VERSION "HNNBNNNYNNNNNNNNNNNNNNNNNNNNNNNNNNNNNNNNNN/4/%%%/4/'%**4NNN///"

NS_ :

BS_:

BU_: Radar MPC2

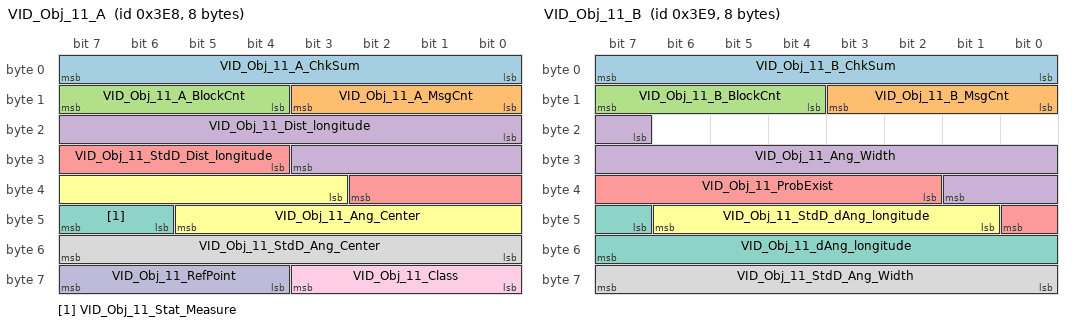
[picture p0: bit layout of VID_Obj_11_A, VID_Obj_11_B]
BO_ 1000 VID_Obj_11_A: 8 MPC2
 SG_ VID_Obj_11_A_ChkSum : 0|8@1+ (1,0) [0|255] ""  Radar
 SG_ VID_Obj_11_A_MsgCnt : 8|4@1+ (1,0) [0|15] ""  Radar
 SG_ VID_Obj_11_A_BlockCnt : 12|4@1+ (1,0) [0|15] ""  Radar
 SG_ VID_Obj_11_Dist_longitude : 16|12@1+ (0.0625,0) [0|255.875] "Unit_Meter"  Radar
 SG_ VID_Obj_11_StdD_Dist_longitude : 28|7@1+ (0.25,0) [0|31.5] "Unit_Meter"  Radar
 SG_ VID_Obj_11_Ang_Center : 35|11@1+ (0.00048828125,-0.5) [-0.5|0.4990234375] "Unit_Radia"  Radar
 SG_ VID_Obj_11_Stat_Measure : 46|2@1+ (1,0) [0|3] ""  Radar
 SG_ VID_Obj_11_StdD_Ang_Center : 48|8@1+ (0.0009765625,0) [0|0.248046875] "Unit_Radia"  Radar
 SG_ VID_Obj_11_Class : 56|4@1+ (1,0) [0|15] ""  Radar
 SG_ VID_Obj_11_RefPoint : 60|4@1+ (1,0) [0|15] ""  Radar

BO_ 1001 VID_Obj_11_B: 8 MPC2
 SG_ VID_Obj_11_B_ChkSum : 0|8@1+ (1,0) [0|255] ""  Radar
 SG_ VID_Obj_11_B_MsgCnt : 8|4@1+ (1,0) [0|15] ""  Radar
 SG_ VID_Obj_11_B_BlockCnt : 12|4@1+ (1,0) [0|15] ""  Radar
 SG_ VID_Obj_11_Ang_Width : 23|11@1+ (0.00048828125,0) [0|0.9990234375] "Unit_Radia"  Radar
 SG_ VID_Obj_11_ProbExist : 34|7@1+ (0.0078125,0.015625) [0.015625|1] ""  Radar
 SG_ VID_Obj_11_StdD_dAng_longitude : 41|6@1+ (0.01,0) [0|0.62] "Unit_RadiaPerSecon"  Radar
 SG_ VID_Obj_11_dAng_longitude : 47|9@1+ (0.005,-1.25) [-1.25|1.3] "Unit_RadiaPerSecon"  Radar
 SG_ VID_Obj_11_StdD_Ang_Width : 56|8@1+ (0.0009765625,0) [0|0.248046875] "Unit_Radia"  Radar

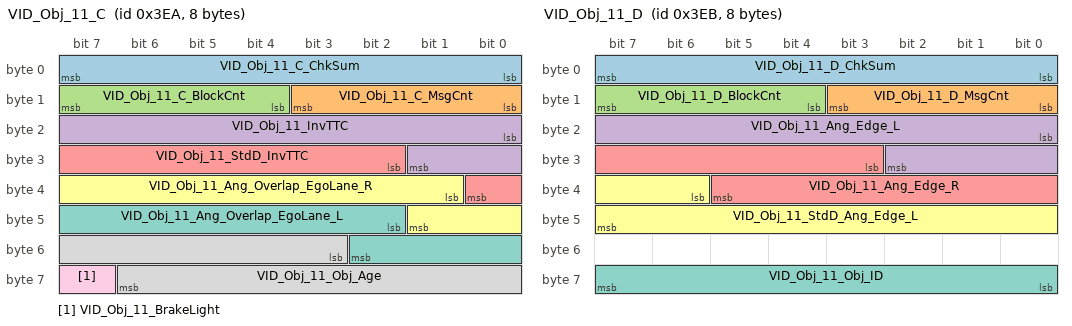
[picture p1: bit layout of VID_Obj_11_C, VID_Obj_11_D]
BO_ 1002 VID_Obj_11_C: 8 MPC2
 SG_ VID_Obj_11_C_ChkSum : 0|8@1+ (1,0) [0|255] ""  Radar
 SG_ VID_Obj_11_C_MsgCnt : 8|4@1+ (1,0) [0|15] ""  Radar
 SG_ VID_Obj_11_C_BlockCnt : 12|4@1+ (1,0) [0|15] ""  Radar
 SG_ VID_Obj_11_InvTTC : 16|10@1+ (0.015625,-8) [-8|7.96875] "Unit_Hertz"  Radar
 SG_ VID_Obj_11_StdD_InvTTC : 26|7@1+ (0.0625,0) [0|7.875] "Unit_Hertz"  Radar
 SG_ VID_Obj_11_Ang_Overlap_EgoLane_R : 33|9@1+ (0.0009765625,-0.25) [-0.25|0.248046875] "Unit_Radia"  Radar
 SG_ VID_Obj_11_Ang_Overlap_EgoLane_L : 42|9@1+ (0.0009765625,-0.25) [-0.25|0.248046875] "Unit_Radia"  Radar
 SG_ VID_Obj_11_Obj_Age : 51|12@1+ (1,0) [0|4094] ""  Radar
 SG_ VID_Obj_11_BrakeLight : 63|1@1+ (1,0) [0|1] ""  Radar

BO_ 1003 VID_Obj_11_D: 8 MPC2
 SG_ VID_Obj_11_D_ChkSum : 0|8@1+ (1,0) [0|255] ""  Radar
 SG_ VID_Obj_11_D_MsgCnt : 8|4@1+ (1,0) [0|15] ""  Radar
 SG_ VID_Obj_11_D_BlockCnt : 12|4@1+ (1,0) [0|15] ""  Radar
 SG_ VID_Obj_11_Ang_Edge_L : 16|11@1+ (0.00048828125,-0.5) [-0.5|0.49951171875] "Unit_Radia"  Radar
 SG_ VID_Obj_11_Ang_Edge_R : 27|11@1+ (0.00048828125,-0.5) [-0.5|0.49951171875] "Unit_Radia"  Radar
 SG_ VID_Obj_11_StdD_Ang_Edge_L : 38|10@1+ (0.00048828125,-0.25) [-0.25|0.24951171875] "Unit_Radia"  Radar
 SG_ VID_Obj_11_Obj_ID : 56|8@1+ (1,0) [1|254] ""  Radar

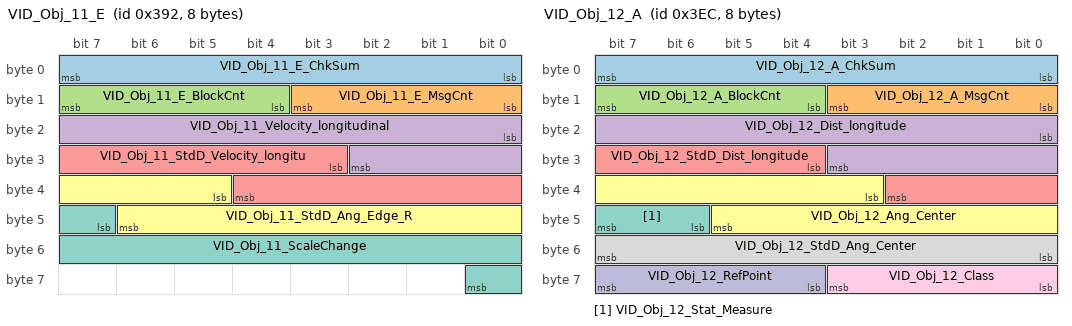
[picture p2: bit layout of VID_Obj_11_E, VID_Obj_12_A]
BO_ 914 VID_Obj_11_E: 8 MPC2
 SG_ VID_Obj_11_E_ChkSum : 0|8@1+ (1,0) [0|255] ""  Radar
 SG_ VID_Obj_11_E_MsgCnt : 8|4@1+ (1,0) [0|15] ""  Radar
 SG_ VID_Obj_11_E_BlockCnt : 12|4@1+ (1,0) [0|15] ""  Radar
 SG_ VID_Obj_11_Velocity_longitudinal : 16|11@1+ (0.01388889,-12) [-12|12.00000192] "Unit_MeterPerSecon"  Radar
 SG_ VID_Obj_11_StdD_Velocity_longitu : 27|10@1+ (0.00694444,0) [0|6.0069406] "Unit_MeterPerSecon"  Radar
 SG_ VID_Obj_11_StdD_Ang_Edge_R : 37|10@1+ (0.00048828125,-0.25) [-0.25|0.24951171875] "Unit_Radia"  Radar
 SG_ VID_Obj_11_ScaleChange : 47|10@1+ (0.001,0.5) [0.5|1.5] ""  Radar

BO_ 1004 VID_Obj_12_A: 8 MPC2
 SG_ VID_Obj_12_A_ChkSum : 0|8@1+ (1,0) [0|255] ""  Radar
 SG_ VID_Obj_12_A_MsgCnt : 8|4@1+ (1,0) [0|15] ""  Radar
 SG_ VID_Obj_12_A_BlockCnt : 12|4@1+ (1,0) [0|15] ""  Radar
 SG_ VID_Obj_12_Dist_longitude : 16|12@1+ (0.0625,0) [0|255.875] "Unit_Meter"  Radar
 SG_ VID_Obj_12_StdD_Dist_longitude : 28|7@1+ (0.25,0) [0|31.5] "Unit_Meter"  Radar
 SG_ VID_Obj_12_Ang_Center : 35|11@1+ (0.00048828125,-0.5) [-0.5|0.4990234375] "Unit_Radia"  Radar
 SG_ VID_Obj_12_Stat_Measure : 46|2@1+ (1,0) [0|3] ""  Radar
 SG_ VID_Obj_12_StdD_Ang_Center : 48|8@1+ (0.0009765625,0) [0|0.248046875] "Unit_Radia"  Radar
 SG_ VID_Obj_12_Class : 56|4@1+ (1,0) [0|15] ""  Radar
 SG_ VID_Obj_12_RefPoint : 60|4@1+ (1,0) [0|15] ""  Radar

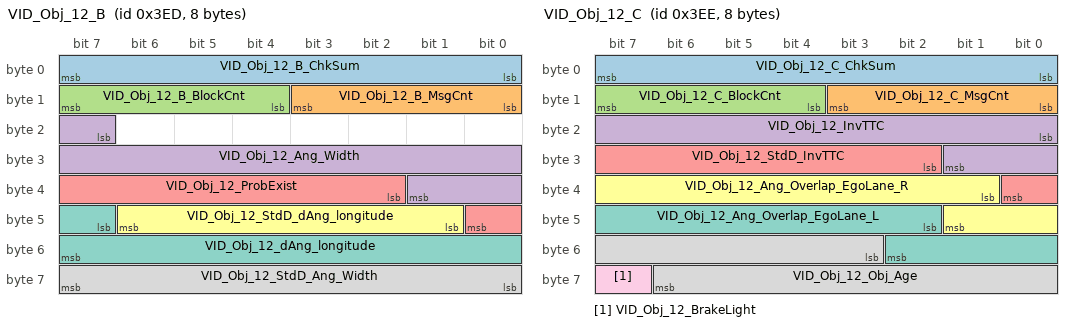
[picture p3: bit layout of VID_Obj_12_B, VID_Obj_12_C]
BO_ 1005 VID_Obj_12_B: 8 MPC2
 SG_ VID_Obj_12_B_ChkSum : 0|8@1+ (1,0) [0|255] ""  Radar
 SG_ VID_Obj_12_B_MsgCnt : 8|4@1+ (1,0) [0|15] ""  Radar
 SG_ VID_Obj_12_B_BlockCnt : 12|4@1+ (1,0) [0|15] ""  Radar
 SG_ VID_Obj_12_Ang_Width : 23|11@1+ (0.00048828125,0) [0|0.9990234375] "Unit_Radia"  Radar
 SG_ VID_Obj_12_ProbExist : 34|7@1+ (0.0078125,0.015625) [0.015625|1] ""  Radar
 SG_ VID_Obj_12_StdD_dAng_longitude : 41|6@1+ (0.01,0) [0|0.62] "Unit_RadiaPerSecon"  Radar
 SG_ VID_Obj_12_dAng_longitude : 47|9@1+ (0.005,-1.25) [-1.25|1.3] "Unit_RadiaPerSecon"  Radar
 SG_ VID_Obj_12_StdD_Ang_Width : 56|8@1+ (0.0009765625,0) [0|0.248046875] "Unit_Radia"  Radar

BO_ 1006 VID_Obj_12_C: 8 MPC2
 SG_ VID_Obj_12_C_ChkSum : 0|8@1+ (1,0) [0|255] ""  Radar
 SG_ VID_Obj_12_C_MsgCnt : 8|4@1+ (1,0) [0|15] ""  Radar
 SG_ VID_Obj_12_C_BlockCnt : 12|4@1+ (1,0) [0|15] ""  Radar
 SG_ VID_Obj_12_InvTTC : 16|10@1+ (0.015625,-8) [-8|7.96875] "Unit_Hertz"  Radar
 SG_ VID_Obj_12_StdD_InvTTC : 26|7@1+ (0.0625,0) [0|7.875] "Unit_Hertz"  Radar
 SG_ VID_Obj_12_Ang_Overlap_EgoLane_R : 33|9@1+ (0.0009765625,-0.25) [-0.25|0.248046875] "Unit_Radia"  Radar
 SG_ VID_Obj_12_Ang_Overlap_EgoLane_L : 42|9@1+ (0.0009765625,-0.25) [-0.25|0.248046875] "Unit_Radia"  Radar
 SG_ VID_Obj_12_Obj_Age : 51|12@1+ (1,0) [0|4094] ""  Radar
 SG_ VID_Obj_12_BrakeLight : 63|1@1+ (1,0) [0|1] ""  Radar

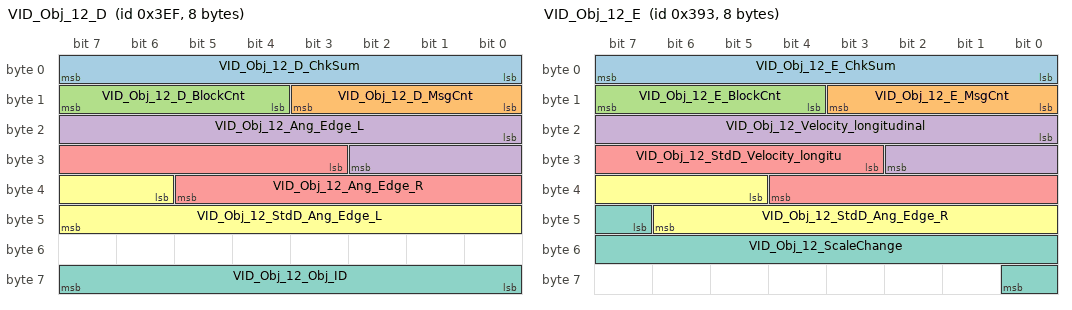
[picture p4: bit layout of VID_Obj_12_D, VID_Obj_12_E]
BO_ 1007 VID_Obj_12_D: 8 MPC2
 SG_ VID_Obj_12_D_ChkSum : 0|8@1+ (1,0) [0|255] ""  Radar
 SG_ VID_Obj_12_D_MsgCnt : 8|4@1+ (1,0) [0|15] ""  Radar
 SG_ VID_Obj_12_D_BlockCnt : 12|4@1+ (1,0) [0|15] ""  Radar
 SG_ VID_Obj_12_Ang_Edge_L : 16|11@1+ (0.00048828125,-0.5) [-0.5|0.49951171875] "Unit_Radia"  Radar
 SG_ VID_Obj_12_Ang_Edge_R : 27|11@1+ (0.00048828125,-0.5) [-0.5|0.49951171875] "Unit_Radia"  Radar
 SG_ VID_Obj_12_StdD_Ang_Edge_L : 38|10@1+ (0.00048828125,-0.25) [-0.25|0.24951171875] "Unit_Radia"  Radar
 SG_ VID_Obj_12_Obj_ID : 56|8@1+ (1,0) [1|254] ""  Radar

BO_ 915 VID_Obj_12_E: 8 MPC2
 SG_ VID_Obj_12_E_ChkSum : 0|8@1+ (1,0) [0|255] ""  Radar
 SG_ VID_Obj_12_E_MsgCnt : 8|4@1+ (1,0) [0|15] ""  Radar
 SG_ VID_Obj_12_E_BlockCnt : 12|4@1+ (1,0) [0|15] ""  Radar
 SG_ VID_Obj_12_Velocity_longitudinal : 16|11@1+ (0.01388889,-12) [-12|12.00000192] "Unit_MeterPerSecon"  Radar
 SG_ VID_Obj_12_StdD_Velocity_longitu : 27|10@1+ (0.00694444,0) [0|6.0069406] "Unit_MeterPerSecon"  Radar
 SG_ VID_Obj_12_StdD_Ang_Edge_R : 37|10@1+ (0.00048828125,-0.25) [-0.25|0.24951171875] "Unit_Radia"  Radar
 SG_ VID_Obj_12_ScaleChange : 47|10@1+ (0.001,0.5) [0.5|1.5] ""  Radar

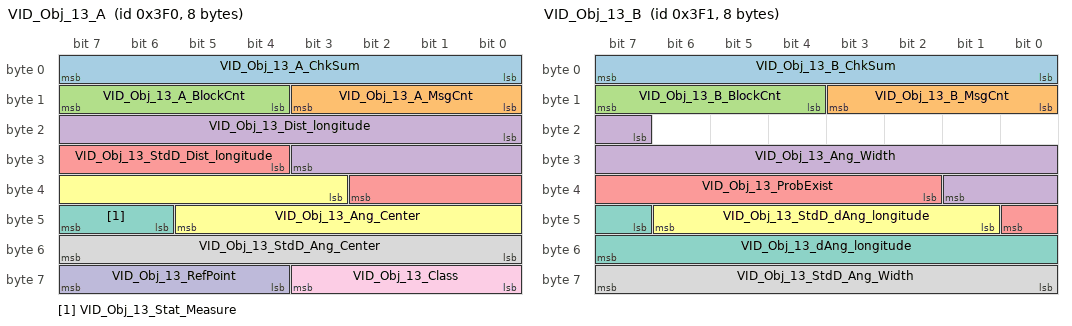
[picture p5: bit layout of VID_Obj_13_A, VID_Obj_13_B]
BO_ 1008 VID_Obj_13_A: 8 MPC2
 SG_ VID_Obj_13_A_ChkSum : 0|8@1+ (1,0) [0|255] ""  Radar
 SG_ VID_Obj_13_A_MsgCnt : 8|4@1+ (1,0) [0|15] ""  Radar
 SG_ VID_Obj_13_A_BlockCnt : 12|4@1+ (1,0) [0|15] ""  Radar
 SG_ VID_Obj_13_Dist_longitude : 16|12@1+ (0.0625,0) [0|255.875] "Unit_Meter"  Radar
 SG_ VID_Obj_13_StdD_Dist_longitude : 28|7@1+ (0.25,0) [0|31.5] "Unit_Meter"  Radar
 SG_ VID_Obj_13_Ang_Center : 35|11@1+ (0.00048828125,-0.5) [-0.5|0.4990234375] "Unit_Radia"  Radar
 SG_ VID_Obj_13_Stat_Measure : 46|2@1+ (1,0) [0|3] ""  Radar
 SG_ VID_Obj_13_StdD_Ang_Center : 48|8@1+ (0.0009765625,0) [0|0.248046875] "Unit_Radia"  Radar
 SG_ VID_Obj_13_Class : 56|4@1+ (1,0) [0|15] ""  Radar
 SG_ VID_Obj_13_RefPoint : 60|4@1+ (1,0) [0|15] ""  Radar

BO_ 1009 VID_Obj_13_B: 8 MPC2
 SG_ VID_Obj_13_B_ChkSum : 0|8@1+ (1,0) [0|255] ""  Radar
 SG_ VID_Obj_13_B_MsgCnt : 8|4@1+ (1,0) [0|15] ""  Radar
 SG_ VID_Obj_13_B_BlockCnt : 12|4@1+ (1,0) [0|15] ""  Radar
 SG_ VID_Obj_13_Ang_Width : 23|11@1+ (0.00048828125,0) [0|0.9990234375] "Unit_Radia"  Radar
 SG_ VID_Obj_13_ProbExist : 34|7@1+ (0.0078125,0.015625) [0.015625|1] ""  Radar
 SG_ VID_Obj_13_StdD_dAng_longitude : 41|6@1+ (0.01,0) [0|0.62] "Unit_RadiaPerSecon"  Radar
 SG_ VID_Obj_13_dAng_longitude : 47|9@1+ (0.005,-1.25) [-1.25|1.3] "Unit_RadiaPerSecon"  Radar
 SG_ VID_Obj_13_StdD_Ang_Width : 56|8@1+ (0.0009765625,0) [0|0.248046875] "Unit_Radia"  Radar

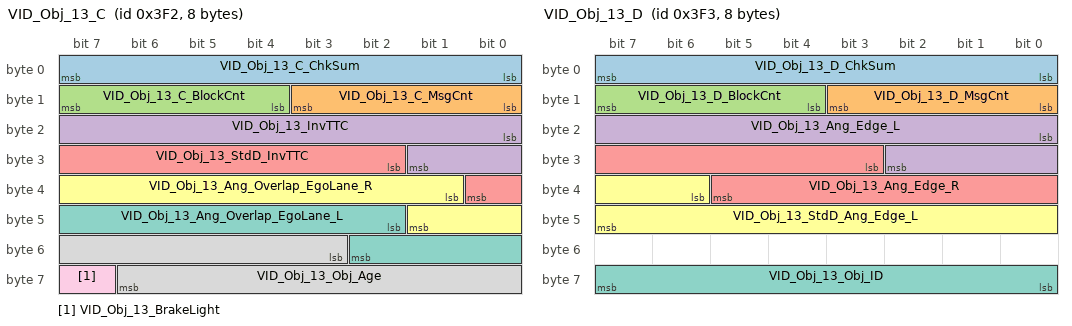
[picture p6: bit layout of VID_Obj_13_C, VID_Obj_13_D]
BO_ 1010 VID_Obj_13_C: 8 MPC2
 SG_ VID_Obj_13_C_ChkSum : 0|8@1+ (1,0) [0|255] ""  Radar
 SG_ VID_Obj_13_C_MsgCnt : 8|4@1+ (1,0) [0|15] ""  Radar
 SG_ VID_Obj_13_C_BlockCnt : 12|4@1+ (1,0) [0|15] ""  Radar
 SG_ VID_Obj_13_InvTTC : 16|10@1+ (0.015625,-8) [-8|7.96875] "Unit_Hertz"  Radar
 SG_ VID_Obj_13_StdD_InvTTC : 26|7@1+ (0.0625,0) [0|7.875] "Unit_Hertz"  Radar
 SG_ VID_Obj_13_Ang_Overlap_EgoLane_R : 33|9@1+ (0.0009765625,-0.25) [-0.25|0.248046875] "Unit_Radia"  Radar
 SG_ VID_Obj_13_Ang_Overlap_EgoLane_L : 42|9@1+ (0.0009765625,-0.25) [-0.25|0.248046875] "Unit_Radia"  Radar
 SG_ VID_Obj_13_Obj_Age : 51|12@1+ (1,0) [0|4094] ""  Radar
 SG_ VID_Obj_13_BrakeLight : 63|1@1+ (1,0) [0|1] ""  Radar

BO_ 1011 VID_Obj_13_D: 8 MPC2
 SG_ VID_Obj_13_D_ChkSum : 0|8@1+ (1,0) [0|255] ""  Radar
 SG_ VID_Obj_13_D_MsgCnt : 8|4@1+ (1,0) [0|15] ""  Radar
 SG_ VID_Obj_13_D_BlockCnt : 12|4@1+ (1,0) [0|15] ""  Radar
 SG_ VID_Obj_13_Ang_Edge_L : 16|11@1+ (0.00048828125,-0.5) [-0.5|0.49951171875] "Unit_Radia"  Radar
 SG_ VID_Obj_13_Ang_Edge_R : 27|11@1+ (0.00048828125,-0.5) [-0.5|0.49951171875] "Unit_Radia"  Radar
 SG_ VID_Obj_13_StdD_Ang_Edge_L : 38|10@1+ (0.00048828125,-0.25) [-0.25|0.24951171875] "Unit_Radia"  Radar
 SG_ VID_Obj_13_Obj_ID : 56|8@1+ (1,0) [1|254] ""  Radar

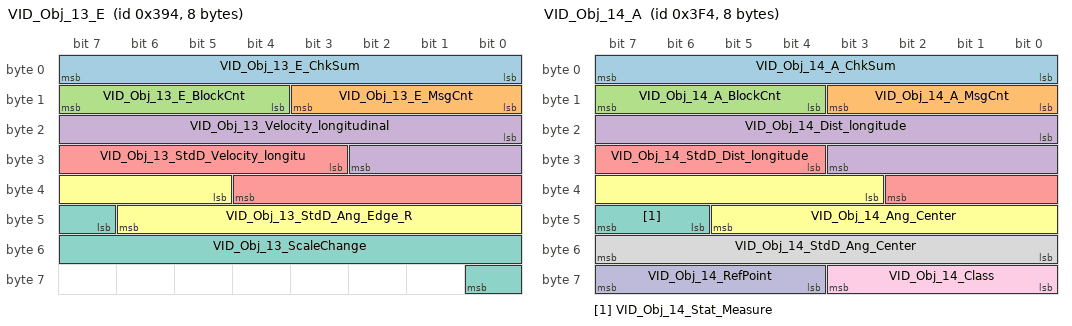
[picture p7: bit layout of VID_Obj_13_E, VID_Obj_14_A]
BO_ 916 VID_Obj_13_E: 8 MPC2
 SG_ VID_Obj_13_E_ChkSum : 0|8@1+ (1,0) [0|255] ""  Radar
 SG_ VID_Obj_13_E_MsgCnt : 8|4@1+ (1,0) [0|15] ""  Radar
 SG_ VID_Obj_13_E_BlockCnt : 12|4@1+ (1,0) [0|15] ""  Radar
 SG_ VID_Obj_13_Velocity_longitudinal : 16|11@1+ (0.01388889,-12) [-12|12.00000192] "Unit_MeterPerSecon"  Radar
 SG_ VID_Obj_13_StdD_Velocity_longitu : 27|10@1+ (0.00694444,0) [0|6.0069406] "Unit_MeterPerSecon"  Radar
 SG_ VID_Obj_13_StdD_Ang_Edge_R : 37|10@1+ (0.00048828125,-0.25) [-0.25|0.24951171875] "Unit_Radia"  Radar
 SG_ VID_Obj_13_ScaleChange : 47|10@1+ (0.001,0.5) [0.5|1.5] ""  Radar

BO_ 1012 VID_Obj_14_A: 8 MPC2
 SG_ VID_Obj_14_A_ChkSum : 0|8@1+ (1,0) [0|255] ""  Radar
 SG_ VID_Obj_14_A_MsgCnt : 8|4@1+ (1,0) [0|15] ""  Radar
 SG_ VID_Obj_14_A_BlockCnt : 12|4@1+ (1,0) [0|15] ""  Radar
 SG_ VID_Obj_14_Dist_longitude : 16|12@1+ (0.0625,0) [0|255.875] "Unit_Meter"  Radar
 SG_ VID_Obj_14_StdD_Dist_longitude : 28|7@1+ (0.25,0) [0|31.5] "Unit_Meter"  Radar
 SG_ VID_Obj_14_Ang_Center : 35|11@1+ (0.00048828125,-0.5) [-0.5|0.4990234375] "Unit_Radia"  Radar
 SG_ VID_Obj_14_Stat_Measure : 46|2@1+ (1,0) [0|3] ""  Radar
 SG_ VID_Obj_14_StdD_Ang_Center : 48|8@1+ (0.0009765625,0) [0|0.248046875] "Unit_Radia"  Radar
 SG_ VID_Obj_14_Class : 56|4@1+ (1,0) [0|15] ""  Radar
 SG_ VID_Obj_14_RefPoint : 60|4@1+ (1,0) [0|15] ""  Radar

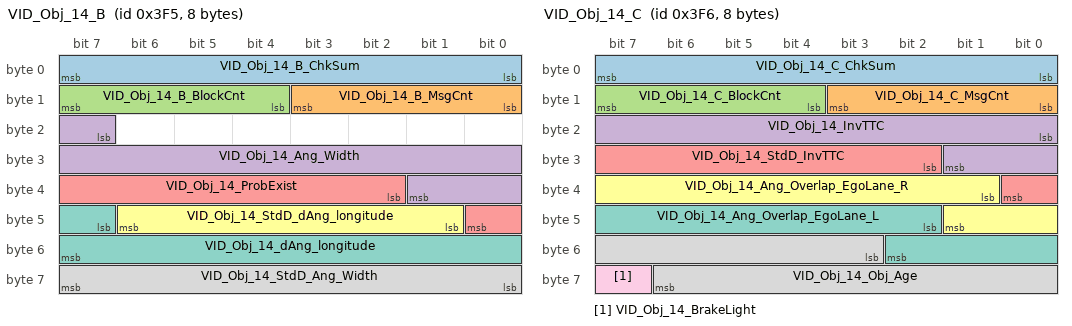
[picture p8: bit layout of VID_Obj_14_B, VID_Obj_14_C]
BO_ 1013 VID_Obj_14_B: 8 MPC2
 SG_ VID_Obj_14_B_ChkSum : 0|8@1+ (1,0) [0|255] ""  Radar
 SG_ VID_Obj_14_B_MsgCnt : 8|4@1+ (1,0) [0|15] ""  Radar
 SG_ VID_Obj_14_B_BlockCnt : 12|4@1+ (1,0) [0|15] ""  Radar
 SG_ VID_Obj_14_Ang_Width : 23|11@1+ (0.00048828125,0) [0|0.9990234375] "Unit_Radia"  Radar
 SG_ VID_Obj_14_ProbExist : 34|7@1+ (0.0078125,0.015625) [0.015625|1] ""  Radar
 SG_ VID_Obj_14_StdD_dAng_longitude : 41|6@1+ (0.01,0) [0|0.62] "Unit_RadiaPerSecon"  Radar
 SG_ VID_Obj_14_dAng_longitude : 47|9@1+ (0.005,-1.25) [-1.25|1.3] "Unit_RadiaPerSecon"  Radar
 SG_ VID_Obj_14_StdD_Ang_Width : 56|8@1+ (0.0009765625,0) [0|0.248046875] "Unit_Radia"  Radar

BO_ 1014 VID_Obj_14_C: 8 MPC2
 SG_ VID_Obj_14_C_ChkSum : 0|8@1+ (1,0) [0|255] ""  Radar
 SG_ VID_Obj_14_C_MsgCnt : 8|4@1+ (1,0) [0|15] ""  Radar
 SG_ VID_Obj_14_C_BlockCnt : 12|4@1+ (1,0) [0|15] ""  Radar
 SG_ VID_Obj_14_InvTTC : 16|10@1+ (0.015625,-8) [-8|7.96875] "Unit_Hertz"  Radar
 SG_ VID_Obj_14_StdD_InvTTC : 26|7@1+ (0.0625,0) [0|7.875] "Unit_Hertz"  Radar
 SG_ VID_Obj_14_Ang_Overlap_EgoLane_R : 33|9@1+ (0.0009765625,-0.25) [-0.25|0.248046875] "Unit_Radia"  Radar
 SG_ VID_Obj_14_Ang_Overlap_EgoLane_L : 42|9@1+ (0.0009765625,-0.25) [-0.25|0.248046875] "Unit_Radia"  Radar
 SG_ VID_Obj_14_Obj_Age : 51|12@1+ (1,0) [0|4094] ""  Radar
 SG_ VID_Obj_14_BrakeLight : 63|1@1+ (1,0) [0|1] ""  Radar

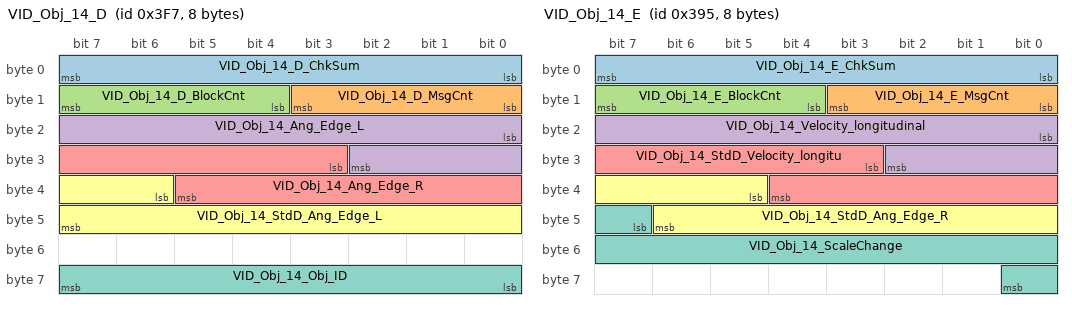
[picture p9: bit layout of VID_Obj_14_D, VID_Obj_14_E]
BO_ 1015 VID_Obj_14_D: 8 MPC2
 SG_ VID_Obj_14_D_ChkSum : 0|8@1+ (1,0) [0|255] ""  Radar
 SG_ VID_Obj_14_D_MsgCnt : 8|4@1+ (1,0) [0|15] ""  Radar
 SG_ VID_Obj_14_D_BlockCnt : 12|4@1+ (1,0) [0|15] ""  Radar
 SG_ VID_Obj_14_Ang_Edge_L : 16|11@1+ (0.00048828125,-0.5) [-0.5|0.49951171875] "Unit_Radia"  Radar
 SG_ VID_Obj_14_Ang_Edge_R : 27|11@1+ (0.00048828125,-0.5) [-0.5|0.49951171875] "Unit_Radia"  Radar
 SG_ VID_Obj_14_StdD_Ang_Edge_L : 38|10@1+ (0.00048828125,-0.25) [-0.25|0.24951171875] "Unit_Radia"  Radar
 SG_ VID_Obj_14_Obj_ID : 56|8@1+ (1,0) [1|254] ""  Radar

BO_ 917 VID_Obj_14_E: 8 MPC2
 SG_ VID_Obj_14_E_ChkSum : 0|8@1+ (1,0) [0|255] ""  Radar
 SG_ VID_Obj_14_E_MsgCnt : 8|4@1+ (1,0) [0|15] ""  Radar
 SG_ VID_Obj_14_E_BlockCnt : 12|4@1+ (1,0) [0|15] ""  Radar
 SG_ VID_Obj_14_Velocity_longitudinal : 16|11@1+ (0.01388889,-12) [-12|12.00000192] "Unit_MeterPerSecon"  Radar
 SG_ VID_Obj_14_StdD_Velocity_longitu : 27|10@1+ (0.00694444,0) [0|6.0069406] "Unit_MeterPerSecon"  Radar
 SG_ VID_Obj_14_StdD_Ang_Edge_R : 37|10@1+ (0.00048828125,-0.25) [-0.25|0.24951171875] "Unit_Radia"  Radar
 SG_ VID_Obj_14_ScaleChange : 47|10@1+ (0.001,0.5) [0.5|1.5] ""  Radar

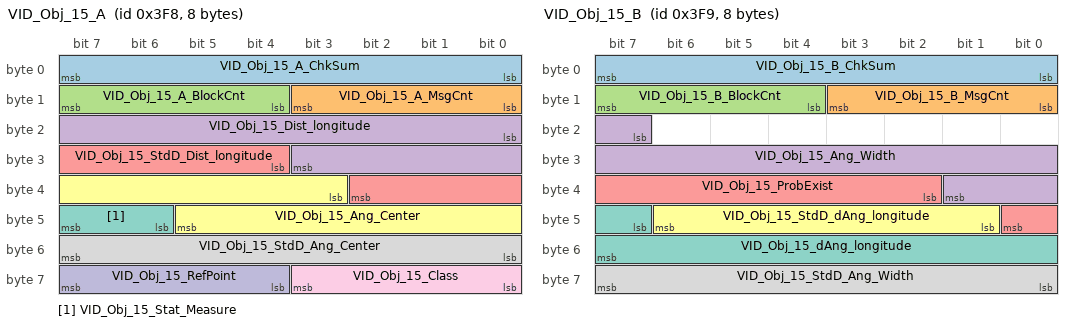
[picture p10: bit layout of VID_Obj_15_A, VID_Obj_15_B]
BO_ 1016 VID_Obj_15_A: 8 MPC2
 SG_ VID_Obj_15_A_ChkSum : 0|8@1+ (1,0) [0|255] ""  Radar
 SG_ VID_Obj_15_A_MsgCnt : 8|4@1+ (1,0) [0|15] ""  Radar
 SG_ VID_Obj_15_A_BlockCnt : 12|4@1+ (1,0) [0|15] ""  Radar
 SG_ VID_Obj_15_Dist_longitude : 16|12@1+ (0.0625,0) [0|255.875] "Unit_Meter"  Radar
 SG_ VID_Obj_15_StdD_Dist_longitude : 28|7@1+ (0.25,0) [0|31.5] "Unit_Meter"  Radar
 SG_ VID_Obj_15_Ang_Center : 35|11@1+ (0.00048828125,-0.5) [-0.5|0.4990234375] "Unit_Radia"  Radar
 SG_ VID_Obj_15_Stat_Measure : 46|2@1+ (1,0) [0|3] ""  Radar
 SG_ VID_Obj_15_StdD_Ang_Center : 48|8@1+ (0.0009765625,0) [0|0.248046875] "Unit_Radia"  Radar
 SG_ VID_Obj_15_Class : 56|4@1+ (1,0) [0|15] ""  Radar
 SG_ VID_Obj_15_RefPoint : 60|4@1+ (1,0) [0|15] ""  Radar

BO_ 1017 VID_Obj_15_B: 8 MPC2
 SG_ VID_Obj_15_B_ChkSum : 0|8@1+ (1,0) [0|255] ""  Radar
 SG_ VID_Obj_15_B_MsgCnt : 8|4@1+ (1,0) [0|15] ""  Radar
 SG_ VID_Obj_15_B_BlockCnt : 12|4@1+ (1,0) [0|15] ""  Radar
 SG_ VID_Obj_15_Ang_Width : 23|11@1+ (0.00048828125,0) [0|0.9990234375] "Unit_Radia"  Radar
 SG_ VID_Obj_15_ProbExist : 34|7@1+ (0.0078125,0.015625) [0.015625|1] ""  Radar
 SG_ VID_Obj_15_StdD_dAng_longitude : 41|6@1+ (0.01,0) [0|0.62] "Unit_RadiaPerSecon"  Radar
 SG_ VID_Obj_15_dAng_longitude : 47|9@1+ (0.005,-1.25) [-1.25|1.3] "Unit_RadiaPerSecon"  Radar
 SG_ VID_Obj_15_StdD_Ang_Width : 56|8@1+ (0.0009765625,0) [0|0.248046875] "Unit_Radia"  Radar

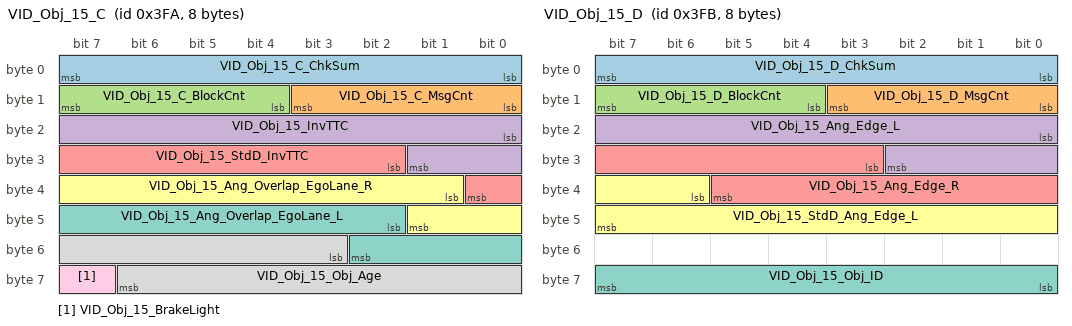
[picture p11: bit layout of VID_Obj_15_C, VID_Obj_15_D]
BO_ 1018 VID_Obj_15_C: 8 MPC2
 SG_ VID_Obj_15_C_ChkSum : 0|8@1+ (1,0) [0|255] ""  Radar
 SG_ VID_Obj_15_C_MsgCnt : 8|4@1+ (1,0) [0|15] ""  Radar
 SG_ VID_Obj_15_C_BlockCnt : 12|4@1+ (1,0) [0|15] ""  Radar
 SG_ VID_Obj_15_InvTTC : 16|10@1+ (0.015625,-8) [-8|7.96875] "Unit_Hertz"  Radar
 SG_ VID_Obj_15_StdD_InvTTC : 26|7@1+ (0.0625,0) [0|7.875] "Unit_Hertz"  Radar
 SG_ VID_Obj_15_Ang_Overlap_EgoLane_R : 33|9@1+ (0.0009765625,-0.25) [-0.25|0.248046875] "Unit_Radia"  Radar
 SG_ VID_Obj_15_Ang_Overlap_EgoLane_L : 42|9@1+ (0.0009765625,-0.25) [-0.25|0.248046875] "Unit_Radia"  Radar
 SG_ VID_Obj_15_Obj_Age : 51|12@1+ (1,0) [0|4094] ""  Radar
 SG_ VID_Obj_15_BrakeLight : 63|1@1+ (1,0) [0|1] ""  Radar

BO_ 1019 VID_Obj_15_D: 8 MPC2
 SG_ VID_Obj_15_D_ChkSum : 0|8@1+ (1,0) [0|255] ""  Radar
 SG_ VID_Obj_15_D_MsgCnt : 8|4@1+ (1,0) [0|15] ""  Radar
 SG_ VID_Obj_15_D_BlockCnt : 12|4@1+ (1,0) [0|15] ""  Radar
 SG_ VID_Obj_15_Ang_Edge_L : 16|11@1+ (0.00048828125,-0.5) [-0.5|0.49951171875] "Unit_Radia"  Radar
 SG_ VID_Obj_15_Ang_Edge_R : 27|11@1+ (0.00048828125,-0.5) [-0.5|0.49951171875] "Unit_Radia"  Radar
 SG_ VID_Obj_15_StdD_Ang_Edge_L : 38|10@1+ (0.00048828125,-0.25) [-0.25|0.24951171875] "Unit_Radia"  Radar
 SG_ VID_Obj_15_Obj_ID : 56|8@1+ (1,0) [1|254] ""  Radar

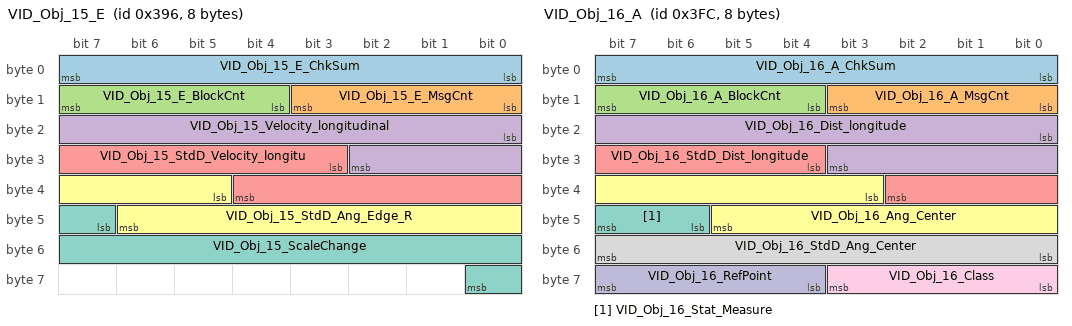
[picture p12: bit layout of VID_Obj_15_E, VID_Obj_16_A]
BO_ 918 VID_Obj_15_E: 8 MPC2
 SG_ VID_Obj_15_E_ChkSum : 0|8@1+ (1,0) [0|255] ""  Radar
 SG_ VID_Obj_15_E_MsgCnt : 8|4@1+ (1,0) [0|15] ""  Radar
 SG_ VID_Obj_15_E_BlockCnt : 12|4@1+ (1,0) [0|15] ""  Radar
 SG_ VID_Obj_15_Velocity_longitudinal : 16|11@1+ (0.01388889,-12) [-12|12.00000192] "Unit_MeterPerSecon"  Radar
 SG_ VID_Obj_15_StdD_Velocity_longitu : 27|10@1+ (0.00694444,0) [0|6.0069406] "Unit_MeterPerSecon"  Radar
 SG_ VID_Obj_15_StdD_Ang_Edge_R : 37|10@1+ (0.00048828125,-0.25) [-0.25|0.24951171875] "Unit_Radia"  Radar
 SG_ VID_Obj_15_ScaleChange : 47|10@1+ (0.001,0.5) [0.5|1.5] ""  Radar

BO_ 1020 VID_Obj_16_A: 8 MPC2
 SG_ VID_Obj_16_A_ChkSum : 0|8@1+ (1,0) [0|255] ""  Radar
 SG_ VID_Obj_16_A_MsgCnt : 8|4@1+ (1,0) [0|15] ""  Radar
 SG_ VID_Obj_16_A_BlockCnt : 12|4@1+ (1,0) [0|15] ""  Radar
 SG_ VID_Obj_16_Dist_longitude : 16|12@1+ (0.0625,0) [0|255.875] "Unit_Meter"  Radar
 SG_ VID_Obj_16_StdD_Dist_longitude : 28|7@1+ (0.25,0) [0|31.5] "Unit_Meter"  Radar
 SG_ VID_Obj_16_Ang_Center : 35|11@1+ (0.00048828125,-0.5) [-0.5|0.4990234375] "Unit_Radia"  Radar
 SG_ VID_Obj_16_Stat_Measure : 46|2@1+ (1,0) [0|3] ""  Radar
 SG_ VID_Obj_16_StdD_Ang_Center : 48|8@1+ (0.0009765625,0) [0|0.248046875] "Unit_Radia"  Radar
 SG_ VID_Obj_16_Class : 56|4@1+ (1,0) [0|15] ""  Radar
 SG_ VID_Obj_16_RefPoint : 60|4@1+ (1,0) [0|15] ""  Radar

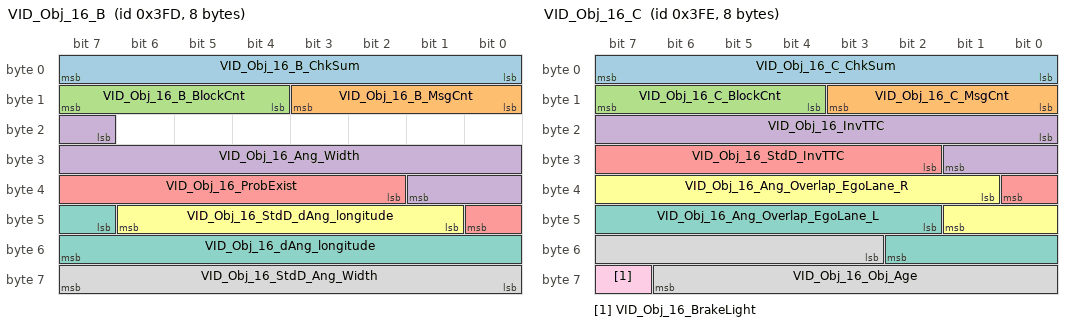
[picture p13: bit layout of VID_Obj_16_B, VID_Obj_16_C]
BO_ 1021 VID_Obj_16_B: 8 MPC2
 SG_ VID_Obj_16_B_ChkSum : 0|8@1+ (1,0) [0|255] ""  Radar
 SG_ VID_Obj_16_B_MsgCnt : 8|4@1+ (1,0) [0|15] ""  Radar
 SG_ VID_Obj_16_B_BlockCnt : 12|4@1+ (1,0) [0|15] ""  Radar
 SG_ VID_Obj_16_Ang_Width : 23|11@1+ (0.00048828125,0) [0|0.9990234375] "Unit_Radia"  Radar
 SG_ VID_Obj_16_ProbExist : 34|7@1+ (0.0078125,0.015625) [0.015625|1] ""  Radar
 SG_ VID_Obj_16_StdD_dAng_longitude : 41|6@1+ (0.01,0) [0|0.62] "Unit_RadiaPerSecon"  Radar
 SG_ VID_Obj_16_dAng_longitude : 47|9@1+ (0.005,-1.25) [-1.25|1.3] "Unit_RadiaPerSecon"  Radar
 SG_ VID_Obj_16_StdD_Ang_Width : 56|8@1+ (0.0009765625,0) [0|0.248046875] "Unit_Radia"  Radar

BO_ 1022 VID_Obj_16_C: 8 MPC2
 SG_ VID_Obj_16_C_ChkSum : 0|8@1+ (1,0) [0|255] ""  Radar
 SG_ VID_Obj_16_C_MsgCnt : 8|4@1+ (1,0) [0|15] ""  Radar
 SG_ VID_Obj_16_C_BlockCnt : 12|4@1+ (1,0) [0|15] ""  Radar
 SG_ VID_Obj_16_InvTTC : 16|10@1+ (0.015625,-8) [-8|7.96875] "Unit_Hertz"  Radar
 SG_ VID_Obj_16_StdD_InvTTC : 26|7@1+ (0.0625,0) [0|7.875] "Unit_Hertz"  Radar
 SG_ VID_Obj_16_Ang_Overlap_EgoLane_R : 33|9@1+ (0.0009765625,-0.25) [-0.25|0.248046875] "Unit_Radia"  Radar
 SG_ VID_Obj_16_Ang_Overlap_EgoLane_L : 42|9@1+ (0.0009765625,-0.25) [-0.25|0.248046875] "Unit_Radia"  Radar
 SG_ VID_Obj_16_Obj_Age : 51|12@1+ (1,0) [0|4094] ""  Radar
 SG_ VID_Obj_16_BrakeLight : 63|1@1+ (1,0) [0|1] ""  Radar

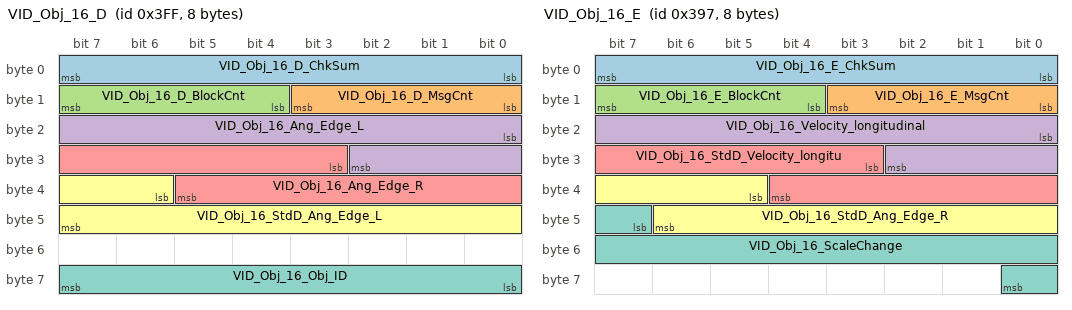
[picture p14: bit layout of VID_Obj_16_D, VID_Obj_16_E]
BO_ 1023 VID_Obj_16_D: 8 MPC2
 SG_ VID_Obj_16_D_ChkSum : 0|8@1+ (1,0) [0|255] ""  Radar
 SG_ VID_Obj_16_D_MsgCnt : 8|4@1+ (1,0) [0|15] ""  Radar
 SG_ VID_Obj_16_D_BlockCnt : 12|4@1+ (1,0) [0|15] ""  Radar
 SG_ VID_Obj_16_Ang_Edge_L : 16|11@1+ (0.00048828125,-0.5) [-0.5|0.49951171875] "Unit_Radia"  Radar
 SG_ VID_Obj_16_Ang_Edge_R : 27|11@1+ (0.00048828125,-0.5) [-0.5|0.49951171875] "Unit_Radia"  Radar
 SG_ VID_Obj_16_StdD_Ang_Edge_L : 38|10@1+ (0.00048828125,-0.25) [-0.25|0.24951171875] "Unit_Radia"  Radar
 SG_ VID_Obj_16_Obj_ID : 56|8@1+ (1,0) [1|254] ""  Radar

BO_ 919 VID_Obj_16_E: 8 MPC2
 SG_ VID_Obj_16_E_ChkSum : 0|8@1+ (1,0) [0|255] ""  Radar
 SG_ VID_Obj_16_E_MsgCnt : 8|4@1+ (1,0) [0|15] ""  Radar
 SG_ VID_Obj_16_E_BlockCnt : 12|4@1+ (1,0) [0|15] ""  Radar
 SG_ VID_Obj_16_Velocity_longitudinal : 16|11@1+ (0.01388889,-12) [-12|12.00000192] "Unit_MeterPerSecon"  Radar
 SG_ VID_Obj_16_StdD_Velocity_longitu : 27|10@1+ (0.00694444,0) [0|6.0069406] "Unit_MeterPerSecon"  Radar
 SG_ VID_Obj_16_StdD_Ang_Edge_R : 37|10@1+ (0.00048828125,-0.25) [-0.25|0.24951171875] "Unit_Radia"  Radar
 SG_ VID_Obj_16_ScaleChange : 47|10@1+ (0.001,0.5) [0.5|1.5] ""  Radar

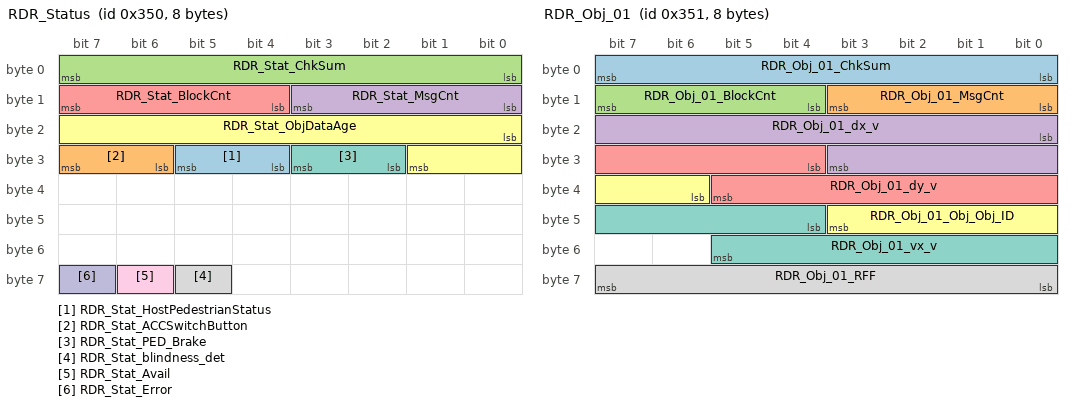
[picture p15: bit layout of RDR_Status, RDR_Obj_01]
BO_ 848 RDR_Status: 8 Radar
 SG_ RDR_Stat_HostPedestrianStatus : 28|2@1+ (1,0) [0|3] "" Vector__XXX
 SG_ RDR_Stat_ACCSwitchButton : 30|2@1+ (1,0) [0|3] "" Vector__XXX
 SG_ RDR_Stat_ChkSum : 0|8@1+ (1,0) [0|255] ""  MPC2
 SG_ RDR_Stat_MsgCnt : 8|4@1+ (1,0) [0|15] ""  MPC2
 SG_ RDR_Stat_BlockCnt : 12|4@1+ (1,0) [0|15] ""  MPC2
 SG_ RDR_Stat_ObjDataAge : 16|10@1+ (0.0009765625,0) [0|0.998046875] "Unit_Secon"  MPC2
 SG_ RDR_Stat_PED_Brake : 26|2@1+ (1,0) [0|3] ""  MPC2
 SG_ RDR_Stat_blindness_det : 61|1@1+ (1,0) [0|1] ""  MPC2
 SG_ RDR_Stat_Avail : 62|1@1+ (1,0) [0|1] ""  MPC2
 SG_ RDR_Stat_Error : 63|1@1+ (1,0) [0|1] ""  MPC2

BO_ 849 RDR_Obj_01: 8 Radar
 SG_ RDR_Obj_01_ChkSum : 0|8@1+ (1,0) [0|255] ""  MPC2
 SG_ RDR_Obj_01_MsgCnt : 8|4@1+ (1,0) [0|15] ""  MPC2
 SG_ RDR_Obj_01_BlockCnt : 12|4@1+ (1,0) [0|15] ""  MPC2
 SG_ RDR_Obj_01_dx_v : 16|12@1+ (0.0625,0) [0|255.9375] "Unit_Meter"  MPC2
 SG_ RDR_Obj_01_dy_v : 28|10@1+ (0.0625,-32) [-32|31.9375] "Unit_Meter"  MPC2
 SG_ RDR_Obj_01_Obj_Obj_ID : 38|6@1+ (1,0) [0|63] ""  MPC2
 SG_ RDR_Obj_01_vx_v : 44|10@1+ (0.25,-128) [-128|127.75] "Unit_MeterPerSecon"  MPC2
 SG_ RDR_Obj_01_RFF : 56|8@1+ (1,0) [0|255] ""  MPC2

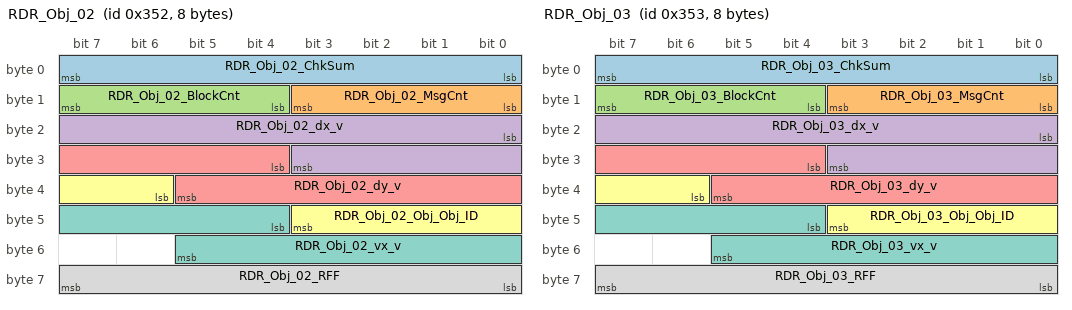
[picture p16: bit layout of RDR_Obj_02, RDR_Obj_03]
BO_ 850 RDR_Obj_02: 8 Radar
 SG_ RDR_Obj_02_ChkSum : 0|8@1+ (1,0) [0|255] ""  MPC2
 SG_ RDR_Obj_02_MsgCnt : 8|4@1+ (1,0) [0|15] ""  MPC2
 SG_ RDR_Obj_02_BlockCnt : 12|4@1+ (1,0) [0|15] ""  MPC2
 SG_ RDR_Obj_02_dx_v : 16|12@1+ (0.0625,0) [0|255.9375] "Unit_Meter"  MPC2
 SG_ RDR_Obj_02_dy_v : 28|10@1+ (0.0625,-32) [-32|31.9375] "Unit_Meter"  MPC2
 SG_ RDR_Obj_02_Obj_Obj_ID : 38|6@1+ (1,0) [0|63] ""  MPC2
 SG_ RDR_Obj_02_vx_v : 44|10@1+ (0.25,-128) [-128|127.75] "Unit_MeterPerSecon"  MPC2
 SG_ RDR_Obj_02_RFF : 56|8@1+ (1,0) [0|255] ""  MPC2

BO_ 851 RDR_Obj_03: 8 Radar
 SG_ RDR_Obj_03_ChkSum : 0|8@1+ (1,0) [0|255] ""  MPC2
 SG_ RDR_Obj_03_MsgCnt : 8|4@1+ (1,0) [0|15] ""  MPC2
 SG_ RDR_Obj_03_BlockCnt : 12|4@1+ (1,0) [0|15] ""  MPC2
 SG_ RDR_Obj_03_dx_v : 16|12@1+ (0.0625,0) [0|255.9375] "Unit_Meter"  MPC2
 SG_ RDR_Obj_03_dy_v : 28|10@1+ (0.0625,-32) [-32|31.9375] "Unit_Meter"  MPC2
 SG_ RDR_Obj_03_Obj_Obj_ID : 38|6@1+ (1,0) [0|63] ""  MPC2
 SG_ RDR_Obj_03_vx_v : 44|10@1+ (0.25,-128) [-128|127.75] "Unit_MeterPerSecon"  MPC2
 SG_ RDR_Obj_03_RFF : 56|8@1+ (1,0) [0|255] ""  MPC2

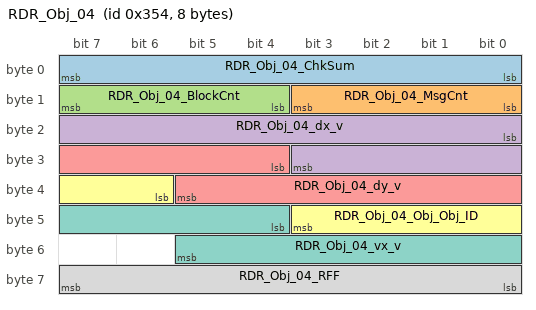
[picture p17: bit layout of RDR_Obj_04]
BO_ 852 RDR_Obj_04: 8 Radar
 SG_ RDR_Obj_04_ChkSum : 0|8@1+ (1,0) [0|255] ""  MPC2
 SG_ RDR_Obj_04_MsgCnt : 8|4@1+ (1,0) [0|15] ""  MPC2
 SG_ RDR_Obj_04_BlockCnt : 12|4@1+ (1,0) [0|15] ""  MPC2
 SG_ RDR_Obj_04_dx_v : 16|12@1+ (0.0625,0) [0|255.9375] "Unit_Meter"  MPC2
 SG_ RDR_Obj_04_dy_v : 28|10@1+ (0.0625,-32) [-32|31.9375] "Unit_Meter"  MPC2
 SG_ RDR_Obj_04_Obj_Obj_ID : 38|6@1+ (1,0) [0|63] ""  MPC2
 SG_ RDR_Obj_04_vx_v : 44|10@1+ (0.25,-128) [-128|127.75] "Unit_MeterPerSecon"  MPC2
 SG_ RDR_Obj_04_RFF : 56|8@1+ (1,0) [0|255] ""  MPC2

CM_ SG_ 1000 VID_Obj_11_A_ChkSum "CRC8 Checksum";
CM_ SG_ 1000 VID_Obj_11_A_MsgCnt "Message counter (rolling counter)";
CM_ SG_ 1000 VID_Obj_11_A_BlockCnt "Control signal to synchronize segmented blocks of object data";
CM_ SG_ 1000 VID_Obj_11_Dist_longitude "Longitudinal distance relative to vehicle coordinate system";
CM_ SG_ 1000 VID_Obj_11_StdD_Dist_longitude "Standard deviation for VID_Obj_11_Dist_longitude";
CM_ SG_ 1000 VID_Obj_11_Ang_Center "Center of the recorded side of the 3D-object box (positive angle left of x-axis).
(Mono-Video: Rear view for vehicles). In combination with Obj_Angle_low the center
base point of the objectis described.
Coordinate system: transformed";
CM_ SG_ 1000 VID_Obj_11_Stat_Measure "Object measured tracked

0 Object not measured but predicted based on 3D-model
1 Object was measured in current sample cycle
2 Object not measured but re-matched based on feature tracking";
CM_ SG_ 1000 VID_Obj_11_StdD_Ang_Center "Standard deviation for VID_Obj_11_Ang_Center";
CM_ SG_ 1000 VID_Obj_11_Class "Object class";
CM_ SG_ 1000 VID_Obj_11_RefPoint "Index of the reference point for the 3D-object box
Info: The wording front/rear right/left relates to the indicated object orientation.
If this data is not available then a orienntation can be chosen.";
CM_ SG_ 1001 VID_Obj_11_B_ChkSum "CRC8 Checksum";
CM_ SG_ 1001 VID_Obj_11_B_MsgCnt "Message counter (rolling counter)";
CM_ SG_ 1001 VID_Obj_11_B_BlockCnt "Control signal to synchronize segmented blocks of object data";
CM_ SG_ 1001 VID_Obj_11_Ang_Width "Width of the recorded side of the 3D-object box (positive angle left of x-axis)
Monovideo: Rear view for vehicles
Coordinate system: Transformed coordinate system with camera being origin
! Ego-movement has to be compensated !";
CM_ SG_ 1001 VID_Obj_11_ProbExist "Probability for the existence of an object for the given time and position (in 3sigma-area)";
CM_ SG_ 1001 VID_Obj_11_StdD_dAng_longitude "Standard deviation for VID_Obj_11_dAng_longitude";
CM_ SG_ 1001 VID_Obj_11_dAng_longitude "Lateral velocity of the object (related to the reference point), calculated as change of angle in the frame";
CM_ SG_ 1001 VID_Obj_11_StdD_Ang_Width "Standard deviation for VID_Obj_11_Ang_Width";
CM_ SG_ 1002 VID_Obj_11_C_ChkSum "CRC8 Checksum";
CM_ SG_ 1002 VID_Obj_11_C_MsgCnt "Message counter (rolling counter)";
CM_ SG_ 1002 VID_Obj_11_C_BlockCnt "Control signal to synchronize segmented blocks of object data";
CM_ SG_ 1002 VID_Obj_11_InvTTC "Inverted value of the time-to-collision with the vertical plane of the camera ";
CM_ SG_ 1002 VID_Obj_11_StdD_InvTTC "Standard deviation for VID_Obj_11_InvTTC";
CM_ SG_ 1002 VID_Obj_11_Ang_Overlap_EgoLane_R "Object Line Assignment (angle based indicator for the overlap of a an object with the ego lane from the right corner)";
CM_ SG_ 1002 VID_Obj_11_Ang_Overlap_EgoLane_L "Object Line Assignment (angle based indicator for the overlap of a an object with the ego lane from the left corner)";
CM_ SG_ 1002 VID_Obj_11_Obj_Age "Cycle counter for the existence of the object (object sampled)";
CM_ SG_ 1002 VID_Obj_11_BrakeLight "Brake light recognized on the object";
CM_ SG_ 1003 VID_Obj_11_D_ChkSum "CRC8 Checksum";
CM_ SG_ 1003 VID_Obj_11_D_MsgCnt "Message counter (rolling counter)";
CM_ SG_ 1003 VID_Obj_11_D_BlockCnt "Control signal to synchronize segmented blocks of object data";
CM_ SG_ 1003 VID_Obj_11_Ang_Edge_L "Angle of the left edge of the object
Conversion factor 2^-11";
CM_ SG_ 1003 VID_Obj_11_Ang_Edge_R "Angle of the right edge of the object
Conversion factor 2^-11";
CM_ SG_ 1003 VID_Obj_11_StdD_Ang_Edge_L "Standard deviation for the Angle of the left edge of the object";
CM_ SG_ 1003 VID_Obj_11_Obj_ID "ID of the object";
CM_ SG_ 914 VID_Obj_11_E_ChkSum "CRC8 Checksum";
CM_ SG_ 914 VID_Obj_11_E_MsgCnt "Message counter (rolling counter)";
CM_ SG_ 914 VID_Obj_11_E_BlockCnt "Control signal to synchronize segmented blocks of object data";
CM_ SG_ 914 VID_Obj_11_Velocity_longitudinal "Longitudinal velocity of the detected object (Vehicle coordinate system)";
CM_ SG_ 914 VID_Obj_11_StdD_Velocity_longitu "Standard deviation of the Longitudinal velocity of the detected object (Vehicle coordinate system)";
CM_ SG_ 914 VID_Obj_11_StdD_Ang_Edge_R "Standard deviation for the Angle of the right edge of the object";
CM_ SG_ 914 VID_Obj_11_ScaleChange "In order to fuse a video object with a radar object at higher distance (>60m), a higher resolution for the  relative velocity is needed in that range. This signal indicates the required change of the scale.";
CM_ SG_ 1004 VID_Obj_12_A_ChkSum "CRC8 Checksum";
CM_ SG_ 1004 VID_Obj_12_A_MsgCnt "Message counter (rolling counter)";
CM_ SG_ 1004 VID_Obj_12_A_BlockCnt "Control signal to synchronize segmented blocks of object data";
CM_ SG_ 1004 VID_Obj_12_Dist_longitude "Longitudinal distance relative to vehicle coordinate system";
CM_ SG_ 1004 VID_Obj_12_StdD_Dist_longitude "Standard deviation for VID_Obj_12_Dist_longitude";
CM_ SG_ 1004 VID_Obj_12_Ang_Center "Center of the recorded side of the 3D-object box (positive angle left of x-axis).
(Mono-Video: Rear view for vehicles). In combination with Obj_Angle_low the center
base point of the objectis described.
Coordinate system: transformed";
CM_ SG_ 1004 VID_Obj_12_Stat_Measure "Object measured tracked

0 Object not measured but predicted based on 3D-model
1 Object was measured in current sample cycle
2 Object not measured but re-matched based on feature tracking";
CM_ SG_ 1004 VID_Obj_12_StdD_Ang_Center "Standard deviation for VID_Obj_12_Ang_Center";
CM_ SG_ 1004 VID_Obj_12_Class "Object class";
CM_ SG_ 1004 VID_Obj_12_RefPoint "Index of the reference point for the 3D-object box
Info: The wording front/rear right/left relates to the indicated object orientation.
If this data is not available then a orienntation can be chosen.";
CM_ SG_ 1005 VID_Obj_12_B_ChkSum "CRC8 Checksum";
CM_ SG_ 1005 VID_Obj_12_B_MsgCnt "Message counter (rolling counter)";
CM_ SG_ 1005 VID_Obj_12_B_BlockCnt "Control signal to synchronize segmented blocks of object data";
CM_ SG_ 1005 VID_Obj_12_Ang_Width "Width of the recorded side of the 3D-object box (positive angle left of x-axis)
Monovideo: Rear view for vehicles
Coordinate system: Transformed coordinate system with camera being origin
! Ego-movement has to be compensated !";
CM_ SG_ 1005 VID_Obj_12_ProbExist "Probability for the existence of an object for the given time and position (in 3sigma-area)";
CM_ SG_ 1005 VID_Obj_12_StdD_dAng_longitude "Standard deviation for VID_Obj_12_dAng_longitude";
CM_ SG_ 1005 VID_Obj_12_dAng_longitude "Lateral velocity of the object (related to the reference point), calculated as change of angle in the frame";
CM_ SG_ 1005 VID_Obj_12_StdD_Ang_Width "Standard deviation for VID_Obj_12_Ang_Width";
CM_ SG_ 1006 VID_Obj_12_C_ChkSum "CRC8 Checksum";
CM_ SG_ 1006 VID_Obj_12_C_MsgCnt "Message counter (rolling counter)";
CM_ SG_ 1006 VID_Obj_12_C_BlockCnt "Control signal to synchronize segmented blocks of object data";
CM_ SG_ 1006 VID_Obj_12_InvTTC "Inverted value of the time-to-collision with the vertical plane of the camera ";
CM_ SG_ 1006 VID_Obj_12_StdD_InvTTC "Standard deviation for VID_Obj_12_InvTTC";
CM_ SG_ 1006 VID_Obj_12_Ang_Overlap_EgoLane_R "Object Line Assignment (angle based indicator for the overlap of a an object with the ego lane from the right corner)";
CM_ SG_ 1006 VID_Obj_12_Ang_Overlap_EgoLane_L "Object Line Assignment (angle based indicator for the overlap of a an object with the ego lane from the left corner)";
CM_ SG_ 1006 VID_Obj_12_Obj_Age "Cycle counter for the existence of the object (object sampled)";
CM_ SG_ 1006 VID_Obj_12_BrakeLight "Brake light recognized on the object";
CM_ SG_ 1007 VID_Obj_12_D_ChkSum "CRC8 Checksum";
CM_ SG_ 1007 VID_Obj_12_D_MsgCnt "Message counter (rolling counter)";
CM_ SG_ 1007 VID_Obj_12_D_BlockCnt "Control signal to synchronize segmented blocks of object data";
CM_ SG_ 1007 VID_Obj_12_Ang_Edge_L "Angle of the left edge of the object
Conversion factor 2^-11";
CM_ SG_ 1007 VID_Obj_12_Ang_Edge_R "Angle of the right edge of the object
Conversion factor 2^-11";
CM_ SG_ 1007 VID_Obj_12_StdD_Ang_Edge_L "Standard deviation for the Angle of the left edge of the object";
CM_ SG_ 1007 VID_Obj_12_Obj_ID "ID of the object";
CM_ SG_ 915 VID_Obj_12_E_ChkSum "CRC8 Checksum";
CM_ SG_ 915 VID_Obj_12_E_MsgCnt "Message counter (rolling counter)";
CM_ SG_ 915 VID_Obj_12_E_BlockCnt "Control signal to synchronize segmented blocks of object data";
CM_ SG_ 915 VID_Obj_12_Velocity_longitudinal "Longitudinal velocity of the detected object (Vehicle coordinate system)";
CM_ SG_ 915 VID_Obj_12_StdD_Velocity_longitu "Standard deviation of the Longitudinal velocity of the detected object (Vehicle coordinate system)";
CM_ SG_ 915 VID_Obj_12_StdD_Ang_Edge_R "Standard deviation for the Angle of the right edge of the object";
CM_ SG_ 915 VID_Obj_12_ScaleChange "In order to fuse a video object with a radar object at higher distance (>60m), a higher resolution for the  relative velocity is needed in that range. This signal indicates the required change of the scale.";
CM_ SG_ 1008 VID_Obj_13_A_ChkSum "CRC8 Checksum";
CM_ SG_ 1008 VID_Obj_13_A_MsgCnt "Message counter (rolling counter)";
CM_ SG_ 1008 VID_Obj_13_A_BlockCnt "Control signal to synchronize segmented blocks of object data";
CM_ SG_ 1008 VID_Obj_13_Dist_longitude "Longitudinal distance relative to vehicle coordinate system";
CM_ SG_ 1008 VID_Obj_13_StdD_Dist_longitude "Standard deviation for VID_Obj_13_Dist_longitude";
CM_ SG_ 1008 VID_Obj_13_Ang_Center "Center of the recorded side of the 3D-object box (positive angle left of x-axis).
(Mono-Video: Rear view for vehicles). In combination with Obj_Angle_low the center
base point of the objectis described.
Coordinate system: transformed";
CM_ SG_ 1008 VID_Obj_13_Stat_Measure "Object measured tracked

0 Object not measured but predicted based on 3D-model
1 Object was measured in current sample cycle
2 Object not measured but re-matched based on feature tracking";
CM_ SG_ 1008 VID_Obj_13_StdD_Ang_Center "Standard deviation for VID_Obj_13_Ang_Center";
CM_ SG_ 1008 VID_Obj_13_Class "Object class";
CM_ SG_ 1008 VID_Obj_13_RefPoint "Index of the reference point for the 3D-object box
Info: The wording front/rear right/left relates to the indicated object orientation.
If this data is not available then a orienntation can be chosen.";
CM_ SG_ 1009 VID_Obj_13_B_ChkSum "CRC8 Checksum";
CM_ SG_ 1009 VID_Obj_13_B_MsgCnt "Message counter (rolling counter)";
CM_ SG_ 1009 VID_Obj_13_B_BlockCnt "Control signal to synchronize segmented blocks of object data";
CM_ SG_ 1009 VID_Obj_13_Ang_Width "Width of the recorded side of the 3D-object box (positive angle left of x-axis)
Monovideo: Rear view for vehicles
Coordinate system: Transformed coordinate system with camera being origin
! Ego-movement has to be compensated !";
CM_ SG_ 1009 VID_Obj_13_ProbExist "Probability for the existence of an object for the given time and position (in 3sigma-area)";
CM_ SG_ 1009 VID_Obj_13_StdD_dAng_longitude "Standard deviation for VID_Obj_13_dAng_longitude";
CM_ SG_ 1009 VID_Obj_13_dAng_longitude "Lateral velocity of the object (related to the reference point), calculated as change of angle in the frame";
CM_ SG_ 1009 VID_Obj_13_StdD_Ang_Width "Standard deviation for VID_Obj_13_Ang_Width";
CM_ SG_ 1010 VID_Obj_13_C_ChkSum "CRC8 Checksum";
CM_ SG_ 1010 VID_Obj_13_C_MsgCnt "Message counter (rolling counter)";
CM_ SG_ 1010 VID_Obj_13_C_BlockCnt "Control signal to synchronize segmented blocks of object data";
CM_ SG_ 1010 VID_Obj_13_InvTTC "Inverted value of the time-to-collision with the vertical plane of the camera ";
CM_ SG_ 1010 VID_Obj_13_StdD_InvTTC "Standard deviation for VID_Obj_13_InvTTC";
CM_ SG_ 1010 VID_Obj_13_Ang_Overlap_EgoLane_R "Object Line Assignment (angle based indicator for the overlap of a an object with the ego lane from the right corner)";
CM_ SG_ 1010 VID_Obj_13_Ang_Overlap_EgoLane_L "Object Line Assignment (angle based indicator for the overlap of a an object with the ego lane from the left corner)";
CM_ SG_ 1010 VID_Obj_13_Obj_Age "Cycle counter for the existence of the object (object sampled)";
CM_ SG_ 1010 VID_Obj_13_BrakeLight "Brake light recognized on the object";
CM_ SG_ 1011 VID_Obj_13_D_ChkSum "CRC8 Checksum";
CM_ SG_ 1011 VID_Obj_13_D_MsgCnt "Message counter (rolling counter)";
CM_ SG_ 1011 VID_Obj_13_D_BlockCnt "Control signal to synchronize segmented blocks of object data";
CM_ SG_ 1011 VID_Obj_13_Ang_Edge_L "Angle of the left edge of the object
Conversion factor 2^-11";
CM_ SG_ 1011 VID_Obj_13_Ang_Edge_R "Angle of the right edge of the object
Conversion factor 2^-11";
CM_ SG_ 1011 VID_Obj_13_StdD_Ang_Edge_L "Standard deviation for the Angle of the left edge of the object";
CM_ SG_ 1011 VID_Obj_13_Obj_ID "ID of the object";
CM_ SG_ 916 VID_Obj_13_E_ChkSum "CRC8 Checksum";
CM_ SG_ 916 VID_Obj_13_E_MsgCnt "Message counter (rolling counter)";
CM_ SG_ 916 VID_Obj_13_E_BlockCnt "Control signal to synchronize segmented blocks of object data";
CM_ SG_ 916 VID_Obj_13_Velocity_longitudinal "Longitudinal velocity of the detected object (Vehicle coordinate system)";
CM_ SG_ 916 VID_Obj_13_StdD_Velocity_longitu "Standard deviation of the Longitudinal velocity of the detected object (Vehicle coordinate system)";
CM_ SG_ 916 VID_Obj_13_StdD_Ang_Edge_R "Standard deviation for the Angle of the right edge of the object";
CM_ SG_ 916 VID_Obj_13_ScaleChange "In order to fuse a video object with a radar object at higher distance (>60m), a higher resolution for the  relative velocity is needed in that range. This signal indicates the required change of the scale.";
CM_ SG_ 1012 VID_Obj_14_A_ChkSum "CRC8 Checksum";
CM_ SG_ 1012 VID_Obj_14_A_MsgCnt "Message counter (rolling counter)";
CM_ SG_ 1012 VID_Obj_14_A_BlockCnt "Control signal to synchronize segmented blocks of object data";
CM_ SG_ 1012 VID_Obj_14_Dist_longitude "Longitudinal distance relative to vehicle coordinate system";
CM_ SG_ 1012 VID_Obj_14_StdD_Dist_longitude "Standard deviation for VID_Obj_14_Dist_longitude";
CM_ SG_ 1012 VID_Obj_14_Ang_Center "Center of the recorded side of the 3D-object box (positive angle left of x-axis).
(Mono-Video: Rear view for vehicles). In combination with Obj_Angle_low the center
base point of the objectis described.
Coordinate system: transformed";
CM_ SG_ 1012 VID_Obj_14_Stat_Measure "Object measured tracked

0 Object not measured but predicted based on 3D-model
1 Object was measured in current sample cycle
2 Object not measured but re-matched based on feature tracking";
CM_ SG_ 1012 VID_Obj_14_StdD_Ang_Center "Standard deviation for VID_Obj_14_Ang_Center";
CM_ SG_ 1012 VID_Obj_14_Class "Object class";
CM_ SG_ 1012 VID_Obj_14_RefPoint "Index of the reference point for the 3D-object box
Info: The wording front/rear right/left relates to the indicated object orientation.
If this data is not available then a orienntation can be chosen.";
CM_ SG_ 1013 VID_Obj_14_B_ChkSum "CRC8 Checksum";
CM_ SG_ 1013 VID_Obj_14_B_MsgCnt "Message counter (rolling counter)";
CM_ SG_ 1013 VID_Obj_14_B_BlockCnt "Control signal to synchronize segmented blocks of object data";
CM_ SG_ 1013 VID_Obj_14_Ang_Width "Width of the recorded side of the 3D-object box (positive angle left of x-axis)
Monovideo: Rear view for vehicles
Coordinate system: Transformed coordinate system with camera being origin
! Ego-movement has to be compensated !";
CM_ SG_ 1013 VID_Obj_14_ProbExist "Probability for the existence of an object for the given time and position (in 3sigma-area)";
CM_ SG_ 1013 VID_Obj_14_StdD_dAng_longitude "Standard deviation for VID_Obj_14_dAng_longitude";
CM_ SG_ 1013 VID_Obj_14_dAng_longitude "Lateral velocity of the object (related to the reference point), calculated as change of angle in the frame";
CM_ SG_ 1013 VID_Obj_14_StdD_Ang_Width "Standard deviation for VID_Obj_14_Ang_Width";
CM_ SG_ 1014 VID_Obj_14_C_ChkSum "CRC8 Checksum";
CM_ SG_ 1014 VID_Obj_14_C_MsgCnt "Message counter (rolling counter)";
CM_ SG_ 1014 VID_Obj_14_C_BlockCnt "Control signal to synchronize segmented blocks of object data";
CM_ SG_ 1014 VID_Obj_14_InvTTC "Inverted value of the time-to-collision with the vertical plane of the camera ";
CM_ SG_ 1014 VID_Obj_14_StdD_InvTTC "Standard deviation for VID_Obj_14_InvTTC";
CM_ SG_ 1014 VID_Obj_14_Ang_Overlap_EgoLane_R "Object Line Assignment (angle based indicator for the overlap of a an object with the ego lane from the right corner)";
CM_ SG_ 1014 VID_Obj_14_Ang_Overlap_EgoLane_L "Object Line Assignment (angle based indicator for the overlap of a an object with the ego lane from the left corner)";
CM_ SG_ 1014 VID_Obj_14_Obj_Age "Cycle counter for the existence of the object (object sampled)";
CM_ SG_ 1014 VID_Obj_14_BrakeLight "Brake light recognized on the object";
CM_ SG_ 1015 VID_Obj_14_D_ChkSum "CRC8 Checksum";
CM_ SG_ 1015 VID_Obj_14_D_MsgCnt "Message counter (rolling counter)";
CM_ SG_ 1015 VID_Obj_14_D_BlockCnt "Control signal to synchronize segmented blocks of object data";
CM_ SG_ 1015 VID_Obj_14_Ang_Edge_L "Angle of the left edge of the object
Conversion factor 2^-11";
CM_ SG_ 1015 VID_Obj_14_Ang_Edge_R "Angle of the right edge of the object
Conversion factor 2^-11";
CM_ SG_ 1015 VID_Obj_14_StdD_Ang_Edge_L "Standard deviation for the Angle of the left edge of the object";
CM_ SG_ 1015 VID_Obj_14_Obj_ID "ID of the object";
CM_ SG_ 917 VID_Obj_14_E_ChkSum "CRC8 Checksum";
CM_ SG_ 917 VID_Obj_14_E_MsgCnt "Message counter (rolling counter)";
CM_ SG_ 917 VID_Obj_14_E_BlockCnt "Control signal to synchronize segmented blocks of object data";
CM_ SG_ 917 VID_Obj_14_Velocity_longitudinal "Longitudinal velocity of the detected object (Vehicle coordinate system)";
CM_ SG_ 917 VID_Obj_14_StdD_Velocity_longitu "Standard deviation of the Longitudinal velocity of the detected object (Vehicle coordinate system)";
CM_ SG_ 917 VID_Obj_14_StdD_Ang_Edge_R "Standard deviation for the Angle of the right edge of the object";
CM_ SG_ 917 VID_Obj_14_ScaleChange "In order to fuse a video object with a radar object at higher distance (>60m), a higher resolution for the  relative velocity is needed in that range. This signal indicates the required change of the scale.";
CM_ SG_ 1016 VID_Obj_15_A_ChkSum "CRC8 Checksum";
CM_ SG_ 1016 VID_Obj_15_A_MsgCnt "Message counter (rolling counter)";
CM_ SG_ 1016 VID_Obj_15_A_BlockCnt "Control signal to synchronize segmented blocks of object data";
CM_ SG_ 1016 VID_Obj_15_Dist_longitude "Longitudinal distance relative to vehicle coordinate system";
CM_ SG_ 1016 VID_Obj_15_StdD_Dist_longitude "Standard deviation for VID_Obj_15_Dist_longitude";
CM_ SG_ 1016 VID_Obj_15_Ang_Center "Center of the recorded side of the 3D-object box (positive angle left of x-axis).
(Mono-Video: Rear view for vehicles). In combination with Obj_Angle_low the center
base point of the objectis described.
Coordinate system: transformed";
CM_ SG_ 1016 VID_Obj_15_Stat_Measure "Object measured tracked

0 Object not measured but predicted based on 3D-model
1 Object was measured in current sample cycle
2 Object not measured but re-matched based on feature tracking";
CM_ SG_ 1016 VID_Obj_15_StdD_Ang_Center "Standard deviation for VID_Obj_15_Ang_Center";
CM_ SG_ 1016 VID_Obj_15_Class "Object class";
CM_ SG_ 1016 VID_Obj_15_RefPoint "Index of the reference point for the 3D-object box
Info: The wording front/rear right/left relates to the indicated object orientation.
If this data is not available then a orienntation can be chosen.";
CM_ SG_ 1017 VID_Obj_15_B_ChkSum "CRC8 Checksum";
CM_ SG_ 1017 VID_Obj_15_B_MsgCnt "Message counter (rolling counter)";
CM_ SG_ 1017 VID_Obj_15_B_BlockCnt "Control signal to synchronize segmented blocks of object data";
CM_ SG_ 1017 VID_Obj_15_Ang_Width "Width of the recorded side of the 3D-object box (positive angle left of x-axis)
Monovideo: Rear view for vehicles
Coordinate system: Transformed coordinate system with camera being origin
! Ego-movement has to be compensated !";
CM_ SG_ 1017 VID_Obj_15_ProbExist "Probability for the existence of an object for the given time and position (in 3sigma-area)";
CM_ SG_ 1017 VID_Obj_15_StdD_dAng_longitude "Standard deviation for VID_Obj_15_dAng_longitude";
CM_ SG_ 1017 VID_Obj_15_dAng_longitude "Lateral velocity of the object (related to the reference point), calculated as change of angle in the frame";
CM_ SG_ 1017 VID_Obj_15_StdD_Ang_Width "Standard deviation for VID_Obj_15_Ang_Width";
CM_ SG_ 1018 VID_Obj_15_C_ChkSum "CRC8 Checksum";
CM_ SG_ 1018 VID_Obj_15_C_MsgCnt "Message counter (rolling counter)";
CM_ SG_ 1018 VID_Obj_15_C_BlockCnt "Control signal to synchronize segmented blocks of object data";
CM_ SG_ 1018 VID_Obj_15_InvTTC "Inverted value of the time-to-collision with the vertical plane of the camera ";
CM_ SG_ 1018 VID_Obj_15_StdD_InvTTC "Standard deviation for VID_Obj_15_InvTTC";
CM_ SG_ 1018 VID_Obj_15_Ang_Overlap_EgoLane_R "Object Line Assignment (angle based indicator for the overlap of a an object with the ego lane from the right corner)";
CM_ SG_ 1018 VID_Obj_15_Ang_Overlap_EgoLane_L "Object Line Assignment (angle based indicator for the overlap of a an object with the ego lane from the left corner)";
CM_ SG_ 1018 VID_Obj_15_Obj_Age "Cycle counter for the existence of the object (object sampled)";
CM_ SG_ 1018 VID_Obj_15_BrakeLight "Brake light recognized on the object";
CM_ SG_ 1019 VID_Obj_15_D_ChkSum "CRC8 Checksum";
CM_ SG_ 1019 VID_Obj_15_D_MsgCnt "Message counter (rolling counter)";
CM_ SG_ 1019 VID_Obj_15_D_BlockCnt "Control signal to synchronize segmented blocks of object data";
CM_ SG_ 1019 VID_Obj_15_Ang_Edge_L "Angle of the left edge of the object
Conversion factor 2^-11";
CM_ SG_ 1019 VID_Obj_15_Ang_Edge_R "Angle of the right edge of the object
Conversion factor 2^-11";
CM_ SG_ 1019 VID_Obj_15_StdD_Ang_Edge_L "Standard deviation for the Angle of the left edge of the object";
CM_ SG_ 1019 VID_Obj_15_Obj_ID "ID of the object";
CM_ SG_ 918 VID_Obj_15_E_ChkSum "CRC8 Checksum";
CM_ SG_ 918 VID_Obj_15_E_MsgCnt "Message counter (rolling counter)";
CM_ SG_ 918 VID_Obj_15_E_BlockCnt "Control signal to synchronize segmented blocks of object data";
CM_ SG_ 918 VID_Obj_15_Velocity_longitudinal "Longitudinal velocity of the detected object (Vehicle coordinate system)";
CM_ SG_ 918 VID_Obj_15_StdD_Velocity_longitu "Standard deviation of the Longitudinal velocity of the detected object (Vehicle coordinate system)";
CM_ SG_ 918 VID_Obj_15_StdD_Ang_Edge_R "Standard deviation for the Angle of the right edge of the object";
CM_ SG_ 918 VID_Obj_15_ScaleChange "In order to fuse a video object with a radar object at higher distance (>60m), a higher resolution for the  relative velocity is needed in that range. This signal indicates the required change of the scale.";
CM_ SG_ 1020 VID_Obj_16_A_ChkSum "CRC8 Checksum";
CM_ SG_ 1020 VID_Obj_16_A_MsgCnt "Message counter (rolling counter)";
CM_ SG_ 1020 VID_Obj_16_A_BlockCnt "Control signal to synchronize segmented blocks of object data";
CM_ SG_ 1020 VID_Obj_16_Dist_longitude "Longitudinal distance relative to vehicle coordinate system";
CM_ SG_ 1020 VID_Obj_16_StdD_Dist_longitude "Standard deviation for VID_Obj_16_Dist_longitude";
CM_ SG_ 1020 VID_Obj_16_Ang_Center "Center of the recorded side of the 3D-object box (positive angle left of x-axis).
(Mono-Video: Rear view for vehicles). In combination with Obj_Angle_low the center
base point of the objectis described.
Coordinate system: transformed";
CM_ SG_ 1020 VID_Obj_16_Stat_Measure "Object measured tracked

0 Object not measured but predicted based on 3D-model
1 Object was measured in current sample cycle
2 Object not measured but re-matched based on feature tracking";
CM_ SG_ 1020 VID_Obj_16_StdD_Ang_Center "Standard deviation for VID_Obj_16_Ang_Center";
CM_ SG_ 1020 VID_Obj_16_Class "Object class";
CM_ SG_ 1020 VID_Obj_16_RefPoint "Index of the reference point for the 3D-object box
Info: The wording front/rear right/left relates to the indicated object orientation.
If this data is not available then a orienntation can be chosen.";
CM_ SG_ 1021 VID_Obj_16_B_ChkSum "CRC8 Checksum";
CM_ SG_ 1021 VID_Obj_16_B_MsgCnt "Message counter (rolling counter)";
CM_ SG_ 1021 VID_Obj_16_B_BlockCnt "Control signal to synchronize segmented blocks of object data";
CM_ SG_ 1021 VID_Obj_16_Ang_Width "Width of the recorded side of the 3D-object box (positive angle left of x-axis)
Monovideo: Rear view for vehicles
Coordinate system: Transformed coordinate system with camera being origin
! Ego-movement has to be compensated !";
CM_ SG_ 1021 VID_Obj_16_ProbExist "Probability for the existence of an object for the given time and position (in 3sigma-area)";
CM_ SG_ 1021 VID_Obj_16_StdD_dAng_longitude "Standard deviation for VID_Obj_16_dAng_longitude";
CM_ SG_ 1021 VID_Obj_16_dAng_longitude "Lateral velocity of the object (related to the reference point), calculated as change of angle in the frame";
CM_ SG_ 1021 VID_Obj_16_StdD_Ang_Width "Standard deviation for VID_Obj_16_Ang_Width";
CM_ SG_ 1022 VID_Obj_16_C_ChkSum "CRC8 Checksum";
CM_ SG_ 1022 VID_Obj_16_C_MsgCnt "Message counter (rolling counter)";
CM_ SG_ 1022 VID_Obj_16_C_BlockCnt "Control signal to synchronize segmented blocks of object data";
CM_ SG_ 1022 VID_Obj_16_InvTTC "Inverted value of the time-to-collision with the vertical plane of the camera ";
CM_ SG_ 1022 VID_Obj_16_StdD_InvTTC "Standard deviation for VID_Obj_16_InvTTC";
CM_ SG_ 1022 VID_Obj_16_Ang_Overlap_EgoLane_R "Object Line Assignment (angle based indicator for the overlap of a an object with the ego lane from the right corner)";
CM_ SG_ 1022 VID_Obj_16_Ang_Overlap_EgoLane_L "Object Line Assignment (angle based indicator for the overlap of a an object with the ego lane from the left corner)";
CM_ SG_ 1022 VID_Obj_16_Obj_Age "Cycle counter for the existence of the object (object sampled)";
CM_ SG_ 1022 VID_Obj_16_BrakeLight "Brake light recognized on the object";
CM_ SG_ 1023 VID_Obj_16_D_ChkSum "CRC8 Checksum";
CM_ SG_ 1023 VID_Obj_16_D_MsgCnt "Message counter (rolling counter)";
CM_ SG_ 1023 VID_Obj_16_D_BlockCnt "Control signal to synchronize segmented blocks of object data";
CM_ SG_ 1023 VID_Obj_16_Ang_Edge_L "Angle of the left edge of the object
Conversion factor 2^-11";
CM_ SG_ 1023 VID_Obj_16_Ang_Edge_R "Angle of the right edge of the object
Conversion factor 2^-11";
CM_ SG_ 1023 VID_Obj_16_StdD_Ang_Edge_L "Standard deviation for the Angle of the left edge of the object";
CM_ SG_ 1023 VID_Obj_16_Obj_ID "ID of the object";
CM_ SG_ 919 VID_Obj_16_E_ChkSum "CRC8 Checksum";
CM_ SG_ 919 VID_Obj_16_E_MsgCnt "Message counter (rolling counter)";
CM_ SG_ 919 VID_Obj_16_E_BlockCnt "Control signal to synchronize segmented blocks of object data";
CM_ SG_ 919 VID_Obj_16_Velocity_longitudinal "Longitudinal velocity of the detected object (Vehicle coordinate system)";
CM_ SG_ 919 VID_Obj_16_StdD_Velocity_longitu "Standard deviation of the Longitudinal velocity of the detected object (Vehicle coordinate system)";
CM_ SG_ 919 VID_Obj_16_StdD_Ang_Edge_R "Standard deviation for the Angle of the right edge of the object";
CM_ SG_ 919 VID_Obj_16_ScaleChange "In order to fuse a video object with a radar object at higher distance (>60m), a higher resolution for the  relative velocity is needed in that range. This signal indicates the required change of the scale.";
CM_ SG_ 848 RDR_Stat_ChkSum "CRC8 Checksum";
CM_ SG_ 848 RDR_Stat_MsgCnt "Message counter (rolling counter)";
CM_ SG_ 848 RDR_Stat_BlockCnt "Control signal to synchronize segmented blocks of object data";
CM_ SG_ 848 RDR_Stat_ObjDataAge "Time differece between middle of measurement and broadcast on the vehicle bus";
CM_ SG_ 848 RDR_Stat_PED_Brake "System status for the PED emergency braking function";
CM_ SG_ 848 RDR_Stat_blindness_det "Blindness detection: Blindness was detected after freesight has been detected earlier";
CM_ SG_ 848 RDR_Stat_Avail "Radar unit has detected a temporary non-availability without a DTC entry";
CM_ SG_ 848 RDR_Stat_Error "Radar unit has detected an error with DTC-entry";
CM_ SG_ 849 RDR_Obj_01_ChkSum "CRC8 Checksum";
CM_ SG_ 849 RDR_Obj_01_MsgCnt "Message counter (rolling counter)";
CM_ SG_ 849 RDR_Obj_01_BlockCnt "Control signal to synchronize segmented blocks of object data";
CM_ SG_ 849 RDR_Obj_01_dx_v "Longitudinal distance (dx) relative to the ego vehicle trajectory and the detected 3D-object block";
CM_ SG_ 849 RDR_Obj_01_dy_v "Lateral distance (dy) relative to the ego vehicle trajectory and the detected 3D-object block";
CM_ SG_ 849 RDR_Obj_01_Obj_Obj_ID "Object/Track ID (internal)";
CM_ SG_ 849 RDR_Obj_01_vx_v "Relative velocity in longitudinal direction (dx) relative to the ego vehicle trajectory and the detected 3D-object block ";
CM_ SG_ 849 RDR_Obj_01_RFF "ID of the video object that has been fused with the current object";
CM_ SG_ 850 RDR_Obj_02_ChkSum "CRC8 Checksum";
CM_ SG_ 850 RDR_Obj_02_MsgCnt "Message counter (rolling counter)";
CM_ SG_ 850 RDR_Obj_02_BlockCnt "Control signal to synchronize segmented blocks of object data";
CM_ SG_ 850 RDR_Obj_02_dx_v "Longitudinal distance (dx) relative to the ego vehicle trajectory and the detected 3D-object block";
CM_ SG_ 850 RDR_Obj_02_dy_v "Lateral distance (dy) relative to the ego vehicle trajectory and the detected 3D-object block";
CM_ SG_ 850 RDR_Obj_02_Obj_Obj_ID "Object/Track ID (internal)";
CM_ SG_ 850 RDR_Obj_02_vx_v "Relative velocity in longitudinal direction (dx) relative to the ego vehicle trajectory and the detected 3D-object block ";
CM_ SG_ 850 RDR_Obj_02_RFF "ID of the video object that has been fused with the current object";
CM_ SG_ 851 RDR_Obj_03_ChkSum "CRC8 Checksum";
CM_ SG_ 851 RDR_Obj_03_MsgCnt "Message counter (rolling counter)";
CM_ SG_ 851 RDR_Obj_03_BlockCnt "Control signal to synchronize segmented blocks of object data";
CM_ SG_ 851 RDR_Obj_03_dx_v "Longitudinal distance (dx) relative to the ego vehicle trajectory and the detected 3D-object block";
CM_ SG_ 851 RDR_Obj_03_dy_v "Lateral distance (dy) relative to the ego vehicle trajectory and the detected 3D-object block";
CM_ SG_ 851 RDR_Obj_03_Obj_Obj_ID "Object/Track ID (internal)";
CM_ SG_ 851 RDR_Obj_03_vx_v "Relative velocity in longitudinal direction (dx) relative to the ego vehicle trajectory and the detected 3D-object block ";
CM_ SG_ 851 RDR_Obj_03_RFF "Information, ob das Radarobjekt in der SDF durch die Kamera bestätigt wurde";
CM_ SG_ 852 RDR_Obj_04_ChkSum "CRC8 Checksum";
CM_ SG_ 852 RDR_Obj_04_MsgCnt "Message counter (rolling counter)";
CM_ SG_ 852 RDR_Obj_04_BlockCnt "Control signal to synchronize segmented blocks of object data";
CM_ SG_ 852 RDR_Obj_04_dx_v "Longitudinal distance (dx) relative to the ego vehicle trajectory and the detected 3D-object block";
CM_ SG_ 852 RDR_Obj_04_dy_v "Lateral distance (dy) relative to the ego vehicle trajectory and the detected 3D-object block";
CM_ SG_ 852 RDR_Obj_04_Obj_Obj_ID "Object/Track ID (internal)";
CM_ SG_ 852 RDR_Obj_04_vx_v "Relative velocity in longitudinal direction (dx) relative to the ego vehicle trajectory and the detected 3D-object block ";
CM_ SG_ 852 RDR_Obj_04_RFF "ID of the video object that has been fused with the current object";
BA_DEF_ BO_  "PF_Msg_ID" HEX 0 4095;
BA_DEF_ BO_  "PF_Msg_Name" STRING ;
BA_DEF_ SG_  "PF_Sig_Name" STRING ;
BA_DEF_ BO_  "DiagRequest" ENUM  "No","Yes";
BA_DEF_ BO_  "DiagResponse" ENUM  "No","Yes";
BA_DEF_ BO_  "DiagState" ENUM  "No","Yes";
BA_DEF_ BO_  "GenMsgCycleTime" INT 0 65535;
BA_DEF_ BO_  "GenMsgDelayTime" INT 0 100000;
BA_DEF_ BO_  "GenMsgILSupport" ENUM  "No","Yes";
BA_DEF_ BO_  "GenMsgPDUConstants" STRING ;
BA_DEF_ BO_  "GenMsgSendType" ENUM  "Cyclic","not_used","not_used","not_used","not_used","not_used","not_used","IfActive","NoMsgSendType";
BA_DEF_ BO_  "GenMsgStartDelayTime" INT 0 100000;
BA_DEF_ BO_  "NmMessage" ENUM  "No","Yes";
BA_DEF_ BO_  "NmhMessage" ENUM  "No","Yes";
BA_DEF_ BO_  "MsgType" ENUM  "Application","NM ","NMH","TP2.0","ISO-TP ","BAP","EID";
BA_DEF_ SG_  "GenSigActiveRepetitions" INT -2147483648 2147483647;
BA_DEF_ SG_  "GenSigSendType" ENUM  "Cyclic","OnWrite","OnWriteWithRepetition","OnChange","OnChangeWithRepetition","IfActive","IfActiveWithRepetition","NoSigSendType","OnChangeAndIfActive","OnChangeAndIfActiveWithRepetition";
BA_DEF_ SG_  "GenSigStartValue" INT -2147483648 2147483647;
BA_DEF_ SG_  "NWMWakeupAllowed" ENUM  "No","Yes";
BA_DEF_ SG_  "GenSigFuncType" ENUM  "NoFunction","MsgCounter","CRC-8","XOR","XOR-2","DatedBit","SW-Kl15","CHK","Constant","Protocol","CRC-8-SAE_J1850";
BA_DEF_ SG_  "GenSigSwitchedByIgnition" ENUM  "No","Yes";
BA_DEF_ SG_  "Fehlerwert" HEX 0 2147483647;
BA_DEF_ SG_  "GenSigMissingSourceValue" HEX 0 2147483647;
BA_DEF_ SG_  "SystemSignalLongSymbol" STRING ;
BA_DEF_REL_ BU_SG_REL_  "GenSigTimeoutTime" INT 0 65535;
BA_DEF_DEF_  "PF_Msg_ID" 0;
BA_DEF_DEF_  "PF_Msg_Name" "";
BA_DEF_DEF_  "PF_Sig_Name" ".";
BA_DEF_DEF_  "DiagRequest" "No";
BA_DEF_DEF_  "DiagResponse" "No";
BA_DEF_DEF_  "DiagState" "No";
BA_DEF_DEF_  "GenMsgCycleTime" 0;
BA_DEF_DEF_  "GenMsgDelayTime" 0;
BA_DEF_DEF_  "GenMsgILSupport" "No";
BA_DEF_DEF_  "GenMsgPDUConstants" "";
BA_DEF_DEF_  "GenMsgSendType" "NoMsgSendType";
BA_DEF_DEF_  "GenMsgStartDelayTime" 0;
BA_DEF_DEF_  "NmMessage" "No";
BA_DEF_DEF_  "NmhMessage" "No";
BA_DEF_DEF_  "MsgType" "Application";
BA_DEF_DEF_  "GenSigActiveRepetitions" 0;
BA_DEF_DEF_  "GenSigSendType" "NoSigSendType";
BA_DEF_DEF_  "GenSigStartValue" 0;
BA_DEF_DEF_  "NWMWakeupAllowed" "No";
BA_DEF_DEF_  "GenSigFuncType" "NoFunction";
BA_DEF_DEF_  "GenSigSwitchedByIgnition" "Yes";
BA_DEF_DEF_  "Fehlerwert" 0;
BA_DEF_DEF_  "GenSigMissingSourceValue" 0;
BA_DEF_DEF_REL_ "GenSigTimeoutTime" 0;
BA_DEF_DEF_  "SystemSignalLongSymbol" "";
BA_ "GenMsgSendType" BO_ 1000 0;
BA_ "GenMsgPDUConstants" BO_ 1000 "0x62,0xa0,0x0a,0x7c,0x55,0x1f,0x49,0xf6,0x15,0x43,0x33,0x2e,0x78,0xc0,0x53,0x74";
BA_ "GenMsgILSupport" BO_ 1000 1;
BA_ "GenMsgDelayTime" BO_ 1000 30;
BA_ "GenMsgCycleTime" BO_ 1000 100;
BA_ "PF_Msg_Name" BO_ 1000 "BV_Obj_11_A";
BA_ "PF_Msg_ID" BO_ 1000 744;
BA_ "GenMsgSendType" BO_ 1001 0;
BA_ "GenMsgPDUConstants" BO_ 1001 "0x62,0xa0,0x0a,0x7c,0x55,0x1f,0x49,0xf6,0x15,0x43,0x33,0x2e,0x78,0xc0,0x53,0x74";
BA_ "GenMsgILSupport" BO_ 1001 1;
BA_ "GenMsgDelayTime" BO_ 1001 30;
BA_ "GenMsgCycleTime" BO_ 1001 100;
BA_ "PF_Msg_Name" BO_ 1001 "BV_Obj_11_B";
BA_ "PF_Msg_ID" BO_ 1001 745;
BA_ "GenMsgSendType" BO_ 1002 0;
BA_ "GenMsgPDUConstants" BO_ 1002 "0x62,0xa0,0x0a,0x7c,0x55,0x1f,0x49,0xf6,0x15,0x43,0x33,0x2e,0x78,0xc0,0x53,0x74";
BA_ "GenMsgILSupport" BO_ 1002 1;
BA_ "GenMsgDelayTime" BO_ 1002 30;
BA_ "GenMsgCycleTime" BO_ 1002 100;
BA_ "PF_Msg_Name" BO_ 1002 "BV_Obj_11_C";
BA_ "PF_Msg_ID" BO_ 1002 746;
BA_ "GenMsgSendType" BO_ 1003 0;
BA_ "GenMsgPDUConstants" BO_ 1003 "0x62,0xa0,0x0a,0x7c,0x55,0x1f,0x49,0xf6,0x15,0x43,0x33,0x2e,0x78,0xc0,0x53,0x74";
BA_ "GenMsgILSupport" BO_ 1003 1;
BA_ "GenMsgDelayTime" BO_ 1003 30;
BA_ "GenMsgCycleTime" BO_ 1003 100;
BA_ "PF_Msg_Name" BO_ 1003 "BV_Obj_11_D";
BA_ "PF_Msg_ID" BO_ 1003 747;
BA_ "GenMsgSendType" BO_ 914 0;
BA_ "GenMsgPDUConstants" BO_ 914 "0x62,0xa0,0x0a,0x7c,0x55,0x1f,0x49,0xf6,0x15,0x43,0x33,0x2e,0x78,0xc0,0x53,0x74";
BA_ "GenMsgILSupport" BO_ 914 1;
BA_ "GenMsgDelayTime" BO_ 914 30;
BA_ "GenMsgCycleTime" BO_ 914 100;
BA_ "PF_Msg_Name" BO_ 914 "BV_Obj_11_E";
BA_ "PF_Msg_ID" BO_ 914 658;
BA_ "GenMsgSendType" BO_ 1004 0;
BA_ "GenMsgPDUConstants" BO_ 1004 "0x62,0xa0,0x0a,0x7c,0x55,0x1f,0x49,0xf6,0x15,0x43,0x33,0x2e,0x78,0xc0,0x53,0x74";
BA_ "GenMsgILSupport" BO_ 1004 1;
BA_ "GenMsgDelayTime" BO_ 1004 30;
BA_ "GenMsgCycleTime" BO_ 1004 100;
BA_ "PF_Msg_Name" BO_ 1004 "BV_Obj_12_A";
BA_ "PF_Msg_ID" BO_ 1004 748;
BA_ "GenMsgSendType" BO_ 1005 0;
BA_ "GenMsgPDUConstants" BO_ 1005 "0x62,0xa0,0x0a,0x7c,0x55,0x1f,0x49,0xf6,0x15,0x43,0x33,0x2e,0x78,0xc0,0x53,0x74";
BA_ "GenMsgILSupport" BO_ 1005 1;
BA_ "GenMsgDelayTime" BO_ 1005 30;
BA_ "GenMsgCycleTime" BO_ 1005 100;
BA_ "PF_Msg_Name" BO_ 1005 "BV_Obj_12_B";
BA_ "PF_Msg_ID" BO_ 1005 749;
BA_ "GenMsgSendType" BO_ 1006 0;
BA_ "GenMsgPDUConstants" BO_ 1006 "0x62,0xa0,0x0a,0x7c,0x55,0x1f,0x49,0xf6,0x15,0x43,0x33,0x2e,0x78,0xc0,0x53,0x74";
BA_ "GenMsgILSupport" BO_ 1006 1;
BA_ "GenMsgDelayTime" BO_ 1006 30;
BA_ "GenMsgCycleTime" BO_ 1006 100;
BA_ "PF_Msg_Name" BO_ 1006 "BV_Obj_12_C";
BA_ "PF_Msg_ID" BO_ 1006 750;
BA_ "GenMsgSendType" BO_ 1007 0;
BA_ "GenMsgPDUConstants" BO_ 1007 "0x62,0xa0,0x0a,0x7c,0x55,0x1f,0x49,0xf6,0x15,0x43,0x33,0x2e,0x78,0xc0,0x53,0x74";
BA_ "GenMsgILSupport" BO_ 1007 1;
BA_ "GenMsgDelayTime" BO_ 1007 30;
BA_ "GenMsgCycleTime" BO_ 1007 100;
BA_ "PF_Msg_Name" BO_ 1007 "BV_Obj_12_D";
BA_ "PF_Msg_ID" BO_ 1007 751;
BA_ "GenMsgSendType" BO_ 915 0;
BA_ "GenMsgPDUConstants" BO_ 915 "0x62,0xa0,0x0a,0x7c,0x55,0x1f,0x49,0xf6,0x15,0x43,0x33,0x2e,0x78,0xc0,0x53,0x74";
BA_ "GenMsgILSupport" BO_ 915 1;
BA_ "GenMsgDelayTime" BO_ 915 30;
BA_ "GenMsgCycleTime" BO_ 915 100;
BA_ "PF_Msg_Name" BO_ 915 "BV_Obj_12_E";
BA_ "PF_Msg_ID" BO_ 915 659;
BA_ "GenMsgSendType" BO_ 1008 0;
BA_ "GenMsgPDUConstants" BO_ 1008 "0x62,0xa0,0x0a,0x7c,0x55,0x1f,0x49,0xf6,0x15,0x43,0x33,0x2e,0x78,0xc0,0x53,0x74";
BA_ "GenMsgILSupport" BO_ 1008 1;
BA_ "GenMsgDelayTime" BO_ 1008 30;
BA_ "GenMsgCycleTime" BO_ 1008 100;
BA_ "PF_Msg_Name" BO_ 1008 "BV_Obj_13_A";
BA_ "PF_Msg_ID" BO_ 1008 752;
BA_ "GenMsgSendType" BO_ 1009 0;
BA_ "GenMsgPDUConstants" BO_ 1009 "0x62,0xa0,0x0a,0x7c,0x55,0x1f,0x49,0xf6,0x15,0x43,0x33,0x2e,0x78,0xc0,0x53,0x74";
BA_ "GenMsgILSupport" BO_ 1009 1;
BA_ "GenMsgDelayTime" BO_ 1009 30;
BA_ "GenMsgCycleTime" BO_ 1009 100;
BA_ "PF_Msg_Name" BO_ 1009 "BV_Obj_13_B";
BA_ "PF_Msg_ID" BO_ 1009 753;
BA_ "GenMsgSendType" BO_ 1010 0;
BA_ "GenMsgPDUConstants" BO_ 1010 "0x62,0xa0,0x0a,0x7c,0x55,0x1f,0x49,0xf6,0x15,0x43,0x33,0x2e,0x78,0xc0,0x53,0x74";
BA_ "GenMsgILSupport" BO_ 1010 1;
BA_ "GenMsgDelayTime" BO_ 1010 30;
BA_ "GenMsgCycleTime" BO_ 1010 100;
BA_ "PF_Msg_Name" BO_ 1010 "BV_Obj_13_C";
BA_ "PF_Msg_ID" BO_ 1010 754;
BA_ "GenMsgSendType" BO_ 1011 0;
BA_ "GenMsgPDUConstants" BO_ 1011 "0x62,0xa0,0x0a,0x7c,0x55,0x1f,0x49,0xf6,0x15,0x43,0x33,0x2e,0x78,0xc0,0x53,0x74";
BA_ "GenMsgILSupport" BO_ 1011 1;
BA_ "GenMsgDelayTime" BO_ 1011 30;
BA_ "GenMsgCycleTime" BO_ 1011 100;
BA_ "PF_Msg_Name" BO_ 1011 "BV_Obj_13_D";
BA_ "PF_Msg_ID" BO_ 1011 755;
BA_ "GenMsgSendType" BO_ 916 0;
BA_ "GenMsgPDUConstants" BO_ 916 "0x62,0xa0,0x0a,0x7c,0x55,0x1f,0x49,0xf6,0x15,0x43,0x33,0x2e,0x78,0xc0,0x53,0x74";
BA_ "GenMsgILSupport" BO_ 916 1;
BA_ "GenMsgDelayTime" BO_ 916 30;
BA_ "GenMsgCycleTime" BO_ 916 100;
BA_ "PF_Msg_Name" BO_ 916 "BV_Obj_13_E";
BA_ "PF_Msg_ID" BO_ 916 660;
BA_ "GenMsgSendType" BO_ 1012 0;
BA_ "GenMsgPDUConstants" BO_ 1012 "0x62,0xa0,0x0a,0x7c,0x55,0x1f,0x49,0xf6,0x15,0x43,0x33,0x2e,0x78,0xc0,0x53,0x74";
BA_ "GenMsgILSupport" BO_ 1012 1;
BA_ "GenMsgDelayTime" BO_ 1012 30;
BA_ "GenMsgCycleTime" BO_ 1012 100;
BA_ "PF_Msg_Name" BO_ 1012 "BV_Obj_14_A";
BA_ "PF_Msg_ID" BO_ 1012 756;
BA_ "GenMsgSendType" BO_ 1013 0;
BA_ "GenMsgPDUConstants" BO_ 1013 "0x62,0xa0,0x0a,0x7c,0x55,0x1f,0x49,0xf6,0x15,0x43,0x33,0x2e,0x78,0xc0,0x53,0x74";
BA_ "GenMsgILSupport" BO_ 1013 1;
BA_ "GenMsgDelayTime" BO_ 1013 30;
BA_ "GenMsgCycleTime" BO_ 1013 100;
BA_ "PF_Msg_Name" BO_ 1013 "BV_Obj_14_B";
BA_ "PF_Msg_ID" BO_ 1013 757;
BA_ "GenMsgSendType" BO_ 1014 0;
BA_ "GenMsgPDUConstants" BO_ 1014 "0x62,0xa0,0x0a,0x7c,0x55,0x1f,0x49,0xf6,0x15,0x43,0x33,0x2e,0x78,0xc0,0x53,0x74";
BA_ "GenMsgILSupport" BO_ 1014 1;
BA_ "GenMsgDelayTime" BO_ 1014 30;
BA_ "GenMsgCycleTime" BO_ 1014 100;
BA_ "PF_Msg_Name" BO_ 1014 "BV_Obj_14_C";
BA_ "PF_Msg_ID" BO_ 1014 758;
BA_ "GenMsgSendType" BO_ 1015 0;
BA_ "GenMsgPDUConstants" BO_ 1015 "0x62,0xa0,0x0a,0x7c,0x55,0x1f,0x49,0xf6,0x15,0x43,0x33,0x2e,0x78,0xc0,0x53,0x74";
BA_ "GenMsgILSupport" BO_ 1015 1;
BA_ "GenMsgDelayTime" BO_ 1015 30;
BA_ "GenMsgCycleTime" BO_ 1015 100;
BA_ "PF_Msg_Name" BO_ 1015 "BV_Obj_14_D";
BA_ "PF_Msg_ID" BO_ 1015 759;
BA_ "GenMsgSendType" BO_ 917 0;
BA_ "GenMsgPDUConstants" BO_ 917 "0x62,0xa0,0x0a,0x7c,0x55,0x1f,0x49,0xf6,0x15,0x43,0x33,0x2e,0x78,0xc0,0x53,0x74";
BA_ "GenMsgILSupport" BO_ 917 1;
BA_ "GenMsgDelayTime" BO_ 917 30;
BA_ "GenMsgCycleTime" BO_ 917 100;
BA_ "PF_Msg_Name" BO_ 917 "BV_Obj_14_E";
BA_ "PF_Msg_ID" BO_ 917 661;
BA_ "GenMsgSendType" BO_ 1016 0;
BA_ "GenMsgPDUConstants" BO_ 1016 "0x62,0xa0,0x0a,0x7c,0x55,0x1f,0x49,0xf6,0x15,0x43,0x33,0x2e,0x78,0xc0,0x53,0x74";
BA_ "GenMsgILSupport" BO_ 1016 1;
BA_ "GenMsgDelayTime" BO_ 1016 30;
BA_ "GenMsgCycleTime" BO_ 1016 100;
BA_ "PF_Msg_Name" BO_ 1016 "BV_Obj_15_A";
BA_ "PF_Msg_ID" BO_ 1016 760;
BA_ "GenMsgSendType" BO_ 1017 0;
BA_ "GenMsgPDUConstants" BO_ 1017 "0x62,0xa0,0x0a,0x7c,0x55,0x1f,0x49,0xf6,0x15,0x43,0x33,0x2e,0x78,0xc0,0x53,0x74";
BA_ "GenMsgILSupport" BO_ 1017 1;
BA_ "GenMsgDelayTime" BO_ 1017 30;
BA_ "GenMsgCycleTime" BO_ 1017 100;
BA_ "PF_Msg_Name" BO_ 1017 "BV_Obj_15_B";
BA_ "PF_Msg_ID" BO_ 1017 761;
BA_ "GenMsgSendType" BO_ 1018 0;
BA_ "GenMsgPDUConstants" BO_ 1018 "0x62,0xa0,0x0a,0x7c,0x55,0x1f,0x49,0xf6,0x15,0x43,0x33,0x2e,0x78,0xc0,0x53,0x74";
BA_ "GenMsgILSupport" BO_ 1018 1;
BA_ "GenMsgDelayTime" BO_ 1018 30;
BA_ "GenMsgCycleTime" BO_ 1018 100;
BA_ "PF_Msg_Name" BO_ 1018 "BV_Obj_15_C";
BA_ "PF_Msg_ID" BO_ 1018 762;
BA_ "GenMsgSendType" BO_ 1019 0;
BA_ "GenMsgPDUConstants" BO_ 1019 "0x62,0xa0,0x0a,0x7c,0x55,0x1f,0x49,0xf6,0x15,0x43,0x33,0x2e,0x78,0xc0,0x53,0x74";
BA_ "GenMsgILSupport" BO_ 1019 1;
BA_ "GenMsgDelayTime" BO_ 1019 30;
BA_ "GenMsgCycleTime" BO_ 1019 100;
BA_ "PF_Msg_Name" BO_ 1019 "BV_Obj_15_D";
BA_ "PF_Msg_ID" BO_ 1019 763;
BA_ "GenMsgSendType" BO_ 918 0;
BA_ "GenMsgPDUConstants" BO_ 918 "0x62,0xa0,0x0a,0x7c,0x55,0x1f,0x49,0xf6,0x15,0x43,0x33,0x2e,0x78,0xc0,0x53,0x74";
BA_ "GenMsgILSupport" BO_ 918 1;
BA_ "GenMsgDelayTime" BO_ 918 30;
BA_ "GenMsgCycleTime" BO_ 918 100;
BA_ "PF_Msg_Name" BO_ 918 "BV_Obj_15_E";
BA_ "PF_Msg_ID" BO_ 918 662;
BA_ "GenMsgSendType" BO_ 1020 0;
BA_ "GenMsgPDUConstants" BO_ 1020 "0x62,0xa0,0x0a,0x7c,0x55,0x1f,0x49,0xf6,0x15,0x43,0x33,0x2e,0x78,0xc0,0x53,0x74";
BA_ "GenMsgILSupport" BO_ 1020 1;
BA_ "GenMsgDelayTime" BO_ 1020 30;
BA_ "GenMsgCycleTime" BO_ 1020 100;
BA_ "PF_Msg_Name" BO_ 1020 "BV_Obj_16_A";
BA_ "PF_Msg_ID" BO_ 1020 764;
BA_ "GenMsgSendType" BO_ 1021 0;
BA_ "GenMsgPDUConstants" BO_ 1021 "0x62,0xa0,0x0a,0x7c,0x55,0x1f,0x49,0xf6,0x15,0x43,0x33,0x2e,0x78,0xc0,0x53,0x74";
BA_ "GenMsgILSupport" BO_ 1021 1;
BA_ "GenMsgDelayTime" BO_ 1021 30;
BA_ "GenMsgCycleTime" BO_ 1021 100;
BA_ "PF_Msg_Name" BO_ 1021 "BV_Obj_16_B";
BA_ "PF_Msg_ID" BO_ 1021 765;
BA_ "GenMsgSendType" BO_ 1022 0;
BA_ "GenMsgPDUConstants" BO_ 1022 "0x62,0xa0,0x0a,0x7c,0x55,0x1f,0x49,0xf6,0x15,0x43,0x33,0x2e,0x78,0xc0,0x53,0x74";
BA_ "GenMsgILSupport" BO_ 1022 1;
BA_ "GenMsgDelayTime" BO_ 1022 30;
BA_ "GenMsgCycleTime" BO_ 1022 100;
BA_ "PF_Msg_Name" BO_ 1022 "BV_Obj_16_C";
BA_ "PF_Msg_ID" BO_ 1022 766;
BA_ "GenMsgSendType" BO_ 1023 0;
BA_ "GenMsgPDUConstants" BO_ 1023 "0x62,0xa0,0x0a,0x7c,0x55,0x1f,0x49,0xf6,0x15,0x43,0x33,0x2e,0x78,0xc0,0x53,0x74";
BA_ "GenMsgILSupport" BO_ 1023 1;
BA_ "GenMsgDelayTime" BO_ 1023 30;
BA_ "GenMsgCycleTime" BO_ 1023 100;
BA_ "PF_Msg_Name" BO_ 1023 "BV_Obj_16_D";
BA_ "PF_Msg_ID" BO_ 1023 767;
BA_ "GenMsgSendType" BO_ 919 0;
BA_ "GenMsgPDUConstants" BO_ 919 "0x62,0xa0,0x0a,0x7c,0x55,0x1f,0x49,0xf6,0x15,0x43,0x33,0x2e,0x78,0xc0,0x53,0x74";
BA_ "GenMsgILSupport" BO_ 919 1;
BA_ "GenMsgDelayTime" BO_ 919 30;
BA_ "GenMsgCycleTime" BO_ 919 100;
BA_ "PF_Msg_Name" BO_ 919 "BV_Obj_16_E";
BA_ "PF_Msg_ID" BO_ 919 663;
BA_ "GenMsgSendType" BO_ 848 0;
BA_ "GenMsgPDUConstants" BO_ 848 "0x1c,0x97,0xf6,0x6f,0x6b,0x92,0xe2,0x70,0x4b,0x5f,0x1e,0x62,0x6e,0x84,0xa2,0x9d";
BA_ "GenMsgILSupport" BO_ 848 1;
BA_ "GenMsgCycleTime" BO_ 848 40;
BA_ "PF_Msg_Name" BO_ 848 "RDR1_Header";
BA_ "PF_Msg_ID" BO_ 848 592;
BA_ "GenMsgSendType" BO_ 849 7;
BA_ "GenMsgPDUConstants" BO_ 849 "0x53,0x8c,0x87,0x9c,0x09,0xb7,0x38,0x80,0xe5,0xd8,0xbd,0x98,0x3b,0x32,0x54,0x5c";
BA_ "GenMsgILSupport" BO_ 849 1;
BA_ "PF_Msg_Name" BO_ 849 "RDR1_Obj_01";
BA_ "PF_Msg_ID" BO_ 849 593;
BA_ "GenMsgSendType" BO_ 850 7;
BA_ "GenMsgPDUConstants" BO_ 850 "0x56,0x6d,0xaa,0x1c,0xe9,0x8e,0xa0,0x97,0x50,0x65,0xd8,0xf6,0x3d,0x36,0xae,0x6f";
BA_ "GenMsgILSupport" BO_ 850 1;
BA_ "PF_Msg_Name" BO_ 850 "RDR1_Obj_02";
BA_ "PF_Msg_ID" BO_ 850 594;
BA_ "GenMsgSendType" BO_ 851 7;
BA_ "GenMsgPDUConstants" BO_ 851 "0x87,0xb7,0xe5,0x98,0x54,0xdd,0x24,0xb9,0x9b,0xd9,0x90,0x33,0xe1,0x3a,0x1a,0xdf";
BA_ "GenMsgILSupport" BO_ 851 1;
BA_ "PF_Msg_Name" BO_ 851 "RDR1_Obj_03";
BA_ "PF_Msg_ID" BO_ 851 595;
BA_ "GenMsgSendType" BO_ 852 7;
BA_ "GenMsgPDUConstants" BO_ 852 "0x2e,0x88,0x10,0xe3,0x0f,0xde,0x9f,0xe8,0xdc,0xcc,0x8b,0xc4,0x70,0x09,0xb1,0x7f";
BA_ "GenMsgILSupport" BO_ 852 1;
BA_ "PF_Msg_Name" BO_ 852 "RDR1_Obj_04";
BA_ "PF_Msg_ID" BO_ 852 596;
BA_ "GenSigFuncType" SG_ 1000 VID_Obj_11_A_ChkSum 2;
BA_ "GenSigSendType" SG_ 1000 VID_Obj_11_A_ChkSum 0;
BA_ "PF_Sig_Name" SG_ 1000 VID_Obj_11_A_ChkSum "BV_Obj_11_A_CRC";
BA_ "GenSigFuncType" SG_ 1000 VID_Obj_11_A_MsgCnt 1;
BA_ "GenSigSendType" SG_ 1000 VID_Obj_11_A_MsgCnt 0;
BA_ "PF_Sig_Name" SG_ 1000 VID_Obj_11_A_MsgCnt "BV_Obj_11_A_BZ";
BA_ "GenSigSendType" SG_ 1000 VID_Obj_11_A_BlockCnt 3;
BA_ "PF_Sig_Name" SG_ 1000 VID_Obj_11_A_BlockCnt "BV1_Obj_11_A_BlockZaehler";
BA_ "GenSigStartValue" SG_ 1000 VID_Obj_11_Dist_longitude 4095;
BA_ "GenSigSendType" SG_ 1000 VID_Obj_11_Dist_longitude 0;
BA_ "PF_Sig_Name" SG_ 1000 VID_Obj_11_Dist_longitude "BV1_Obj_11_Dist_longitude";
BA_ "GenSigStartValue" SG_ 1000 VID_Obj_11_StdD_Dist_longitude 127;
BA_ "GenSigSendType" SG_ 1000 VID_Obj_11_StdD_Dist_longitude 0;
BA_ "PF_Sig_Name" SG_ 1000 VID_Obj_11_StdD_Dist_longitude "BV1_Obj_11_Dist_longitudeStdA";
BA_ "GenSigStartValue" SG_ 1000 VID_Obj_11_Ang_Center 2047;
BA_ "GenSigSendType" SG_ 1000 VID_Obj_11_Ang_Center 0;
BA_ "PF_Sig_Name" SG_ 1000 VID_Obj_11_Ang_Center "BV1_Obj_11_WnklMitte";
BA_ "GenSigSendType" SG_ 1000 VID_Obj_11_Stat_Measure 0;
BA_ "PF_Sig_Name" SG_ 1000 VID_Obj_11_Stat_Measure "BV1_Obj_11_Gemessen";
BA_ "GenSigStartValue" SG_ 1000 VID_Obj_11_StdD_Ang_Center 255;
BA_ "GenSigSendType" SG_ 1000 VID_Obj_11_StdD_Ang_Center 0;
BA_ "PF_Sig_Name" SG_ 1000 VID_Obj_11_StdD_Ang_Center "BV1_Obj_11_WnklMitteStdA";
BA_ "GenSigStartValue" SG_ 1000 VID_Obj_11_Class 15;
BA_ "GenSigSendType" SG_ 1000 VID_Obj_11_Class 0;
BA_ "PF_Sig_Name" SG_ 1000 VID_Obj_11_Class "BV1_Obj_11_Klasse";
BA_ "GenSigStartValue" SG_ 1000 VID_Obj_11_RefPoint 15;
BA_ "GenSigSendType" SG_ 1000 VID_Obj_11_RefPoint 0;
BA_ "PF_Sig_Name" SG_ 1000 VID_Obj_11_RefPoint "BV1_Obj_11_Bezugspunkt";
BA_ "GenSigFuncType" SG_ 1001 VID_Obj_11_B_ChkSum 2;
BA_ "GenSigSendType" SG_ 1001 VID_Obj_11_B_ChkSum 0;
BA_ "PF_Sig_Name" SG_ 1001 VID_Obj_11_B_ChkSum "BV_Obj_11_B_CRC";
BA_ "GenSigFuncType" SG_ 1001 VID_Obj_11_B_MsgCnt 1;
BA_ "GenSigSendType" SG_ 1001 VID_Obj_11_B_MsgCnt 0;
BA_ "PF_Sig_Name" SG_ 1001 VID_Obj_11_B_MsgCnt "BV_Obj_11_B_BZ";
BA_ "GenSigSendType" SG_ 1001 VID_Obj_11_B_BlockCnt 3;
BA_ "PF_Sig_Name" SG_ 1001 VID_Obj_11_B_BlockCnt "BV1_Obj_11_B_BlockZaehler";
BA_ "GenSigStartValue" SG_ 1001 VID_Obj_11_Ang_Width 2047;
BA_ "GenSigSendType" SG_ 1001 VID_Obj_11_Ang_Width 0;
BA_ "PF_Sig_Name" SG_ 1001 VID_Obj_11_Ang_Width "BV1_Obj_11_WnklBreite";
BA_ "GenSigStartValue" SG_ 1001 VID_Obj_11_ProbExist 127;
BA_ "GenSigSendType" SG_ 1001 VID_Obj_11_ProbExist 0;
BA_ "PF_Sig_Name" SG_ 1001 VID_Obj_11_ProbExist "BV1_Obj_11_ExistenzMass";
BA_ "GenSigStartValue" SG_ 1001 VID_Obj_11_StdD_dAng_longitude 63;
BA_ "GenSigSendType" SG_ 1001 VID_Obj_11_StdD_dAng_longitude 0;
BA_ "PF_Sig_Name" SG_ 1001 VID_Obj_11_StdD_dAng_longitude "BV1_Obj_11_WnklGeschwStdA";
BA_ "GenSigStartValue" SG_ 1001 VID_Obj_11_dAng_longitude 511;
BA_ "GenSigSendType" SG_ 1001 VID_Obj_11_dAng_longitude 0;
BA_ "PF_Sig_Name" SG_ 1001 VID_Obj_11_dAng_longitude "BV1_Obj_11_WnklGeschw";
BA_ "GenSigStartValue" SG_ 1001 VID_Obj_11_StdD_Ang_Width 255;
BA_ "GenSigSendType" SG_ 1001 VID_Obj_11_StdD_Ang_Width 0;
BA_ "PF_Sig_Name" SG_ 1001 VID_Obj_11_StdD_Ang_Width "BV1_Obj_11_WnklBreiteStdA";
BA_ "GenSigFuncType" SG_ 1002 VID_Obj_11_C_ChkSum 2;
BA_ "GenSigSendType" SG_ 1002 VID_Obj_11_C_ChkSum 0;
BA_ "PF_Sig_Name" SG_ 1002 VID_Obj_11_C_ChkSum "BV_Obj_11_C_CRC";
BA_ "GenSigFuncType" SG_ 1002 VID_Obj_11_C_MsgCnt 1;
BA_ "GenSigSendType" SG_ 1002 VID_Obj_11_C_MsgCnt 0;
BA_ "PF_Sig_Name" SG_ 1002 VID_Obj_11_C_MsgCnt "BV_Obj_11_C_BZ";
BA_ "GenSigSendType" SG_ 1002 VID_Obj_11_C_BlockCnt 3;
BA_ "PF_Sig_Name" SG_ 1002 VID_Obj_11_C_BlockCnt "BV1_Obj_11_C_BlockZaehler";
BA_ "GenSigStartValue" SG_ 1002 VID_Obj_11_InvTTC 1023;
BA_ "GenSigSendType" SG_ 1002 VID_Obj_11_InvTTC 0;
BA_ "PF_Sig_Name" SG_ 1002 VID_Obj_11_InvTTC "BV1_Obj_11_InvTTCBildeb";
BA_ "GenSigStartValue" SG_ 1002 VID_Obj_11_StdD_InvTTC 127;
BA_ "GenSigSendType" SG_ 1002 VID_Obj_11_StdD_InvTTC 0;
BA_ "PF_Sig_Name" SG_ 1002 VID_Obj_11_StdD_InvTTC "BV1_Obj_11_InvTTCBildebStdA";
BA_ "GenSigStartValue" SG_ 1002 VID_Obj_11_Ang_Overlap_EgoLane_R 511;
BA_ "GenSigSendType" SG_ 1002 VID_Obj_11_Ang_Overlap_EgoLane_R 0;
BA_ "PF_Sig_Name" SG_ 1002 VID_Obj_11_Ang_Overlap_EgoLane_R "BV1_Obj_11_UeberdWnklEgoSpurR";
BA_ "GenSigStartValue" SG_ 1002 VID_Obj_11_Ang_Overlap_EgoLane_L 511;
BA_ "GenSigSendType" SG_ 1002 VID_Obj_11_Ang_Overlap_EgoLane_L 0;
BA_ "PF_Sig_Name" SG_ 1002 VID_Obj_11_Ang_Overlap_EgoLane_L "BV1_Obj_11_UeberdWnklEgoSpurL";
BA_ "GenSigStartValue" SG_ 1002 VID_Obj_11_Obj_Age 4095;
BA_ "GenSigSendType" SG_ 1002 VID_Obj_11_Obj_Age 0;
BA_ "PF_Sig_Name" SG_ 1002 VID_Obj_11_Obj_Age "BV1_Obj_11_Alter";
BA_ "GenSigSendType" SG_ 1002 VID_Obj_11_BrakeLight 0;
BA_ "PF_Sig_Name" SG_ 1002 VID_Obj_11_BrakeLight "BV1_Obj_11_BremsLicht";
BA_ "GenSigFuncType" SG_ 1003 VID_Obj_11_D_ChkSum 2;
BA_ "GenSigSendType" SG_ 1003 VID_Obj_11_D_ChkSum 0;
BA_ "PF_Sig_Name" SG_ 1003 VID_Obj_11_D_ChkSum "BV_Obj_11_D_CRC";
BA_ "GenSigFuncType" SG_ 1003 VID_Obj_11_D_MsgCnt 1;
BA_ "GenSigSendType" SG_ 1003 VID_Obj_11_D_MsgCnt 0;
BA_ "PF_Sig_Name" SG_ 1003 VID_Obj_11_D_MsgCnt "BV_Obj_11_D_BZ";
BA_ "GenSigSendType" SG_ 1003 VID_Obj_11_D_BlockCnt 3;
BA_ "PF_Sig_Name" SG_ 1003 VID_Obj_11_D_BlockCnt "BV1_Obj_11_D_BlockZaehler";
BA_ "GenSigStartValue" SG_ 1003 VID_Obj_11_Ang_Edge_L 1024;
BA_ "GenSigSendType" SG_ 1003 VID_Obj_11_Ang_Edge_L 0;
BA_ "PF_Sig_Name" SG_ 1003 VID_Obj_11_Ang_Edge_L "BV_Objekt_11_phi_left";
BA_ "GenSigStartValue" SG_ 1003 VID_Obj_11_Ang_Edge_R 1024;
BA_ "GenSigSendType" SG_ 1003 VID_Obj_11_Ang_Edge_R 0;
BA_ "PF_Sig_Name" SG_ 1003 VID_Obj_11_Ang_Edge_R "BV_Objekt_11_phi_right";
BA_ "GenSigStartValue" SG_ 1003 VID_Obj_11_StdD_Ang_Edge_L 512;
BA_ "GenSigSendType" SG_ 1003 VID_Obj_11_StdD_Ang_Edge_L 0;
BA_ "PF_Sig_Name" SG_ 1003 VID_Obj_11_StdD_Ang_Edge_L "BV_Objekt_11_sdv_phi_left";
BA_ "GenSigStartValue" SG_ 1003 VID_Obj_11_Obj_ID 255;
BA_ "GenSigSendType" SG_ 1003 VID_Obj_11_Obj_ID 0;
BA_ "PF_Sig_Name" SG_ 1003 VID_Obj_11_Obj_ID "BV1_Obj_11_ID";
BA_ "GenSigFuncType" SG_ 914 VID_Obj_11_E_ChkSum 2;
BA_ "GenSigSendType" SG_ 914 VID_Obj_11_E_ChkSum 0;
BA_ "PF_Sig_Name" SG_ 914 VID_Obj_11_E_ChkSum "BV_Obj_11_E_CRC";
BA_ "GenSigFuncType" SG_ 914 VID_Obj_11_E_MsgCnt 1;
BA_ "GenSigSendType" SG_ 914 VID_Obj_11_E_MsgCnt 0;
BA_ "PF_Sig_Name" SG_ 914 VID_Obj_11_E_MsgCnt "BV_Obj_11_E_BZ";
BA_ "GenSigSendType" SG_ 914 VID_Obj_11_E_BlockCnt 3;
BA_ "PF_Sig_Name" SG_ 914 VID_Obj_11_E_BlockCnt "BV1_Obj_11_E_BlockZaehler";
BA_ "GenSigStartValue" SG_ 914 VID_Obj_11_Velocity_longitudinal 2046;
BA_ "GenSigSendType" SG_ 914 VID_Obj_11_Velocity_longitudinal 0;
BA_ "PF_Sig_Name" SG_ 914 VID_Obj_11_Velocity_longitudinal "BV1_Obj_11_RadialGeschw";
BA_ "GenSigStartValue" SG_ 914 VID_Obj_11_StdD_Velocity_longitu 1022;
BA_ "GenSigSendType" SG_ 914 VID_Obj_11_StdD_Velocity_longitu 0;
BA_ "PF_Sig_Name" SG_ 914 VID_Obj_11_StdD_Velocity_longitu "BV1_Obj_11_RadialGeschw_StdA";
BA_ "SystemSignalLongSymbol" SG_ 914 VID_Obj_11_StdD_Velocity_longitu "VID_Obj_11_StdD_Velocity_longitudinal";
BA_ "GenSigStartValue" SG_ 914 VID_Obj_11_StdD_Ang_Edge_R 512;
BA_ "GenSigSendType" SG_ 914 VID_Obj_11_StdD_Ang_Edge_R 0;
BA_ "PF_Sig_Name" SG_ 914 VID_Obj_11_StdD_Ang_Edge_R "BV_Objekt_11_sdv_phi_right";
BA_ "GenSigSendType" SG_ 914 VID_Obj_11_ScaleChange 0;
BA_ "PF_Sig_Name" SG_ 914 VID_Obj_11_ScaleChange "BV_Obj_11_ScaleChange";
BA_ "GenSigFuncType" SG_ 1004 VID_Obj_12_A_ChkSum 2;
BA_ "GenSigSendType" SG_ 1004 VID_Obj_12_A_ChkSum 0;
BA_ "PF_Sig_Name" SG_ 1004 VID_Obj_12_A_ChkSum "BV_Obj_12_A_CRC";
BA_ "GenSigFuncType" SG_ 1004 VID_Obj_12_A_MsgCnt 1;
BA_ "GenSigSendType" SG_ 1004 VID_Obj_12_A_MsgCnt 0;
BA_ "PF_Sig_Name" SG_ 1004 VID_Obj_12_A_MsgCnt "BV_Obj_12_A_BZ";
BA_ "GenSigSendType" SG_ 1004 VID_Obj_12_A_BlockCnt 3;
BA_ "PF_Sig_Name" SG_ 1004 VID_Obj_12_A_BlockCnt "BV1_Obj_12_A_BlockZaehler";
BA_ "GenSigStartValue" SG_ 1004 VID_Obj_12_Dist_longitude 4095;
BA_ "GenSigSendType" SG_ 1004 VID_Obj_12_Dist_longitude 0;
BA_ "PF_Sig_Name" SG_ 1004 VID_Obj_12_Dist_longitude "BV1_Obj_12_Dist_longitude";
BA_ "GenSigStartValue" SG_ 1004 VID_Obj_12_StdD_Dist_longitude 127;
BA_ "GenSigSendType" SG_ 1004 VID_Obj_12_StdD_Dist_longitude 0;
BA_ "PF_Sig_Name" SG_ 1004 VID_Obj_12_StdD_Dist_longitude "BV1_Obj_12_Dist_longitudeStdA";
BA_ "GenSigStartValue" SG_ 1004 VID_Obj_12_Ang_Center 2047;
BA_ "GenSigSendType" SG_ 1004 VID_Obj_12_Ang_Center 0;
BA_ "PF_Sig_Name" SG_ 1004 VID_Obj_12_Ang_Center "BV1_Obj_12_WnklMitte";
BA_ "GenSigSendType" SG_ 1004 VID_Obj_12_Stat_Measure 0;
BA_ "PF_Sig_Name" SG_ 1004 VID_Obj_12_Stat_Measure "BV1_Obj_12_Gemessen";
BA_ "GenSigStartValue" SG_ 1004 VID_Obj_12_StdD_Ang_Center 255;
BA_ "GenSigSendType" SG_ 1004 VID_Obj_12_StdD_Ang_Center 0;
BA_ "PF_Sig_Name" SG_ 1004 VID_Obj_12_StdD_Ang_Center "BV1_Obj_12_WnklMitteStdA";
BA_ "GenSigStartValue" SG_ 1004 VID_Obj_12_Class 15;
BA_ "GenSigSendType" SG_ 1004 VID_Obj_12_Class 0;
BA_ "PF_Sig_Name" SG_ 1004 VID_Obj_12_Class "BV1_Obj_12_Klasse";
BA_ "GenSigStartValue" SG_ 1004 VID_Obj_12_RefPoint 15;
BA_ "GenSigSendType" SG_ 1004 VID_Obj_12_RefPoint 0;
BA_ "PF_Sig_Name" SG_ 1004 VID_Obj_12_RefPoint "BV1_Obj_12_Bezugspunkt";
BA_ "GenSigFuncType" SG_ 1005 VID_Obj_12_B_ChkSum 2;
BA_ "GenSigSendType" SG_ 1005 VID_Obj_12_B_ChkSum 0;
BA_ "PF_Sig_Name" SG_ 1005 VID_Obj_12_B_ChkSum "BV_Obj_12_B_CRC";
BA_ "GenSigFuncType" SG_ 1005 VID_Obj_12_B_MsgCnt 1;
BA_ "GenSigSendType" SG_ 1005 VID_Obj_12_B_MsgCnt 0;
BA_ "PF_Sig_Name" SG_ 1005 VID_Obj_12_B_MsgCnt "BV_Obj_12_B_BZ";
BA_ "GenSigSendType" SG_ 1005 VID_Obj_12_B_BlockCnt 3;
BA_ "PF_Sig_Name" SG_ 1005 VID_Obj_12_B_BlockCnt "BV1_Obj_12_B_BlockZaehler";
BA_ "GenSigStartValue" SG_ 1005 VID_Obj_12_Ang_Width 2047;
BA_ "GenSigSendType" SG_ 1005 VID_Obj_12_Ang_Width 0;
BA_ "PF_Sig_Name" SG_ 1005 VID_Obj_12_Ang_Width "BV1_Obj_12_WnklBreite";
BA_ "GenSigStartValue" SG_ 1005 VID_Obj_12_ProbExist 127;
BA_ "GenSigSendType" SG_ 1005 VID_Obj_12_ProbExist 0;
BA_ "PF_Sig_Name" SG_ 1005 VID_Obj_12_ProbExist "BV1_Obj_12_ExistenzMass";
BA_ "GenSigStartValue" SG_ 1005 VID_Obj_12_StdD_dAng_longitude 63;
BA_ "GenSigSendType" SG_ 1005 VID_Obj_12_StdD_dAng_longitude 0;
BA_ "PF_Sig_Name" SG_ 1005 VID_Obj_12_StdD_dAng_longitude "BV1_Obj_12_WnklGeschwStdA";
BA_ "GenSigStartValue" SG_ 1005 VID_Obj_12_dAng_longitude 511;
BA_ "GenSigSendType" SG_ 1005 VID_Obj_12_dAng_longitude 0;
BA_ "PF_Sig_Name" SG_ 1005 VID_Obj_12_dAng_longitude "BV1_Obj_12_WnklGeschw";
BA_ "GenSigStartValue" SG_ 1005 VID_Obj_12_StdD_Ang_Width 255;
BA_ "GenSigSendType" SG_ 1005 VID_Obj_12_StdD_Ang_Width 0;
BA_ "PF_Sig_Name" SG_ 1005 VID_Obj_12_StdD_Ang_Width "BV1_Obj_12_WnklBreiteStdA";
BA_ "GenSigFuncType" SG_ 1006 VID_Obj_12_C_ChkSum 2;
BA_ "GenSigSendType" SG_ 1006 VID_Obj_12_C_ChkSum 0;
BA_ "PF_Sig_Name" SG_ 1006 VID_Obj_12_C_ChkSum "BV_Obj_12_C_CRC";
BA_ "GenSigFuncType" SG_ 1006 VID_Obj_12_C_MsgCnt 1;
BA_ "GenSigSendType" SG_ 1006 VID_Obj_12_C_MsgCnt 0;
BA_ "PF_Sig_Name" SG_ 1006 VID_Obj_12_C_MsgCnt "BV_Obj_12_C_BZ";
BA_ "GenSigSendType" SG_ 1006 VID_Obj_12_C_BlockCnt 3;
BA_ "PF_Sig_Name" SG_ 1006 VID_Obj_12_C_BlockCnt "BV1_Obj_12_C_BlockZaehler";
BA_ "GenSigStartValue" SG_ 1006 VID_Obj_12_InvTTC 1023;
BA_ "GenSigSendType" SG_ 1006 VID_Obj_12_InvTTC 0;
BA_ "PF_Sig_Name" SG_ 1006 VID_Obj_12_InvTTC "BV1_Obj_12_InvTTCBildeb";
BA_ "GenSigStartValue" SG_ 1006 VID_Obj_12_StdD_InvTTC 127;
BA_ "GenSigSendType" SG_ 1006 VID_Obj_12_StdD_InvTTC 0;
BA_ "PF_Sig_Name" SG_ 1006 VID_Obj_12_StdD_InvTTC "BV1_Obj_12_InvTTCBildebStdA";
BA_ "GenSigStartValue" SG_ 1006 VID_Obj_12_Ang_Overlap_EgoLane_R 511;
BA_ "GenSigSendType" SG_ 1006 VID_Obj_12_Ang_Overlap_EgoLane_R 0;
BA_ "PF_Sig_Name" SG_ 1006 VID_Obj_12_Ang_Overlap_EgoLane_R "BV1_Obj_12_UeberdWnklEgoSpurR";
BA_ "GenSigStartValue" SG_ 1006 VID_Obj_12_Ang_Overlap_EgoLane_L 511;
BA_ "GenSigSendType" SG_ 1006 VID_Obj_12_Ang_Overlap_EgoLane_L 0;
BA_ "PF_Sig_Name" SG_ 1006 VID_Obj_12_Ang_Overlap_EgoLane_L "BV1_Obj_12_UeberdWnklEgoSpurL";
BA_ "GenSigStartValue" SG_ 1006 VID_Obj_12_Obj_Age 4095;
BA_ "GenSigSendType" SG_ 1006 VID_Obj_12_Obj_Age 0;
BA_ "PF_Sig_Name" SG_ 1006 VID_Obj_12_Obj_Age "BV1_Obj_12_Alter";
BA_ "GenSigSendType" SG_ 1006 VID_Obj_12_BrakeLight 0;
BA_ "PF_Sig_Name" SG_ 1006 VID_Obj_12_BrakeLight "BV1_Obj_12_BremsLicht";
BA_ "GenSigFuncType" SG_ 1007 VID_Obj_12_D_ChkSum 2;
BA_ "GenSigSendType" SG_ 1007 VID_Obj_12_D_ChkSum 0;
BA_ "PF_Sig_Name" SG_ 1007 VID_Obj_12_D_ChkSum "BV_Obj_12_D_CRC";
BA_ "GenSigFuncType" SG_ 1007 VID_Obj_12_D_MsgCnt 1;
BA_ "GenSigSendType" SG_ 1007 VID_Obj_12_D_MsgCnt 0;
BA_ "PF_Sig_Name" SG_ 1007 VID_Obj_12_D_MsgCnt "BV_Obj_12_D_BZ";
BA_ "GenSigSendType" SG_ 1007 VID_Obj_12_D_BlockCnt 3;
BA_ "PF_Sig_Name" SG_ 1007 VID_Obj_12_D_BlockCnt "BV1_Obj_12_D_BlockZaehler";
BA_ "GenSigStartValue" SG_ 1007 VID_Obj_12_Ang_Edge_L 1024;
BA_ "GenSigSendType" SG_ 1007 VID_Obj_12_Ang_Edge_L 0;
BA_ "PF_Sig_Name" SG_ 1007 VID_Obj_12_Ang_Edge_L "BV_Objekt_12_phi_left";
BA_ "GenSigStartValue" SG_ 1007 VID_Obj_12_Ang_Edge_R 1024;
BA_ "GenSigSendType" SG_ 1007 VID_Obj_12_Ang_Edge_R 0;
BA_ "PF_Sig_Name" SG_ 1007 VID_Obj_12_Ang_Edge_R "BV_Objekt_12_phi_right";
BA_ "GenSigStartValue" SG_ 1007 VID_Obj_12_StdD_Ang_Edge_L 512;
BA_ "GenSigSendType" SG_ 1007 VID_Obj_12_StdD_Ang_Edge_L 0;
BA_ "PF_Sig_Name" SG_ 1007 VID_Obj_12_StdD_Ang_Edge_L "BV_Objekt_12_sdv_phi_left";
BA_ "GenSigStartValue" SG_ 1007 VID_Obj_12_Obj_ID 255;
BA_ "GenSigSendType" SG_ 1007 VID_Obj_12_Obj_ID 0;
BA_ "PF_Sig_Name" SG_ 1007 VID_Obj_12_Obj_ID "BV1_Obj_12_ID";
BA_ "GenSigFuncType" SG_ 915 VID_Obj_12_E_ChkSum 2;
BA_ "GenSigSendType" SG_ 915 VID_Obj_12_E_ChkSum 0;
BA_ "PF_Sig_Name" SG_ 915 VID_Obj_12_E_ChkSum "BV_Obj_12_E_CRC";
BA_ "GenSigFuncType" SG_ 915 VID_Obj_12_E_MsgCnt 1;
BA_ "GenSigSendType" SG_ 915 VID_Obj_12_E_MsgCnt 0;
BA_ "PF_Sig_Name" SG_ 915 VID_Obj_12_E_MsgCnt "BV_Obj_12_E_BZ";
BA_ "GenSigSendType" SG_ 915 VID_Obj_12_E_BlockCnt 3;
BA_ "PF_Sig_Name" SG_ 915 VID_Obj_12_E_BlockCnt "BV1_Obj_12_E_BlockZaehler";
BA_ "GenSigStartValue" SG_ 915 VID_Obj_12_Velocity_longitudinal 2046;
BA_ "GenSigSendType" SG_ 915 VID_Obj_12_Velocity_longitudinal 0;
BA_ "PF_Sig_Name" SG_ 915 VID_Obj_12_Velocity_longitudinal "BV1_Obj_12_RadialGeschw";
BA_ "GenSigStartValue" SG_ 915 VID_Obj_12_StdD_Velocity_longitu 1022;
BA_ "GenSigSendType" SG_ 915 VID_Obj_12_StdD_Velocity_longitu 0;
BA_ "PF_Sig_Name" SG_ 915 VID_Obj_12_StdD_Velocity_longitu "BV1_Obj_12_RadialGeschw_StdA";
BA_ "SystemSignalLongSymbol" SG_ 915 VID_Obj_12_StdD_Velocity_longitu "VID_Obj_12_StdD_Velocity_longitudinal";
BA_ "GenSigStartValue" SG_ 915 VID_Obj_12_StdD_Ang_Edge_R 512;
BA_ "GenSigSendType" SG_ 915 VID_Obj_12_StdD_Ang_Edge_R 0;
BA_ "PF_Sig_Name" SG_ 915 VID_Obj_12_StdD_Ang_Edge_R "BV_Objekt_12_sdv_phi_right";
BA_ "GenSigSendType" SG_ 915 VID_Obj_12_ScaleChange 0;
BA_ "PF_Sig_Name" SG_ 915 VID_Obj_12_ScaleChange "BV_Obj_12_ScaleChange";
BA_ "GenSigFuncType" SG_ 1008 VID_Obj_13_A_ChkSum 2;
BA_ "GenSigSendType" SG_ 1008 VID_Obj_13_A_ChkSum 0;
BA_ "PF_Sig_Name" SG_ 1008 VID_Obj_13_A_ChkSum "BV_Obj_13_A_CRC";
BA_ "GenSigFuncType" SG_ 1008 VID_Obj_13_A_MsgCnt 1;
BA_ "GenSigSendType" SG_ 1008 VID_Obj_13_A_MsgCnt 0;
BA_ "PF_Sig_Name" SG_ 1008 VID_Obj_13_A_MsgCnt "BV_Obj_13_A_BZ";
BA_ "GenSigSendType" SG_ 1008 VID_Obj_13_A_BlockCnt 3;
BA_ "PF_Sig_Name" SG_ 1008 VID_Obj_13_A_BlockCnt "BV1_Obj_13_A_BlockZaehler";
BA_ "GenSigStartValue" SG_ 1008 VID_Obj_13_Dist_longitude 4095;
BA_ "GenSigSendType" SG_ 1008 VID_Obj_13_Dist_longitude 0;
BA_ "PF_Sig_Name" SG_ 1008 VID_Obj_13_Dist_longitude "BV1_Obj_13_Dist_longitude";
BA_ "GenSigStartValue" SG_ 1008 VID_Obj_13_StdD_Dist_longitude 127;
BA_ "GenSigSendType" SG_ 1008 VID_Obj_13_StdD_Dist_longitude 0;
BA_ "PF_Sig_Name" SG_ 1008 VID_Obj_13_StdD_Dist_longitude "BV1_Obj_13_Dist_longitudeStdA";
BA_ "GenSigStartValue" SG_ 1008 VID_Obj_13_Ang_Center 2047;
BA_ "GenSigSendType" SG_ 1008 VID_Obj_13_Ang_Center 0;
BA_ "PF_Sig_Name" SG_ 1008 VID_Obj_13_Ang_Center "BV1_Obj_13_WnklMitte";
BA_ "GenSigSendType" SG_ 1008 VID_Obj_13_Stat_Measure 0;
BA_ "PF_Sig_Name" SG_ 1008 VID_Obj_13_Stat_Measure "BV1_Obj_13_Gemessen";
BA_ "GenSigStartValue" SG_ 1008 VID_Obj_13_StdD_Ang_Center 255;
BA_ "GenSigSendType" SG_ 1008 VID_Obj_13_StdD_Ang_Center 0;
BA_ "PF_Sig_Name" SG_ 1008 VID_Obj_13_StdD_Ang_Center "BV1_Obj_13_WnklMitteStdA";
BA_ "GenSigStartValue" SG_ 1008 VID_Obj_13_Class 15;
BA_ "GenSigSendType" SG_ 1008 VID_Obj_13_Class 0;
BA_ "PF_Sig_Name" SG_ 1008 VID_Obj_13_Class "BV1_Obj_13_Klasse";
BA_ "GenSigStartValue" SG_ 1008 VID_Obj_13_RefPoint 15;
BA_ "GenSigSendType" SG_ 1008 VID_Obj_13_RefPoint 0;
BA_ "PF_Sig_Name" SG_ 1008 VID_Obj_13_RefPoint "BV1_Obj_13_Bezugspunkt";
BA_ "GenSigFuncType" SG_ 1009 VID_Obj_13_B_ChkSum 2;
BA_ "GenSigSendType" SG_ 1009 VID_Obj_13_B_ChkSum 0;
BA_ "PF_Sig_Name" SG_ 1009 VID_Obj_13_B_ChkSum "BV_Obj_13_B_CRC";
BA_ "GenSigFuncType" SG_ 1009 VID_Obj_13_B_MsgCnt 1;
BA_ "GenSigSendType" SG_ 1009 VID_Obj_13_B_MsgCnt 0;
BA_ "PF_Sig_Name" SG_ 1009 VID_Obj_13_B_MsgCnt "BV_Obj_13_B_BZ";
BA_ "GenSigSendType" SG_ 1009 VID_Obj_13_B_BlockCnt 3;
BA_ "PF_Sig_Name" SG_ 1009 VID_Obj_13_B_BlockCnt "BV1_Obj_13_B_BlockZaehler";
BA_ "GenSigStartValue" SG_ 1009 VID_Obj_13_Ang_Width 2047;
BA_ "GenSigSendType" SG_ 1009 VID_Obj_13_Ang_Width 0;
BA_ "PF_Sig_Name" SG_ 1009 VID_Obj_13_Ang_Width "BV1_Obj_13_WnklBreite";
BA_ "GenSigStartValue" SG_ 1009 VID_Obj_13_ProbExist 127;
BA_ "GenSigSendType" SG_ 1009 VID_Obj_13_ProbExist 0;
BA_ "PF_Sig_Name" SG_ 1009 VID_Obj_13_ProbExist "BV1_Obj_13_ExistenzMass";
BA_ "GenSigStartValue" SG_ 1009 VID_Obj_13_StdD_dAng_longitude 63;
BA_ "GenSigSendType" SG_ 1009 VID_Obj_13_StdD_dAng_longitude 0;
BA_ "PF_Sig_Name" SG_ 1009 VID_Obj_13_StdD_dAng_longitude "BV1_Obj_13_WnklGeschwStdA";
BA_ "GenSigStartValue" SG_ 1009 VID_Obj_13_dAng_longitude 511;
BA_ "GenSigSendType" SG_ 1009 VID_Obj_13_dAng_longitude 0;
BA_ "PF_Sig_Name" SG_ 1009 VID_Obj_13_dAng_longitude "BV1_Obj_13_WnklGeschw";
BA_ "GenSigStartValue" SG_ 1009 VID_Obj_13_StdD_Ang_Width 255;
BA_ "GenSigSendType" SG_ 1009 VID_Obj_13_StdD_Ang_Width 0;
BA_ "PF_Sig_Name" SG_ 1009 VID_Obj_13_StdD_Ang_Width "BV1_Obj_13_WnklBreiteStdA";
BA_ "GenSigFuncType" SG_ 1010 VID_Obj_13_C_ChkSum 2;
BA_ "GenSigSendType" SG_ 1010 VID_Obj_13_C_ChkSum 0;
BA_ "PF_Sig_Name" SG_ 1010 VID_Obj_13_C_ChkSum "BV_Obj_13_C_CRC";
BA_ "GenSigFuncType" SG_ 1010 VID_Obj_13_C_MsgCnt 1;
BA_ "GenSigSendType" SG_ 1010 VID_Obj_13_C_MsgCnt 0;
BA_ "PF_Sig_Name" SG_ 1010 VID_Obj_13_C_MsgCnt "BV_Obj_13_C_BZ";
BA_ "GenSigSendType" SG_ 1010 VID_Obj_13_C_BlockCnt 3;
BA_ "PF_Sig_Name" SG_ 1010 VID_Obj_13_C_BlockCnt "BV1_Obj_13_C_BlockZaehler";
BA_ "GenSigStartValue" SG_ 1010 VID_Obj_13_InvTTC 1023;
BA_ "GenSigSendType" SG_ 1010 VID_Obj_13_InvTTC 0;
BA_ "PF_Sig_Name" SG_ 1010 VID_Obj_13_InvTTC "BV1_Obj_13_InvTTCBildeb";
BA_ "GenSigStartValue" SG_ 1010 VID_Obj_13_StdD_InvTTC 127;
BA_ "GenSigSendType" SG_ 1010 VID_Obj_13_StdD_InvTTC 0;
BA_ "PF_Sig_Name" SG_ 1010 VID_Obj_13_StdD_InvTTC "BV1_Obj_13_InvTTCBildebStdA";
BA_ "GenSigStartValue" SG_ 1010 VID_Obj_13_Ang_Overlap_EgoLane_R 511;
BA_ "GenSigSendType" SG_ 1010 VID_Obj_13_Ang_Overlap_EgoLane_R 0;
BA_ "PF_Sig_Name" SG_ 1010 VID_Obj_13_Ang_Overlap_EgoLane_R "BV1_Obj_13_UeberdWnklEgoSpurR";
BA_ "GenSigStartValue" SG_ 1010 VID_Obj_13_Ang_Overlap_EgoLane_L 511;
BA_ "GenSigSendType" SG_ 1010 VID_Obj_13_Ang_Overlap_EgoLane_L 0;
BA_ "PF_Sig_Name" SG_ 1010 VID_Obj_13_Ang_Overlap_EgoLane_L "BV1_Obj_13_UeberdWnklEgoSpurL";
BA_ "GenSigStartValue" SG_ 1010 VID_Obj_13_Obj_Age 4095;
BA_ "GenSigSendType" SG_ 1010 VID_Obj_13_Obj_Age 0;
BA_ "PF_Sig_Name" SG_ 1010 VID_Obj_13_Obj_Age "BV1_Obj_13_Alter";
BA_ "GenSigSendType" SG_ 1010 VID_Obj_13_BrakeLight 0;
BA_ "PF_Sig_Name" SG_ 1010 VID_Obj_13_BrakeLight "BV1_Obj_13_BremsLicht";
BA_ "GenSigFuncType" SG_ 1011 VID_Obj_13_D_ChkSum 2;
BA_ "GenSigSendType" SG_ 1011 VID_Obj_13_D_ChkSum 0;
BA_ "PF_Sig_Name" SG_ 1011 VID_Obj_13_D_ChkSum "BV_Obj_13_D_CRC";
BA_ "GenSigFuncType" SG_ 1011 VID_Obj_13_D_MsgCnt 1;
BA_ "GenSigSendType" SG_ 1011 VID_Obj_13_D_MsgCnt 0;
BA_ "PF_Sig_Name" SG_ 1011 VID_Obj_13_D_MsgCnt "BV_Obj_13_D_BZ";
BA_ "GenSigSendType" SG_ 1011 VID_Obj_13_D_BlockCnt 3;
BA_ "PF_Sig_Name" SG_ 1011 VID_Obj_13_D_BlockCnt "BV1_Obj_13_D_BlockZaehler";
BA_ "GenSigStartValue" SG_ 1011 VID_Obj_13_Ang_Edge_L 1024;
BA_ "GenSigSendType" SG_ 1011 VID_Obj_13_Ang_Edge_L 0;
BA_ "PF_Sig_Name" SG_ 1011 VID_Obj_13_Ang_Edge_L "BV_Objekt_13_phi_left";
BA_ "GenSigStartValue" SG_ 1011 VID_Obj_13_Ang_Edge_R 1024;
BA_ "GenSigSendType" SG_ 1011 VID_Obj_13_Ang_Edge_R 0;
BA_ "PF_Sig_Name" SG_ 1011 VID_Obj_13_Ang_Edge_R "BV_Objekt_13_phi_right";
BA_ "GenSigStartValue" SG_ 1011 VID_Obj_13_StdD_Ang_Edge_L 512;
BA_ "GenSigSendType" SG_ 1011 VID_Obj_13_StdD_Ang_Edge_L 0;
BA_ "PF_Sig_Name" SG_ 1011 VID_Obj_13_StdD_Ang_Edge_L "BV_Objekt_13_sdv_phi_left";
BA_ "GenSigStartValue" SG_ 1011 VID_Obj_13_Obj_ID 255;
BA_ "GenSigSendType" SG_ 1011 VID_Obj_13_Obj_ID 0;
BA_ "PF_Sig_Name" SG_ 1011 VID_Obj_13_Obj_ID "BV1_Obj_13_ID";
BA_ "GenSigFuncType" SG_ 916 VID_Obj_13_E_ChkSum 2;
BA_ "GenSigSendType" SG_ 916 VID_Obj_13_E_ChkSum 0;
BA_ "PF_Sig_Name" SG_ 916 VID_Obj_13_E_ChkSum "BV_Obj_13_E_CRC";
BA_ "GenSigFuncType" SG_ 916 VID_Obj_13_E_MsgCnt 1;
BA_ "GenSigSendType" SG_ 916 VID_Obj_13_E_MsgCnt 0;
BA_ "PF_Sig_Name" SG_ 916 VID_Obj_13_E_MsgCnt "BV_Obj_13_E_BZ";
BA_ "GenSigSendType" SG_ 916 VID_Obj_13_E_BlockCnt 3;
BA_ "PF_Sig_Name" SG_ 916 VID_Obj_13_E_BlockCnt "BV1_Obj_13_E_BlockZaehler";
BA_ "GenSigStartValue" SG_ 916 VID_Obj_13_Velocity_longitudinal 2046;
BA_ "GenSigSendType" SG_ 916 VID_Obj_13_Velocity_longitudinal 0;
BA_ "PF_Sig_Name" SG_ 916 VID_Obj_13_Velocity_longitudinal "BV1_Obj_13_RadialGeschw";
BA_ "GenSigStartValue" SG_ 916 VID_Obj_13_StdD_Velocity_longitu 1022;
BA_ "GenSigSendType" SG_ 916 VID_Obj_13_StdD_Velocity_longitu 0;
BA_ "PF_Sig_Name" SG_ 916 VID_Obj_13_StdD_Velocity_longitu "BV1_Obj_13_RadialGeschw_StdA";
BA_ "SystemSignalLongSymbol" SG_ 916 VID_Obj_13_StdD_Velocity_longitu "VID_Obj_13_StdD_Velocity_longitudinal";
BA_ "GenSigStartValue" SG_ 916 VID_Obj_13_StdD_Ang_Edge_R 512;
BA_ "GenSigSendType" SG_ 916 VID_Obj_13_StdD_Ang_Edge_R 0;
BA_ "PF_Sig_Name" SG_ 916 VID_Obj_13_StdD_Ang_Edge_R "BV_Objekt_13_sdv_phi_right";
BA_ "GenSigSendType" SG_ 916 VID_Obj_13_ScaleChange 0;
BA_ "PF_Sig_Name" SG_ 916 VID_Obj_13_ScaleChange "BV_Obj_13_ScaleChange";
BA_ "GenSigFuncType" SG_ 1012 VID_Obj_14_A_ChkSum 2;
BA_ "GenSigSendType" SG_ 1012 VID_Obj_14_A_ChkSum 0;
BA_ "PF_Sig_Name" SG_ 1012 VID_Obj_14_A_ChkSum "BV_Obj_14_A_CRC";
BA_ "GenSigFuncType" SG_ 1012 VID_Obj_14_A_MsgCnt 1;
BA_ "GenSigSendType" SG_ 1012 VID_Obj_14_A_MsgCnt 0;
BA_ "PF_Sig_Name" SG_ 1012 VID_Obj_14_A_MsgCnt "BV_Obj_14_A_BZ";
BA_ "GenSigSendType" SG_ 1012 VID_Obj_14_A_BlockCnt 3;
BA_ "PF_Sig_Name" SG_ 1012 VID_Obj_14_A_BlockCnt "BV1_Obj_14_A_BlockZaehler";
BA_ "GenSigStartValue" SG_ 1012 VID_Obj_14_Dist_longitude 4095;
BA_ "GenSigSendType" SG_ 1012 VID_Obj_14_Dist_longitude 0;
BA_ "PF_Sig_Name" SG_ 1012 VID_Obj_14_Dist_longitude "BV1_Obj_14_Dist_longitude";
BA_ "GenSigStartValue" SG_ 1012 VID_Obj_14_StdD_Dist_longitude 127;
BA_ "GenSigSendType" SG_ 1012 VID_Obj_14_StdD_Dist_longitude 0;
BA_ "PF_Sig_Name" SG_ 1012 VID_Obj_14_StdD_Dist_longitude "BV1_Obj_14_Dist_longitudeStdA";
BA_ "GenSigStartValue" SG_ 1012 VID_Obj_14_Ang_Center 2047;
BA_ "GenSigSendType" SG_ 1012 VID_Obj_14_Ang_Center 0;
BA_ "PF_Sig_Name" SG_ 1012 VID_Obj_14_Ang_Center "BV1_Obj_14_WnklMitte";
BA_ "GenSigSendType" SG_ 1012 VID_Obj_14_Stat_Measure 0;
BA_ "PF_Sig_Name" SG_ 1012 VID_Obj_14_Stat_Measure "BV1_Obj_14_Gemessen";
BA_ "GenSigStartValue" SG_ 1012 VID_Obj_14_StdD_Ang_Center 255;
BA_ "GenSigSendType" SG_ 1012 VID_Obj_14_StdD_Ang_Center 0;
BA_ "PF_Sig_Name" SG_ 1012 VID_Obj_14_StdD_Ang_Center "BV1_Obj_14_WnklMitteStdA";
BA_ "GenSigStartValue" SG_ 1012 VID_Obj_14_Class 15;
BA_ "GenSigSendType" SG_ 1012 VID_Obj_14_Class 0;
BA_ "PF_Sig_Name" SG_ 1012 VID_Obj_14_Class "BV1_Obj_14_Klasse";
BA_ "GenSigStartValue" SG_ 1012 VID_Obj_14_RefPoint 15;
BA_ "GenSigSendType" SG_ 1012 VID_Obj_14_RefPoint 0;
BA_ "PF_Sig_Name" SG_ 1012 VID_Obj_14_RefPoint "BV1_Obj_14_Bezugspunkt";
BA_ "GenSigFuncType" SG_ 1013 VID_Obj_14_B_ChkSum 2;
BA_ "GenSigSendType" SG_ 1013 VID_Obj_14_B_ChkSum 0;
BA_ "PF_Sig_Name" SG_ 1013 VID_Obj_14_B_ChkSum "BV_Obj_14_B_CRC";
BA_ "GenSigFuncType" SG_ 1013 VID_Obj_14_B_MsgCnt 1;
BA_ "GenSigSendType" SG_ 1013 VID_Obj_14_B_MsgCnt 0;
BA_ "PF_Sig_Name" SG_ 1013 VID_Obj_14_B_MsgCnt "BV_Obj_14_B_BZ";
BA_ "GenSigSendType" SG_ 1013 VID_Obj_14_B_BlockCnt 3;
BA_ "PF_Sig_Name" SG_ 1013 VID_Obj_14_B_BlockCnt "BV1_Obj_14_B_BlockZaehler";
BA_ "GenSigStartValue" SG_ 1013 VID_Obj_14_Ang_Width 2047;
BA_ "GenSigSendType" SG_ 1013 VID_Obj_14_Ang_Width 0;
BA_ "PF_Sig_Name" SG_ 1013 VID_Obj_14_Ang_Width "BV1_Obj_14_WnklBreite";
BA_ "GenSigStartValue" SG_ 1013 VID_Obj_14_ProbExist 127;
BA_ "GenSigSendType" SG_ 1013 VID_Obj_14_ProbExist 0;
BA_ "PF_Sig_Name" SG_ 1013 VID_Obj_14_ProbExist "BV1_Obj_14_ExistenzMass";
BA_ "GenSigStartValue" SG_ 1013 VID_Obj_14_StdD_dAng_longitude 63;
BA_ "GenSigSendType" SG_ 1013 VID_Obj_14_StdD_dAng_longitude 0;
BA_ "PF_Sig_Name" SG_ 1013 VID_Obj_14_StdD_dAng_longitude "BV1_Obj_14_WnklGeschwStdA";
BA_ "GenSigStartValue" SG_ 1013 VID_Obj_14_dAng_longitude 511;
BA_ "GenSigSendType" SG_ 1013 VID_Obj_14_dAng_longitude 0;
BA_ "PF_Sig_Name" SG_ 1013 VID_Obj_14_dAng_longitude "BV1_Obj_14_WnklGeschw";
BA_ "GenSigStartValue" SG_ 1013 VID_Obj_14_StdD_Ang_Width 255;
BA_ "GenSigSendType" SG_ 1013 VID_Obj_14_StdD_Ang_Width 0;
BA_ "PF_Sig_Name" SG_ 1013 VID_Obj_14_StdD_Ang_Width "BV1_Obj_14_WnklBreiteStdA";
BA_ "GenSigFuncType" SG_ 1014 VID_Obj_14_C_ChkSum 2;
BA_ "GenSigSendType" SG_ 1014 VID_Obj_14_C_ChkSum 0;
BA_ "PF_Sig_Name" SG_ 1014 VID_Obj_14_C_ChkSum "BV_Obj_14_C_CRC";
BA_ "GenSigFuncType" SG_ 1014 VID_Obj_14_C_MsgCnt 1;
BA_ "GenSigSendType" SG_ 1014 VID_Obj_14_C_MsgCnt 0;
BA_ "PF_Sig_Name" SG_ 1014 VID_Obj_14_C_MsgCnt "BV_Obj_14_C_BZ";
BA_ "GenSigSendType" SG_ 1014 VID_Obj_14_C_BlockCnt 3;
BA_ "PF_Sig_Name" SG_ 1014 VID_Obj_14_C_BlockCnt "BV1_Obj_14_C_BlockZaehler";
BA_ "GenSigStartValue" SG_ 1014 VID_Obj_14_InvTTC 1023;
BA_ "GenSigSendType" SG_ 1014 VID_Obj_14_InvTTC 0;
BA_ "PF_Sig_Name" SG_ 1014 VID_Obj_14_InvTTC "BV1_Obj_14_InvTTCBildeb";
BA_ "GenSigStartValue" SG_ 1014 VID_Obj_14_StdD_InvTTC 127;
BA_ "GenSigSendType" SG_ 1014 VID_Obj_14_StdD_InvTTC 0;
BA_ "PF_Sig_Name" SG_ 1014 VID_Obj_14_StdD_InvTTC "BV1_Obj_14_InvTTCBildebStdA";
BA_ "GenSigStartValue" SG_ 1014 VID_Obj_14_Ang_Overlap_EgoLane_R 511;
BA_ "GenSigSendType" SG_ 1014 VID_Obj_14_Ang_Overlap_EgoLane_R 0;
BA_ "PF_Sig_Name" SG_ 1014 VID_Obj_14_Ang_Overlap_EgoLane_R "BV1_Obj_14_UeberdWnklEgoSpurR";
BA_ "GenSigStartValue" SG_ 1014 VID_Obj_14_Ang_Overlap_EgoLane_L 511;
BA_ "GenSigSendType" SG_ 1014 VID_Obj_14_Ang_Overlap_EgoLane_L 0;
BA_ "PF_Sig_Name" SG_ 1014 VID_Obj_14_Ang_Overlap_EgoLane_L "BV1_Obj_14_UeberdWnklEgoSpurL";
BA_ "GenSigStartValue" SG_ 1014 VID_Obj_14_Obj_Age 4095;
BA_ "GenSigSendType" SG_ 1014 VID_Obj_14_Obj_Age 0;
BA_ "PF_Sig_Name" SG_ 1014 VID_Obj_14_Obj_Age "BV1_Obj_14_Alter";
BA_ "GenSigSendType" SG_ 1014 VID_Obj_14_BrakeLight 0;
BA_ "PF_Sig_Name" SG_ 1014 VID_Obj_14_BrakeLight "BV1_Obj_14_BremsLicht";
BA_ "GenSigFuncType" SG_ 1015 VID_Obj_14_D_ChkSum 2;
BA_ "GenSigSendType" SG_ 1015 VID_Obj_14_D_ChkSum 0;
BA_ "PF_Sig_Name" SG_ 1015 VID_Obj_14_D_ChkSum "BV_Obj_14_D_CRC";
BA_ "GenSigFuncType" SG_ 1015 VID_Obj_14_D_MsgCnt 1;
BA_ "GenSigSendType" SG_ 1015 VID_Obj_14_D_MsgCnt 0;
BA_ "PF_Sig_Name" SG_ 1015 VID_Obj_14_D_MsgCnt "BV_Obj_14_D_BZ";
BA_ "GenSigSendType" SG_ 1015 VID_Obj_14_D_BlockCnt 3;
BA_ "PF_Sig_Name" SG_ 1015 VID_Obj_14_D_BlockCnt "BV1_Obj_14_D_BlockZaehler";
BA_ "GenSigStartValue" SG_ 1015 VID_Obj_14_Ang_Edge_L 1024;
BA_ "GenSigSendType" SG_ 1015 VID_Obj_14_Ang_Edge_L 0;
BA_ "PF_Sig_Name" SG_ 1015 VID_Obj_14_Ang_Edge_L "BV_Objekt_14_phi_left";
BA_ "GenSigStartValue" SG_ 1015 VID_Obj_14_Ang_Edge_R 1024;
BA_ "GenSigSendType" SG_ 1015 VID_Obj_14_Ang_Edge_R 0;
BA_ "PF_Sig_Name" SG_ 1015 VID_Obj_14_Ang_Edge_R "BV_Objekt_14_phi_right";
BA_ "GenSigStartValue" SG_ 1015 VID_Obj_14_StdD_Ang_Edge_L 512;
BA_ "GenSigSendType" SG_ 1015 VID_Obj_14_StdD_Ang_Edge_L 0;
BA_ "PF_Sig_Name" SG_ 1015 VID_Obj_14_StdD_Ang_Edge_L "BV_Objekt_14_sdv_phi_left";
BA_ "GenSigStartValue" SG_ 1015 VID_Obj_14_Obj_ID 255;
BA_ "GenSigSendType" SG_ 1015 VID_Obj_14_Obj_ID 0;
BA_ "PF_Sig_Name" SG_ 1015 VID_Obj_14_Obj_ID "BV1_Obj_14_ID";
BA_ "GenSigFuncType" SG_ 917 VID_Obj_14_E_ChkSum 2;
BA_ "GenSigSendType" SG_ 917 VID_Obj_14_E_ChkSum 0;
BA_ "PF_Sig_Name" SG_ 917 VID_Obj_14_E_ChkSum "BV_Obj_14_E_CRC";
BA_ "GenSigFuncType" SG_ 917 VID_Obj_14_E_MsgCnt 1;
BA_ "GenSigSendType" SG_ 917 VID_Obj_14_E_MsgCnt 0;
BA_ "PF_Sig_Name" SG_ 917 VID_Obj_14_E_MsgCnt "BV_Obj_14_E_BZ";
BA_ "GenSigSendType" SG_ 917 VID_Obj_14_E_BlockCnt 3;
BA_ "PF_Sig_Name" SG_ 917 VID_Obj_14_E_BlockCnt "BV1_Obj_14_E_BlockZaehler";
BA_ "GenSigStartValue" SG_ 917 VID_Obj_14_Velocity_longitudinal 2046;
BA_ "GenSigSendType" SG_ 917 VID_Obj_14_Velocity_longitudinal 0;
BA_ "PF_Sig_Name" SG_ 917 VID_Obj_14_Velocity_longitudinal "BV1_Obj_14_RadialGeschw";
BA_ "GenSigStartValue" SG_ 917 VID_Obj_14_StdD_Velocity_longitu 1022;
BA_ "GenSigSendType" SG_ 917 VID_Obj_14_StdD_Velocity_longitu 0;
BA_ "PF_Sig_Name" SG_ 917 VID_Obj_14_StdD_Velocity_longitu "BV1_Obj_14_RadialGeschw_StdA";
BA_ "SystemSignalLongSymbol" SG_ 917 VID_Obj_14_StdD_Velocity_longitu "VID_Obj_14_StdD_Velocity_longitudinal";
BA_ "GenSigStartValue" SG_ 917 VID_Obj_14_StdD_Ang_Edge_R 512;
BA_ "GenSigSendType" SG_ 917 VID_Obj_14_StdD_Ang_Edge_R 0;
BA_ "PF_Sig_Name" SG_ 917 VID_Obj_14_StdD_Ang_Edge_R "BV_Objekt_14_sdv_phi_right";
BA_ "GenSigSendType" SG_ 917 VID_Obj_14_ScaleChange 0;
BA_ "PF_Sig_Name" SG_ 917 VID_Obj_14_ScaleChange "BV_Obj_14_ScaleChange";
BA_ "GenSigFuncType" SG_ 1016 VID_Obj_15_A_ChkSum 2;
BA_ "GenSigSendType" SG_ 1016 VID_Obj_15_A_ChkSum 0;
BA_ "PF_Sig_Name" SG_ 1016 VID_Obj_15_A_ChkSum "BV_Obj_15_A_CRC";
BA_ "GenSigFuncType" SG_ 1016 VID_Obj_15_A_MsgCnt 1;
BA_ "GenSigSendType" SG_ 1016 VID_Obj_15_A_MsgCnt 0;
BA_ "PF_Sig_Name" SG_ 1016 VID_Obj_15_A_MsgCnt "BV_Obj_15_A_BZ";
BA_ "GenSigSendType" SG_ 1016 VID_Obj_15_A_BlockCnt 3;
BA_ "PF_Sig_Name" SG_ 1016 VID_Obj_15_A_BlockCnt "BV1_Obj_15_A_BlockZaehler";
BA_ "GenSigStartValue" SG_ 1016 VID_Obj_15_Dist_longitude 4095;
BA_ "GenSigSendType" SG_ 1016 VID_Obj_15_Dist_longitude 0;
BA_ "PF_Sig_Name" SG_ 1016 VID_Obj_15_Dist_longitude "BV1_Obj_15_Dist_longitude";
BA_ "GenSigStartValue" SG_ 1016 VID_Obj_15_StdD_Dist_longitude 127;
BA_ "GenSigSendType" SG_ 1016 VID_Obj_15_StdD_Dist_longitude 0;
BA_ "PF_Sig_Name" SG_ 1016 VID_Obj_15_StdD_Dist_longitude "BV1_Obj_15_Dist_longitudeStdA";
BA_ "GenSigStartValue" SG_ 1016 VID_Obj_15_Ang_Center 2047;
BA_ "GenSigSendType" SG_ 1016 VID_Obj_15_Ang_Center 0;
BA_ "PF_Sig_Name" SG_ 1016 VID_Obj_15_Ang_Center "BV1_Obj_15_WnklMitte";
BA_ "GenSigSendType" SG_ 1016 VID_Obj_15_Stat_Measure 0;
BA_ "PF_Sig_Name" SG_ 1016 VID_Obj_15_Stat_Measure "BV1_Obj_15_Gemessen";
BA_ "GenSigStartValue" SG_ 1016 VID_Obj_15_StdD_Ang_Center 255;
BA_ "GenSigSendType" SG_ 1016 VID_Obj_15_StdD_Ang_Center 0;
BA_ "PF_Sig_Name" SG_ 1016 VID_Obj_15_StdD_Ang_Center "BV1_Obj_15_WnklMitteStdA";
BA_ "GenSigStartValue" SG_ 1016 VID_Obj_15_Class 15;
BA_ "GenSigSendType" SG_ 1016 VID_Obj_15_Class 0;
BA_ "PF_Sig_Name" SG_ 1016 VID_Obj_15_Class "BV1_Obj_15_Klasse";
BA_ "GenSigStartValue" SG_ 1016 VID_Obj_15_RefPoint 15;
BA_ "GenSigSendType" SG_ 1016 VID_Obj_15_RefPoint 0;
BA_ "PF_Sig_Name" SG_ 1016 VID_Obj_15_RefPoint "BV1_Obj_15_Bezugspunkt";
BA_ "GenSigFuncType" SG_ 1017 VID_Obj_15_B_ChkSum 2;
BA_ "GenSigSendType" SG_ 1017 VID_Obj_15_B_ChkSum 0;
BA_ "PF_Sig_Name" SG_ 1017 VID_Obj_15_B_ChkSum "BV_Obj_15_B_CRC";
BA_ "GenSigFuncType" SG_ 1017 VID_Obj_15_B_MsgCnt 1;
BA_ "GenSigSendType" SG_ 1017 VID_Obj_15_B_MsgCnt 0;
BA_ "PF_Sig_Name" SG_ 1017 VID_Obj_15_B_MsgCnt "BV_Obj_15_B_BZ";
BA_ "GenSigSendType" SG_ 1017 VID_Obj_15_B_BlockCnt 3;
BA_ "PF_Sig_Name" SG_ 1017 VID_Obj_15_B_BlockCnt "BV1_Obj_15_B_BlockZaehler";
BA_ "GenSigStartValue" SG_ 1017 VID_Obj_15_Ang_Width 2047;
BA_ "GenSigSendType" SG_ 1017 VID_Obj_15_Ang_Width 0;
BA_ "PF_Sig_Name" SG_ 1017 VID_Obj_15_Ang_Width "BV1_Obj_15_WnklBreite";
BA_ "GenSigStartValue" SG_ 1017 VID_Obj_15_ProbExist 127;
BA_ "GenSigSendType" SG_ 1017 VID_Obj_15_ProbExist 0;
BA_ "PF_Sig_Name" SG_ 1017 VID_Obj_15_ProbExist "BV1_Obj_15_ExistenzMass";
BA_ "GenSigStartValue" SG_ 1017 VID_Obj_15_StdD_dAng_longitude 63;
BA_ "GenSigSendType" SG_ 1017 VID_Obj_15_StdD_dAng_longitude 0;
BA_ "PF_Sig_Name" SG_ 1017 VID_Obj_15_StdD_dAng_longitude "BV1_Obj_15_WnklGeschwStdA";
BA_ "GenSigStartValue" SG_ 1017 VID_Obj_15_dAng_longitude 511;
BA_ "GenSigSendType" SG_ 1017 VID_Obj_15_dAng_longitude 0;
BA_ "PF_Sig_Name" SG_ 1017 VID_Obj_15_dAng_longitude "BV1_Obj_15_WnklGeschw";
BA_ "GenSigStartValue" SG_ 1017 VID_Obj_15_StdD_Ang_Width 255;
BA_ "GenSigSendType" SG_ 1017 VID_Obj_15_StdD_Ang_Width 0;
BA_ "PF_Sig_Name" SG_ 1017 VID_Obj_15_StdD_Ang_Width "BV1_Obj_15_WnklBreiteStdA";
BA_ "GenSigFuncType" SG_ 1018 VID_Obj_15_C_ChkSum 2;
BA_ "GenSigSendType" SG_ 1018 VID_Obj_15_C_ChkSum 0;
BA_ "PF_Sig_Name" SG_ 1018 VID_Obj_15_C_ChkSum "BV_Obj_15_C_CRC";
BA_ "GenSigFuncType" SG_ 1018 VID_Obj_15_C_MsgCnt 1;
BA_ "GenSigSendType" SG_ 1018 VID_Obj_15_C_MsgCnt 0;
BA_ "PF_Sig_Name" SG_ 1018 VID_Obj_15_C_MsgCnt "BV_Obj_15_C_BZ";
BA_ "GenSigSendType" SG_ 1018 VID_Obj_15_C_BlockCnt 3;
BA_ "PF_Sig_Name" SG_ 1018 VID_Obj_15_C_BlockCnt "BV1_Obj_15_C_BlockZaehler";
BA_ "GenSigStartValue" SG_ 1018 VID_Obj_15_InvTTC 1023;
BA_ "GenSigSendType" SG_ 1018 VID_Obj_15_InvTTC 0;
BA_ "PF_Sig_Name" SG_ 1018 VID_Obj_15_InvTTC "BV1_Obj_15_InvTTCBildeb";
BA_ "GenSigStartValue" SG_ 1018 VID_Obj_15_StdD_InvTTC 127;
BA_ "GenSigSendType" SG_ 1018 VID_Obj_15_StdD_InvTTC 0;
BA_ "PF_Sig_Name" SG_ 1018 VID_Obj_15_StdD_InvTTC "BV1_Obj_15_InvTTCBildebStdA";
BA_ "GenSigStartValue" SG_ 1018 VID_Obj_15_Ang_Overlap_EgoLane_R 511;
BA_ "GenSigSendType" SG_ 1018 VID_Obj_15_Ang_Overlap_EgoLane_R 0;
BA_ "PF_Sig_Name" SG_ 1018 VID_Obj_15_Ang_Overlap_EgoLane_R "BV1_Obj_15_UeberdWnklEgoSpurR";
BA_ "GenSigStartValue" SG_ 1018 VID_Obj_15_Ang_Overlap_EgoLane_L 511;
BA_ "GenSigSendType" SG_ 1018 VID_Obj_15_Ang_Overlap_EgoLane_L 0;
BA_ "PF_Sig_Name" SG_ 1018 VID_Obj_15_Ang_Overlap_EgoLane_L "BV1_Obj_15_UeberdWnklEgoSpurL";
BA_ "GenSigStartValue" SG_ 1018 VID_Obj_15_Obj_Age 4095;
BA_ "GenSigSendType" SG_ 1018 VID_Obj_15_Obj_Age 0;
BA_ "PF_Sig_Name" SG_ 1018 VID_Obj_15_Obj_Age "BV1_Obj_15_Alter";
BA_ "GenSigSendType" SG_ 1018 VID_Obj_15_BrakeLight 0;
BA_ "PF_Sig_Name" SG_ 1018 VID_Obj_15_BrakeLight "BV1_Obj_15_BremsLicht";
BA_ "GenSigFuncType" SG_ 1019 VID_Obj_15_D_ChkSum 2;
BA_ "GenSigSendType" SG_ 1019 VID_Obj_15_D_ChkSum 0;
BA_ "PF_Sig_Name" SG_ 1019 VID_Obj_15_D_ChkSum "BV_Obj_15_D_CRC";
BA_ "GenSigFuncType" SG_ 1019 VID_Obj_15_D_MsgCnt 1;
BA_ "GenSigSendType" SG_ 1019 VID_Obj_15_D_MsgCnt 0;
BA_ "PF_Sig_Name" SG_ 1019 VID_Obj_15_D_MsgCnt "BV_Obj_15_D_BZ";
BA_ "GenSigSendType" SG_ 1019 VID_Obj_15_D_BlockCnt 3;
BA_ "PF_Sig_Name" SG_ 1019 VID_Obj_15_D_BlockCnt "BV1_Obj_15_D_BlockZaehler";
BA_ "GenSigStartValue" SG_ 1019 VID_Obj_15_Ang_Edge_L 1024;
BA_ "GenSigSendType" SG_ 1019 VID_Obj_15_Ang_Edge_L 0;
BA_ "PF_Sig_Name" SG_ 1019 VID_Obj_15_Ang_Edge_L "BV_Objekt_15_phi_left";
BA_ "GenSigStartValue" SG_ 1019 VID_Obj_15_Ang_Edge_R 1024;
BA_ "GenSigSendType" SG_ 1019 VID_Obj_15_Ang_Edge_R 0;
BA_ "PF_Sig_Name" SG_ 1019 VID_Obj_15_Ang_Edge_R "BV_Objekt_15_phi_right";
BA_ "GenSigStartValue" SG_ 1019 VID_Obj_15_StdD_Ang_Edge_L 512;
BA_ "GenSigSendType" SG_ 1019 VID_Obj_15_StdD_Ang_Edge_L 0;
BA_ "PF_Sig_Name" SG_ 1019 VID_Obj_15_StdD_Ang_Edge_L "BV_Objekt_15_sdv_phi_left";
BA_ "GenSigStartValue" SG_ 1019 VID_Obj_15_Obj_ID 255;
BA_ "GenSigSendType" SG_ 1019 VID_Obj_15_Obj_ID 0;
BA_ "PF_Sig_Name" SG_ 1019 VID_Obj_15_Obj_ID "BV1_Obj_15_ID";
BA_ "GenSigFuncType" SG_ 918 VID_Obj_15_E_ChkSum 2;
BA_ "GenSigSendType" SG_ 918 VID_Obj_15_E_ChkSum 0;
BA_ "PF_Sig_Name" SG_ 918 VID_Obj_15_E_ChkSum "BV_Obj_15_E_CRC";
BA_ "GenSigFuncType" SG_ 918 VID_Obj_15_E_MsgCnt 1;
BA_ "GenSigSendType" SG_ 918 VID_Obj_15_E_MsgCnt 0;
BA_ "PF_Sig_Name" SG_ 918 VID_Obj_15_E_MsgCnt "BV_Obj_15_E_BZ";
BA_ "GenSigSendType" SG_ 918 VID_Obj_15_E_BlockCnt 3;
BA_ "PF_Sig_Name" SG_ 918 VID_Obj_15_E_BlockCnt "BV1_Obj_15_E_BlockZaehler";
BA_ "GenSigStartValue" SG_ 918 VID_Obj_15_Velocity_longitudinal 2046;
BA_ "GenSigSendType" SG_ 918 VID_Obj_15_Velocity_longitudinal 0;
BA_ "PF_Sig_Name" SG_ 918 VID_Obj_15_Velocity_longitudinal "BV1_Obj_15_RadialGeschw";
BA_ "GenSigStartValue" SG_ 918 VID_Obj_15_StdD_Velocity_longitu 1022;
BA_ "GenSigSendType" SG_ 918 VID_Obj_15_StdD_Velocity_longitu 0;
BA_ "PF_Sig_Name" SG_ 918 VID_Obj_15_StdD_Velocity_longitu "BV1_Obj_15_RadialGeschw_StdA";
BA_ "SystemSignalLongSymbol" SG_ 918 VID_Obj_15_StdD_Velocity_longitu "VID_Obj_15_StdD_Velocity_longitudinal";
BA_ "GenSigStartValue" SG_ 918 VID_Obj_15_StdD_Ang_Edge_R 512;
BA_ "GenSigSendType" SG_ 918 VID_Obj_15_StdD_Ang_Edge_R 0;
BA_ "PF_Sig_Name" SG_ 918 VID_Obj_15_StdD_Ang_Edge_R "BV_Objekt_15_sdv_phi_right";
BA_ "GenSigSendType" SG_ 918 VID_Obj_15_ScaleChange 0;
BA_ "PF_Sig_Name" SG_ 918 VID_Obj_15_ScaleChange "BV_Obj_15_ScaleChange";
BA_ "GenSigFuncType" SG_ 1020 VID_Obj_16_A_ChkSum 2;
BA_ "GenSigSendType" SG_ 1020 VID_Obj_16_A_ChkSum 0;
BA_ "PF_Sig_Name" SG_ 1020 VID_Obj_16_A_ChkSum "BV_Obj_16_A_CRC";
BA_ "GenSigFuncType" SG_ 1020 VID_Obj_16_A_MsgCnt 1;
BA_ "GenSigSendType" SG_ 1020 VID_Obj_16_A_MsgCnt 0;
BA_ "PF_Sig_Name" SG_ 1020 VID_Obj_16_A_MsgCnt "BV_Obj_16_A_BZ";
BA_ "GenSigSendType" SG_ 1020 VID_Obj_16_A_BlockCnt 3;
BA_ "PF_Sig_Name" SG_ 1020 VID_Obj_16_A_BlockCnt "BV1_Obj_16_A_BlockZaehler";
BA_ "GenSigStartValue" SG_ 1020 VID_Obj_16_Dist_longitude 4095;
BA_ "GenSigSendType" SG_ 1020 VID_Obj_16_Dist_longitude 0;
BA_ "PF_Sig_Name" SG_ 1020 VID_Obj_16_Dist_longitude "BV1_Obj_16_Dist_longitude";
BA_ "GenSigStartValue" SG_ 1020 VID_Obj_16_StdD_Dist_longitude 127;
BA_ "GenSigSendType" SG_ 1020 VID_Obj_16_StdD_Dist_longitude 0;
BA_ "PF_Sig_Name" SG_ 1020 VID_Obj_16_StdD_Dist_longitude "BV1_Obj_16_Dist_longitudeStdA";
BA_ "GenSigStartValue" SG_ 1020 VID_Obj_16_Ang_Center 2047;
BA_ "GenSigSendType" SG_ 1020 VID_Obj_16_Ang_Center 0;
BA_ "PF_Sig_Name" SG_ 1020 VID_Obj_16_Ang_Center "BV1_Obj_16_WnklMitte";
BA_ "GenSigSendType" SG_ 1020 VID_Obj_16_Stat_Measure 0;
BA_ "PF_Sig_Name" SG_ 1020 VID_Obj_16_Stat_Measure "BV1_Obj_16_Gemessen";
BA_ "GenSigStartValue" SG_ 1020 VID_Obj_16_StdD_Ang_Center 255;
BA_ "GenSigSendType" SG_ 1020 VID_Obj_16_StdD_Ang_Center 0;
BA_ "PF_Sig_Name" SG_ 1020 VID_Obj_16_StdD_Ang_Center "BV1_Obj_16_WnklMitteStdA";
BA_ "GenSigStartValue" SG_ 1020 VID_Obj_16_Class 15;
BA_ "GenSigSendType" SG_ 1020 VID_Obj_16_Class 0;
BA_ "PF_Sig_Name" SG_ 1020 VID_Obj_16_Class "BV1_Obj_16_Klasse";
BA_ "GenSigStartValue" SG_ 1020 VID_Obj_16_RefPoint 15;
BA_ "GenSigSendType" SG_ 1020 VID_Obj_16_RefPoint 0;
BA_ "PF_Sig_Name" SG_ 1020 VID_Obj_16_RefPoint "BV1_Obj_16_Bezugspunkt";
BA_ "GenSigFuncType" SG_ 1021 VID_Obj_16_B_ChkSum 2;
BA_ "GenSigSendType" SG_ 1021 VID_Obj_16_B_ChkSum 0;
BA_ "PF_Sig_Name" SG_ 1021 VID_Obj_16_B_ChkSum "BV_Obj_16_B_CRC";
BA_ "GenSigFuncType" SG_ 1021 VID_Obj_16_B_MsgCnt 1;
BA_ "GenSigSendType" SG_ 1021 VID_Obj_16_B_MsgCnt 0;
BA_ "PF_Sig_Name" SG_ 1021 VID_Obj_16_B_MsgCnt "BV_Obj_16_B_BZ";
BA_ "GenSigSendType" SG_ 1021 VID_Obj_16_B_BlockCnt 3;
BA_ "PF_Sig_Name" SG_ 1021 VID_Obj_16_B_BlockCnt "BV1_Obj_16_B_BlockZaehler";
BA_ "GenSigStartValue" SG_ 1021 VID_Obj_16_Ang_Width 2047;
BA_ "GenSigSendType" SG_ 1021 VID_Obj_16_Ang_Width 0;
BA_ "PF_Sig_Name" SG_ 1021 VID_Obj_16_Ang_Width "BV1_Obj_16_WnklBreite";
BA_ "GenSigStartValue" SG_ 1021 VID_Obj_16_ProbExist 127;
BA_ "GenSigSendType" SG_ 1021 VID_Obj_16_ProbExist 0;
BA_ "PF_Sig_Name" SG_ 1021 VID_Obj_16_ProbExist "BV1_Obj_16_ExistenzMass";
BA_ "GenSigStartValue" SG_ 1021 VID_Obj_16_StdD_dAng_longitude 63;
BA_ "GenSigSendType" SG_ 1021 VID_Obj_16_StdD_dAng_longitude 0;
BA_ "PF_Sig_Name" SG_ 1021 VID_Obj_16_StdD_dAng_longitude "BV1_Obj_16_WnklGeschwStdA";
BA_ "GenSigStartValue" SG_ 1021 VID_Obj_16_dAng_longitude 511;
BA_ "GenSigSendType" SG_ 1021 VID_Obj_16_dAng_longitude 0;
BA_ "PF_Sig_Name" SG_ 1021 VID_Obj_16_dAng_longitude "BV1_Obj_16_WnklGeschw";
BA_ "GenSigStartValue" SG_ 1021 VID_Obj_16_StdD_Ang_Width 255;
BA_ "GenSigSendType" SG_ 1021 VID_Obj_16_StdD_Ang_Width 0;
BA_ "PF_Sig_Name" SG_ 1021 VID_Obj_16_StdD_Ang_Width "BV1_Obj_16_WnklBreiteStdA";
BA_ "GenSigFuncType" SG_ 1022 VID_Obj_16_C_ChkSum 2;
BA_ "GenSigSendType" SG_ 1022 VID_Obj_16_C_ChkSum 0;
BA_ "PF_Sig_Name" SG_ 1022 VID_Obj_16_C_ChkSum "BV_Obj_16_C_CRC";
BA_ "GenSigFuncType" SG_ 1022 VID_Obj_16_C_MsgCnt 1;
BA_ "GenSigSendType" SG_ 1022 VID_Obj_16_C_MsgCnt 0;
BA_ "PF_Sig_Name" SG_ 1022 VID_Obj_16_C_MsgCnt "BV_Obj_16_C_BZ";
BA_ "GenSigSendType" SG_ 1022 VID_Obj_16_C_BlockCnt 3;
BA_ "PF_Sig_Name" SG_ 1022 VID_Obj_16_C_BlockCnt "BV1_Obj_16_C_BlockZaehler";
BA_ "GenSigStartValue" SG_ 1022 VID_Obj_16_InvTTC 1023;
BA_ "GenSigSendType" SG_ 1022 VID_Obj_16_InvTTC 0;
BA_ "PF_Sig_Name" SG_ 1022 VID_Obj_16_InvTTC "BV1_Obj_16_InvTTCBildeb";
BA_ "GenSigStartValue" SG_ 1022 VID_Obj_16_StdD_InvTTC 127;
BA_ "GenSigSendType" SG_ 1022 VID_Obj_16_StdD_InvTTC 0;
BA_ "PF_Sig_Name" SG_ 1022 VID_Obj_16_StdD_InvTTC "BV1_Obj_16_InvTTCBildebStdA";
BA_ "GenSigStartValue" SG_ 1022 VID_Obj_16_Ang_Overlap_EgoLane_R 511;
BA_ "GenSigSendType" SG_ 1022 VID_Obj_16_Ang_Overlap_EgoLane_R 0;
BA_ "PF_Sig_Name" SG_ 1022 VID_Obj_16_Ang_Overlap_EgoLane_R "BV1_Obj_16_UeberdWnklEgoSpurR";
BA_ "GenSigStartValue" SG_ 1022 VID_Obj_16_Ang_Overlap_EgoLane_L 511;
BA_ "GenSigSendType" SG_ 1022 VID_Obj_16_Ang_Overlap_EgoLane_L 0;
BA_ "PF_Sig_Name" SG_ 1022 VID_Obj_16_Ang_Overlap_EgoLane_L "BV1_Obj_16_UeberdWnklEgoSpurL";
BA_ "GenSigStartValue" SG_ 1022 VID_Obj_16_Obj_Age 4095;
BA_ "GenSigSendType" SG_ 1022 VID_Obj_16_Obj_Age 0;
BA_ "PF_Sig_Name" SG_ 1022 VID_Obj_16_Obj_Age "BV1_Obj_16_Alter";
BA_ "GenSigSendType" SG_ 1022 VID_Obj_16_BrakeLight 0;
BA_ "PF_Sig_Name" SG_ 1022 VID_Obj_16_BrakeLight "BV1_Obj_16_BremsLicht";
BA_ "GenSigFuncType" SG_ 1023 VID_Obj_16_D_ChkSum 2;
BA_ "GenSigSendType" SG_ 1023 VID_Obj_16_D_ChkSum 0;
BA_ "PF_Sig_Name" SG_ 1023 VID_Obj_16_D_ChkSum "BV_Obj_16_D_CRC";
BA_ "GenSigFuncType" SG_ 1023 VID_Obj_16_D_MsgCnt 1;
BA_ "GenSigSendType" SG_ 1023 VID_Obj_16_D_MsgCnt 0;
BA_ "PF_Sig_Name" SG_ 1023 VID_Obj_16_D_MsgCnt "BV_Obj_16_D_BZ";
BA_ "GenSigSendType" SG_ 1023 VID_Obj_16_D_BlockCnt 3;
BA_ "PF_Sig_Name" SG_ 1023 VID_Obj_16_D_BlockCnt "BV1_Obj_16_D_BlockZaehler";
BA_ "GenSigStartValue" SG_ 1023 VID_Obj_16_Ang_Edge_L 1024;
BA_ "GenSigSendType" SG_ 1023 VID_Obj_16_Ang_Edge_L 0;
BA_ "PF_Sig_Name" SG_ 1023 VID_Obj_16_Ang_Edge_L "BV_Objekt_16_phi_left";
BA_ "GenSigStartValue" SG_ 1023 VID_Obj_16_Ang_Edge_R 1024;
BA_ "GenSigSendType" SG_ 1023 VID_Obj_16_Ang_Edge_R 0;
BA_ "PF_Sig_Name" SG_ 1023 VID_Obj_16_Ang_Edge_R "BV_Objekt_16_phi_right";
BA_ "GenSigStartValue" SG_ 1023 VID_Obj_16_StdD_Ang_Edge_L 512;
BA_ "GenSigSendType" SG_ 1023 VID_Obj_16_StdD_Ang_Edge_L 0;
BA_ "PF_Sig_Name" SG_ 1023 VID_Obj_16_StdD_Ang_Edge_L "BV_Objekt_16_sdv_phi_left";
BA_ "GenSigStartValue" SG_ 1023 VID_Obj_16_Obj_ID 255;
BA_ "GenSigSendType" SG_ 1023 VID_Obj_16_Obj_ID 0;
BA_ "PF_Sig_Name" SG_ 1023 VID_Obj_16_Obj_ID "BV1_Obj_16_ID";
BA_ "GenSigFuncType" SG_ 919 VID_Obj_16_E_ChkSum 2;
BA_ "GenSigSendType" SG_ 919 VID_Obj_16_E_ChkSum 0;
BA_ "PF_Sig_Name" SG_ 919 VID_Obj_16_E_ChkSum "BV_Obj_16_E_CRC";
BA_ "GenSigFuncType" SG_ 919 VID_Obj_16_E_MsgCnt 1;
BA_ "GenSigSendType" SG_ 919 VID_Obj_16_E_MsgCnt 0;
BA_ "PF_Sig_Name" SG_ 919 VID_Obj_16_E_MsgCnt "BV_Obj_16_E_BZ";
BA_ "GenSigSendType" SG_ 919 VID_Obj_16_E_BlockCnt 3;
BA_ "PF_Sig_Name" SG_ 919 VID_Obj_16_E_BlockCnt "BV1_Obj_16_E_BlockZaehler";
BA_ "GenSigStartValue" SG_ 919 VID_Obj_16_Velocity_longitudinal 2046;
BA_ "GenSigSendType" SG_ 919 VID_Obj_16_Velocity_longitudinal 0;
BA_ "PF_Sig_Name" SG_ 919 VID_Obj_16_Velocity_longitudinal "BV1_Obj_16_RadialGeschw";
BA_ "GenSigStartValue" SG_ 919 VID_Obj_16_StdD_Velocity_longitu 1022;
BA_ "GenSigSendType" SG_ 919 VID_Obj_16_StdD_Velocity_longitu 0;
BA_ "PF_Sig_Name" SG_ 919 VID_Obj_16_StdD_Velocity_longitu "BV1_Obj_16_RadialGeschw_StdA";
BA_ "SystemSignalLongSymbol" SG_ 919 VID_Obj_16_StdD_Velocity_longitu "VID_Obj_16_StdD_Velocity_longitudinal";
BA_ "GenSigStartValue" SG_ 919 VID_Obj_16_StdD_Ang_Edge_R 512;
BA_ "GenSigSendType" SG_ 919 VID_Obj_16_StdD_Ang_Edge_R 0;
BA_ "PF_Sig_Name" SG_ 919 VID_Obj_16_StdD_Ang_Edge_R "BV_Objekt_16_sdv_phi_right";
BA_ "GenSigSendType" SG_ 919 VID_Obj_16_ScaleChange 0;
BA_ "PF_Sig_Name" SG_ 919 VID_Obj_16_ScaleChange "BV_Obj_16_ScaleChange";
BA_ "PF_Sig_Name" SG_ 848 RDR_Stat_HostPedestrianStatus "";
BA_ "GenSigSendType" SG_ 848 RDR_Stat_HostPedestrianStatus 0;
BA_ "PF_Sig_Name" SG_ 848 RDR_Stat_ACCSwitchButton "";
BA_ "GenSigSendType" SG_ 848 RDR_Stat_ACCSwitchButton 0;
BA_ "GenSigFuncType" SG_ 848 RDR_Stat_ChkSum 2;
BA_ "GenSigSendType" SG_ 848 RDR_Stat_ChkSum 0;
BA_ "PF_Sig_Name" SG_ 848 RDR_Stat_ChkSum "RDR1_Header_CRC";
BA_ "GenSigFuncType" SG_ 848 RDR_Stat_MsgCnt 1;
BA_ "GenSigSendType" SG_ 848 RDR_Stat_MsgCnt 0;
BA_ "PF_Sig_Name" SG_ 848 RDR_Stat_MsgCnt "RDR1_Header_BZ";
BA_ "GenSigSendType" SG_ 848 RDR_Stat_BlockCnt 0;
BA_ "PF_Sig_Name" SG_ 848 RDR_Stat_BlockCnt "RDR1_Header_BlockZaehler";
BA_ "GenSigSendType" SG_ 848 RDR_Stat_ObjDataAge 0;
BA_ "PF_Sig_Name" SG_ 848 RDR_Stat_ObjDataAge "RDR1_Objektdatenalter";
BA_ "Fehlerwert" SG_ 848 RDR_Stat_PED_Brake 3;
BA_ "GenSigSendType" SG_ 848 RDR_Stat_PED_Brake 0;
BA_ "PF_Sig_Name" SG_ 848 RDR_Stat_PED_Brake "FGN_Status";
BA_ "GenSigSendType" SG_ 848 RDR_Stat_blindness_det 0;
BA_ "PF_Sig_Name" SG_ 848 RDR_Stat_blindness_det "RDR1_Blindheit_erkannt";
BA_ "GenSigSendType" SG_ 848 RDR_Stat_Avail 0;
BA_ "PF_Sig_Name" SG_ 848 RDR_Stat_Avail "RDR1_relev_Nichtverfuegbarkeit";
BA_ "GenSigSendType" SG_ 848 RDR_Stat_Error 0;
BA_ "PF_Sig_Name" SG_ 848 RDR_Stat_Error "RDR1_relevanter_Fehler";
BA_ "GenSigFuncType" SG_ 849 RDR_Obj_01_ChkSum 2;
BA_ "GenSigSendType" SG_ 849 RDR_Obj_01_ChkSum 0;
BA_ "PF_Sig_Name" SG_ 849 RDR_Obj_01_ChkSum "RDR1_Obj_01_CRC";
BA_ "GenSigFuncType" SG_ 849 RDR_Obj_01_MsgCnt 1;
BA_ "GenSigSendType" SG_ 849 RDR_Obj_01_MsgCnt 0;
BA_ "PF_Sig_Name" SG_ 849 RDR_Obj_01_MsgCnt "RDR1_Obj_01_BZ";
BA_ "GenSigSendType" SG_ 849 RDR_Obj_01_BlockCnt 0;
BA_ "PF_Sig_Name" SG_ 849 RDR_Obj_01_BlockCnt "RDR1_Obj_01_BlockZaehler";
BA_ "GenSigSendType" SG_ 849 RDR_Obj_01_dx_v 0;
BA_ "PF_Sig_Name" SG_ 849 RDR_Obj_01_dx_v "RDR1_Obj_01_dx_v";
BA_ "GenSigStartValue" SG_ 849 RDR_Obj_01_dy_v 512;
BA_ "GenSigSendType" SG_ 849 RDR_Obj_01_dy_v 0;
BA_ "PF_Sig_Name" SG_ 849 RDR_Obj_01_dy_v "RDR1_Obj_01_dy_v";
BA_ "GenSigSendType" SG_ 849 RDR_Obj_01_Obj_Obj_ID 0;
BA_ "PF_Sig_Name" SG_ 849 RDR_Obj_01_Obj_Obj_ID "RDR1_Obj_01_Nummer";
BA_ "GenSigStartValue" SG_ 849 RDR_Obj_01_vx_v 512;
BA_ "GenSigSendType" SG_ 849 RDR_Obj_01_vx_v 0;
BA_ "PF_Sig_Name" SG_ 849 RDR_Obj_01_vx_v "RDR1_Obj_01_vx_v";
BA_ "GenSigSendType" SG_ 849 RDR_Obj_01_RFF 0;
BA_ "PF_Sig_Name" SG_ 849 RDR_Obj_01_RFF "RDR1_Obj_01_RFF";
BA_ "GenSigFuncType" SG_ 850 RDR_Obj_02_ChkSum 2;
BA_ "GenSigSendType" SG_ 850 RDR_Obj_02_ChkSum 0;
BA_ "PF_Sig_Name" SG_ 850 RDR_Obj_02_ChkSum "RDR1_Obj_02_CRC";
BA_ "GenSigFuncType" SG_ 850 RDR_Obj_02_MsgCnt 1;
BA_ "GenSigSendType" SG_ 850 RDR_Obj_02_MsgCnt 0;
BA_ "PF_Sig_Name" SG_ 850 RDR_Obj_02_MsgCnt "RDR1_Obj_02_BZ";
BA_ "GenSigSendType" SG_ 850 RDR_Obj_02_BlockCnt 0;
BA_ "PF_Sig_Name" SG_ 850 RDR_Obj_02_BlockCnt "RDR1_Obj_02_BlockZaehler";
BA_ "GenSigSendType" SG_ 850 RDR_Obj_02_dx_v 0;
BA_ "PF_Sig_Name" SG_ 850 RDR_Obj_02_dx_v "RDR1_Obj_02_dx_v";
BA_ "GenSigStartValue" SG_ 850 RDR_Obj_02_dy_v 512;
BA_ "GenSigSendType" SG_ 850 RDR_Obj_02_dy_v 0;
BA_ "PF_Sig_Name" SG_ 850 RDR_Obj_02_dy_v "RDR1_Obj_02_dy_v";
BA_ "GenSigSendType" SG_ 850 RDR_Obj_02_Obj_Obj_ID 0;
BA_ "PF_Sig_Name" SG_ 850 RDR_Obj_02_Obj_Obj_ID "RDR1_Obj_02_Nummer";
BA_ "GenSigStartValue" SG_ 850 RDR_Obj_02_vx_v 512;
BA_ "GenSigSendType" SG_ 850 RDR_Obj_02_vx_v 0;
BA_ "PF_Sig_Name" SG_ 850 RDR_Obj_02_vx_v "RDR1_Obj_02_vx_v";
BA_ "GenSigSendType" SG_ 850 RDR_Obj_02_RFF 0;
BA_ "PF_Sig_Name" SG_ 850 RDR_Obj_02_RFF "RDR1_Obj_02_RFF";
BA_ "GenSigFuncType" SG_ 851 RDR_Obj_03_ChkSum 2;
BA_ "GenSigSendType" SG_ 851 RDR_Obj_03_ChkSum 0;
BA_ "PF_Sig_Name" SG_ 851 RDR_Obj_03_ChkSum "RDR1_Obj_03_CRC";
BA_ "GenSigFuncType" SG_ 851 RDR_Obj_03_MsgCnt 1;
BA_ "GenSigSendType" SG_ 851 RDR_Obj_03_MsgCnt 0;
BA_ "PF_Sig_Name" SG_ 851 RDR_Obj_03_MsgCnt "RDR1_Obj_03_BZ";
BA_ "GenSigSendType" SG_ 851 RDR_Obj_03_BlockCnt 0;
BA_ "PF_Sig_Name" SG_ 851 RDR_Obj_03_BlockCnt "RDR1_Obj_03_BlockZaehler";
BA_ "GenSigSendType" SG_ 851 RDR_Obj_03_dx_v 0;
BA_ "PF_Sig_Name" SG_ 851 RDR_Obj_03_dx_v "RDR1_Obj_03_dx_v";
BA_ "GenSigStartValue" SG_ 851 RDR_Obj_03_dy_v 512;
BA_ "GenSigSendType" SG_ 851 RDR_Obj_03_dy_v 0;
BA_ "PF_Sig_Name" SG_ 851 RDR_Obj_03_dy_v "RDR1_Obj_03_dy_v";
BA_ "GenSigSendType" SG_ 851 RDR_Obj_03_Obj_Obj_ID 0;
BA_ "PF_Sig_Name" SG_ 851 RDR_Obj_03_Obj_Obj_ID "RDR1_Obj_03_Nummer";
BA_ "GenSigStartValue" SG_ 851 RDR_Obj_03_vx_v 512;
BA_ "GenSigSendType" SG_ 851 RDR_Obj_03_vx_v 0;
BA_ "PF_Sig_Name" SG_ 851 RDR_Obj_03_vx_v "RDR1_Obj_03_vx_v";
BA_ "GenSigSendType" SG_ 851 RDR_Obj_03_RFF 0;
BA_ "PF_Sig_Name" SG_ 851 RDR_Obj_03_RFF "RDR1_Obj_03_RFF";
BA_ "GenSigFuncType" SG_ 852 RDR_Obj_04_ChkSum 2;
BA_ "GenSigSendType" SG_ 852 RDR_Obj_04_ChkSum 0;
BA_ "PF_Sig_Name" SG_ 852 RDR_Obj_04_ChkSum "RDR1_Obj_04_CRC";
BA_ "GenSigFuncType" SG_ 852 RDR_Obj_04_MsgCnt 1;
BA_ "GenSigSendType" SG_ 852 RDR_Obj_04_MsgCnt 0;
BA_ "PF_Sig_Name" SG_ 852 RDR_Obj_04_MsgCnt "RDR1_Obj_04_BZ";
BA_ "GenSigSendType" SG_ 852 RDR_Obj_04_BlockCnt 0;
BA_ "PF_Sig_Name" SG_ 852 RDR_Obj_04_BlockCnt "RDR1_Obj_04_BlockZaehler";
BA_ "GenSigSendType" SG_ 852 RDR_Obj_04_dx_v 0;
BA_ "PF_Sig_Name" SG_ 852 RDR_Obj_04_dx_v "RDR1_Obj_04_dx_v";
BA_ "GenSigStartValue" SG_ 852 RDR_Obj_04_dy_v 512;
BA_ "GenSigSendType" SG_ 852 RDR_Obj_04_dy_v 0;
BA_ "PF_Sig_Name" SG_ 852 RDR_Obj_04_dy_v "RDR1_Obj_04_dy_v";
BA_ "GenSigSendType" SG_ 852 RDR_Obj_04_Obj_Obj_ID 0;
BA_ "PF_Sig_Name" SG_ 852 RDR_Obj_04_Obj_Obj_ID "RDR1_Obj_04_Nummer";
BA_ "GenSigStartValue" SG_ 852 RDR_Obj_04_vx_v 512;
BA_ "GenSigSendType" SG_ 852 RDR_Obj_04_vx_v 0;
BA_ "PF_Sig_Name" SG_ 852 RDR_Obj_04_vx_v "RDR1_Obj_04_vx_v";
BA_ "GenSigSendType" SG_ 852 RDR_Obj_04_RFF 0;
BA_ "PF_Sig_Name" SG_ 852 RDR_Obj_04_RFF "RDR1_Obj_04_RFF";
BA_REL_ "GenSigTimeoutTime" BU_SG_REL_ Radar SG_ 1000 VID_Obj_11_A_ChkSum 1000;
BA_REL_ "GenSigTimeoutTime" BU_SG_REL_ Radar SG_ 1000 VID_Obj_11_A_MsgCnt 1000;
BA_REL_ "GenSigTimeoutTime" BU_SG_REL_ Radar SG_ 1000 VID_Obj_11_A_BlockCnt 1000;
BA_REL_ "GenSigTimeoutTime" BU_SG_REL_ Radar SG_ 1000 VID_Obj_11_Dist_longitude 1000;
BA_REL_ "GenSigTimeoutTime" BU_SG_REL_ Radar SG_ 1000 VID_Obj_11_StdD_Dist_longitude 1000;
BA_REL_ "GenSigTimeoutTime" BU_SG_REL_ Radar SG_ 1000 VID_Obj_11_Ang_Center 1000;
BA_REL_ "GenSigTimeoutTime" BU_SG_REL_ Radar SG_ 1000 VID_Obj_11_Stat_Measure 1000;
BA_REL_ "GenSigTimeoutTime" BU_SG_REL_ Radar SG_ 1000 VID_Obj_11_StdD_Ang_Center 1000;
BA_REL_ "GenSigTimeoutTime" BU_SG_REL_ Radar SG_ 1000 VID_Obj_11_Class 1000;
BA_REL_ "GenSigTimeoutTime" BU_SG_REL_ Radar SG_ 1000 VID_Obj_11_RefPoint 1000;
BA_REL_ "GenSigTimeoutTime" BU_SG_REL_ Radar SG_ 1001 VID_Obj_11_B_ChkSum 1000;
BA_REL_ "GenSigTimeoutTime" BU_SG_REL_ Radar SG_ 1001 VID_Obj_11_B_MsgCnt 1000;
BA_REL_ "GenSigTimeoutTime" BU_SG_REL_ Radar SG_ 1001 VID_Obj_11_B_BlockCnt 1000;
BA_REL_ "GenSigTimeoutTime" BU_SG_REL_ Radar SG_ 1001 VID_Obj_11_Ang_Width 1000;
BA_REL_ "GenSigTimeoutTime" BU_SG_REL_ Radar SG_ 1001 VID_Obj_11_ProbExist 1000;
BA_REL_ "GenSigTimeoutTime" BU_SG_REL_ Radar SG_ 1001 VID_Obj_11_StdD_dAng_longitude 1000;
BA_REL_ "GenSigTimeoutTime" BU_SG_REL_ Radar SG_ 1001 VID_Obj_11_dAng_longitude 1000;
BA_REL_ "GenSigTimeoutTime" BU_SG_REL_ Radar SG_ 1001 VID_Obj_11_StdD_Ang_Width 1000;
BA_REL_ "GenSigTimeoutTime" BU_SG_REL_ Radar SG_ 1002 VID_Obj_11_C_ChkSum 1000;
BA_REL_ "GenSigTimeoutTime" BU_SG_REL_ Radar SG_ 1002 VID_Obj_11_C_MsgCnt 1000;
BA_REL_ "GenSigTimeoutTime" BU_SG_REL_ Radar SG_ 1002 VID_Obj_11_C_BlockCnt 1000;
BA_REL_ "GenSigTimeoutTime" BU_SG_REL_ Radar SG_ 1002 VID_Obj_11_InvTTC 1000;
BA_REL_ "GenSigTimeoutTime" BU_SG_REL_ Radar SG_ 1002 VID_Obj_11_StdD_InvTTC 1000;
BA_REL_ "GenSigTimeoutTime" BU_SG_REL_ Radar SG_ 1002 VID_Obj_11_Ang_Overlap_EgoLane_R 1000;
BA_REL_ "GenSigTimeoutTime" BU_SG_REL_ Radar SG_ 1002 VID_Obj_11_Ang_Overlap_EgoLane_L 1000;
BA_REL_ "GenSigTimeoutTime" BU_SG_REL_ Radar SG_ 1002 VID_Obj_11_Obj_Age 1000;
BA_REL_ "GenSigTimeoutTime" BU_SG_REL_ Radar SG_ 1002 VID_Obj_11_BrakeLight 1000;
BA_REL_ "GenSigTimeoutTime" BU_SG_REL_ Radar SG_ 1003 VID_Obj_11_D_ChkSum 1000;
BA_REL_ "GenSigTimeoutTime" BU_SG_REL_ Radar SG_ 1003 VID_Obj_11_D_MsgCnt 1000;
BA_REL_ "GenSigTimeoutTime" BU_SG_REL_ Radar SG_ 1003 VID_Obj_11_D_BlockCnt 1000;
BA_REL_ "GenSigTimeoutTime" BU_SG_REL_ Radar SG_ 1003 VID_Obj_11_Ang_Edge_L 1000;
BA_REL_ "GenSigTimeoutTime" BU_SG_REL_ Radar SG_ 1003 VID_Obj_11_Ang_Edge_R 1000;
BA_REL_ "GenSigTimeoutTime" BU_SG_REL_ Radar SG_ 1003 VID_Obj_11_StdD_Ang_Edge_L 1000;
BA_REL_ "GenSigTimeoutTime" BU_SG_REL_ Radar SG_ 1003 VID_Obj_11_Obj_ID 1000;
BA_REL_ "GenSigTimeoutTime" BU_SG_REL_ Radar SG_ 914 VID_Obj_11_E_ChkSum 1000;
BA_REL_ "GenSigTimeoutTime" BU_SG_REL_ Radar SG_ 914 VID_Obj_11_E_MsgCnt 1000;
BA_REL_ "GenSigTimeoutTime" BU_SG_REL_ Radar SG_ 914 VID_Obj_11_E_BlockCnt 1000;
BA_REL_ "GenSigTimeoutTime" BU_SG_REL_ Radar SG_ 914 VID_Obj_11_Velocity_longitudinal 1000;
BA_REL_ "GenSigTimeoutTime" BU_SG_REL_ Radar SG_ 914 VID_Obj_11_StdD_Velocity_longitu 1000;
BA_REL_ "GenSigTimeoutTime" BU_SG_REL_ Radar SG_ 914 VID_Obj_11_StdD_Ang_Edge_R 1000;
BA_REL_ "GenSigTimeoutTime" BU_SG_REL_ Radar SG_ 914 VID_Obj_11_ScaleChange 1000;
BA_REL_ "GenSigTimeoutTime" BU_SG_REL_ Radar SG_ 1004 VID_Obj_12_A_ChkSum 1000;
BA_REL_ "GenSigTimeoutTime" BU_SG_REL_ Radar SG_ 1004 VID_Obj_12_A_MsgCnt 1000;
BA_REL_ "GenSigTimeoutTime" BU_SG_REL_ Radar SG_ 1004 VID_Obj_12_A_BlockCnt 1000;
BA_REL_ "GenSigTimeoutTime" BU_SG_REL_ Radar SG_ 1004 VID_Obj_12_Dist_longitude 1000;
BA_REL_ "GenSigTimeoutTime" BU_SG_REL_ Radar SG_ 1004 VID_Obj_12_StdD_Dist_longitude 1000;
BA_REL_ "GenSigTimeoutTime" BU_SG_REL_ Radar SG_ 1004 VID_Obj_12_Ang_Center 1000;
BA_REL_ "GenSigTimeoutTime" BU_SG_REL_ Radar SG_ 1004 VID_Obj_12_Stat_Measure 1000;
BA_REL_ "GenSigTimeoutTime" BU_SG_REL_ Radar SG_ 1004 VID_Obj_12_StdD_Ang_Center 1000;
BA_REL_ "GenSigTimeoutTime" BU_SG_REL_ Radar SG_ 1004 VID_Obj_12_Class 1000;
BA_REL_ "GenSigTimeoutTime" BU_SG_REL_ Radar SG_ 1004 VID_Obj_12_RefPoint 1000;
BA_REL_ "GenSigTimeoutTime" BU_SG_REL_ Radar SG_ 1005 VID_Obj_12_B_ChkSum 1000;
BA_REL_ "GenSigTimeoutTime" BU_SG_REL_ Radar SG_ 1005 VID_Obj_12_B_MsgCnt 1000;
BA_REL_ "GenSigTimeoutTime" BU_SG_REL_ Radar SG_ 1005 VID_Obj_12_B_BlockCnt 1000;
BA_REL_ "GenSigTimeoutTime" BU_SG_REL_ Radar SG_ 1005 VID_Obj_12_Ang_Width 1000;
BA_REL_ "GenSigTimeoutTime" BU_SG_REL_ Radar SG_ 1005 VID_Obj_12_ProbExist 1000;
BA_REL_ "GenSigTimeoutTime" BU_SG_REL_ Radar SG_ 1005 VID_Obj_12_StdD_dAng_longitude 1000;
BA_REL_ "GenSigTimeoutTime" BU_SG_REL_ Radar SG_ 1005 VID_Obj_12_dAng_longitude 1000;
BA_REL_ "GenSigTimeoutTime" BU_SG_REL_ Radar SG_ 1005 VID_Obj_12_StdD_Ang_Width 1000;
BA_REL_ "GenSigTimeoutTime" BU_SG_REL_ Radar SG_ 1006 VID_Obj_12_C_ChkSum 1000;
BA_REL_ "GenSigTimeoutTime" BU_SG_REL_ Radar SG_ 1006 VID_Obj_12_C_MsgCnt 1000;
BA_REL_ "GenSigTimeoutTime" BU_SG_REL_ Radar SG_ 1006 VID_Obj_12_C_BlockCnt 1000;
BA_REL_ "GenSigTimeoutTime" BU_SG_REL_ Radar SG_ 1006 VID_Obj_12_InvTTC 1000;
BA_REL_ "GenSigTimeoutTime" BU_SG_REL_ Radar SG_ 1006 VID_Obj_12_StdD_InvTTC 1000;
BA_REL_ "GenSigTimeoutTime" BU_SG_REL_ Radar SG_ 1006 VID_Obj_12_Ang_Overlap_EgoLane_R 1000;
BA_REL_ "GenSigTimeoutTime" BU_SG_REL_ Radar SG_ 1006 VID_Obj_12_Ang_Overlap_EgoLane_L 1000;
BA_REL_ "GenSigTimeoutTime" BU_SG_REL_ Radar SG_ 1006 VID_Obj_12_Obj_Age 1000;
BA_REL_ "GenSigTimeoutTime" BU_SG_REL_ Radar SG_ 1006 VID_Obj_12_BrakeLight 1000;
BA_REL_ "GenSigTimeoutTime" BU_SG_REL_ Radar SG_ 1007 VID_Obj_12_D_ChkSum 1000;
BA_REL_ "GenSigTimeoutTime" BU_SG_REL_ Radar SG_ 1007 VID_Obj_12_D_MsgCnt 1000;
BA_REL_ "GenSigTimeoutTime" BU_SG_REL_ Radar SG_ 1007 VID_Obj_12_D_BlockCnt 1000;
BA_REL_ "GenSigTimeoutTime" BU_SG_REL_ Radar SG_ 1007 VID_Obj_12_Ang_Edge_L 1000;
BA_REL_ "GenSigTimeoutTime" BU_SG_REL_ Radar SG_ 1007 VID_Obj_12_Ang_Edge_R 1000;
BA_REL_ "GenSigTimeoutTime" BU_SG_REL_ Radar SG_ 1007 VID_Obj_12_StdD_Ang_Edge_L 1000;
BA_REL_ "GenSigTimeoutTime" BU_SG_REL_ Radar SG_ 1007 VID_Obj_12_Obj_ID 1000;
BA_REL_ "GenSigTimeoutTime" BU_SG_REL_ Radar SG_ 915 VID_Obj_12_E_ChkSum 1000;
BA_REL_ "GenSigTimeoutTime" BU_SG_REL_ Radar SG_ 915 VID_Obj_12_E_MsgCnt 1000;
BA_REL_ "GenSigTimeoutTime" BU_SG_REL_ Radar SG_ 915 VID_Obj_12_E_BlockCnt 1000;
BA_REL_ "GenSigTimeoutTime" BU_SG_REL_ Radar SG_ 915 VID_Obj_12_Velocity_longitudinal 1000;
BA_REL_ "GenSigTimeoutTime" BU_SG_REL_ Radar SG_ 915 VID_Obj_12_StdD_Velocity_longitu 1000;
BA_REL_ "GenSigTimeoutTime" BU_SG_REL_ Radar SG_ 915 VID_Obj_12_StdD_Ang_Edge_R 1000;
BA_REL_ "GenSigTimeoutTime" BU_SG_REL_ Radar SG_ 915 VID_Obj_12_ScaleChange 1000;
BA_REL_ "GenSigTimeoutTime" BU_SG_REL_ Radar SG_ 1008 VID_Obj_13_A_ChkSum 1000;
BA_REL_ "GenSigTimeoutTime" BU_SG_REL_ Radar SG_ 1008 VID_Obj_13_A_MsgCnt 1000;
BA_REL_ "GenSigTimeoutTime" BU_SG_REL_ Radar SG_ 1008 VID_Obj_13_A_BlockCnt 1000;
BA_REL_ "GenSigTimeoutTime" BU_SG_REL_ Radar SG_ 1008 VID_Obj_13_Dist_longitude 1000;
BA_REL_ "GenSigTimeoutTime" BU_SG_REL_ Radar SG_ 1008 VID_Obj_13_StdD_Dist_longitude 1000;
BA_REL_ "GenSigTimeoutTime" BU_SG_REL_ Radar SG_ 1008 VID_Obj_13_Ang_Center 1000;
BA_REL_ "GenSigTimeoutTime" BU_SG_REL_ Radar SG_ 1008 VID_Obj_13_Stat_Measure 1000;
BA_REL_ "GenSigTimeoutTime" BU_SG_REL_ Radar SG_ 1008 VID_Obj_13_StdD_Ang_Center 1000;
BA_REL_ "GenSigTimeoutTime" BU_SG_REL_ Radar SG_ 1008 VID_Obj_13_Class 1000;
BA_REL_ "GenSigTimeoutTime" BU_SG_REL_ Radar SG_ 1008 VID_Obj_13_RefPoint 1000;
BA_REL_ "GenSigTimeoutTime" BU_SG_REL_ Radar SG_ 1009 VID_Obj_13_B_ChkSum 1000;
BA_REL_ "GenSigTimeoutTime" BU_SG_REL_ Radar SG_ 1009 VID_Obj_13_B_MsgCnt 1000;
BA_REL_ "GenSigTimeoutTime" BU_SG_REL_ Radar SG_ 1009 VID_Obj_13_B_BlockCnt 1000;
BA_REL_ "GenSigTimeoutTime" BU_SG_REL_ Radar SG_ 1009 VID_Obj_13_Ang_Width 1000;
BA_REL_ "GenSigTimeoutTime" BU_SG_REL_ Radar SG_ 1009 VID_Obj_13_ProbExist 1000;
BA_REL_ "GenSigTimeoutTime" BU_SG_REL_ Radar SG_ 1009 VID_Obj_13_StdD_dAng_longitude 1000;
BA_REL_ "GenSigTimeoutTime" BU_SG_REL_ Radar SG_ 1009 VID_Obj_13_dAng_longitude 1000;
BA_REL_ "GenSigTimeoutTime" BU_SG_REL_ Radar SG_ 1009 VID_Obj_13_StdD_Ang_Width 1000;
BA_REL_ "GenSigTimeoutTime" BU_SG_REL_ Radar SG_ 1010 VID_Obj_13_C_ChkSum 1000;
BA_REL_ "GenSigTimeoutTime" BU_SG_REL_ Radar SG_ 1010 VID_Obj_13_C_MsgCnt 1000;
BA_REL_ "GenSigTimeoutTime" BU_SG_REL_ Radar SG_ 1010 VID_Obj_13_C_BlockCnt 1000;
BA_REL_ "GenSigTimeoutTime" BU_SG_REL_ Radar SG_ 1010 VID_Obj_13_InvTTC 1000;
BA_REL_ "GenSigTimeoutTime" BU_SG_REL_ Radar SG_ 1010 VID_Obj_13_StdD_InvTTC 1000;
BA_REL_ "GenSigTimeoutTime" BU_SG_REL_ Radar SG_ 1010 VID_Obj_13_Ang_Overlap_EgoLane_R 1000;
BA_REL_ "GenSigTimeoutTime" BU_SG_REL_ Radar SG_ 1010 VID_Obj_13_Ang_Overlap_EgoLane_L 1000;
BA_REL_ "GenSigTimeoutTime" BU_SG_REL_ Radar SG_ 1010 VID_Obj_13_Obj_Age 1000;
BA_REL_ "GenSigTimeoutTime" BU_SG_REL_ Radar SG_ 1010 VID_Obj_13_BrakeLight 1000;
BA_REL_ "GenSigTimeoutTime" BU_SG_REL_ Radar SG_ 1011 VID_Obj_13_D_ChkSum 1000;
BA_REL_ "GenSigTimeoutTime" BU_SG_REL_ Radar SG_ 1011 VID_Obj_13_D_MsgCnt 1000;
BA_REL_ "GenSigTimeoutTime" BU_SG_REL_ Radar SG_ 1011 VID_Obj_13_D_BlockCnt 1000;
BA_REL_ "GenSigTimeoutTime" BU_SG_REL_ Radar SG_ 1011 VID_Obj_13_Ang_Edge_L 1000;
BA_REL_ "GenSigTimeoutTime" BU_SG_REL_ Radar SG_ 1011 VID_Obj_13_Ang_Edge_R 1000;
BA_REL_ "GenSigTimeoutTime" BU_SG_REL_ Radar SG_ 1011 VID_Obj_13_Obj_ID 1000;
BA_REL_ "GenSigTimeoutTime" BU_SG_REL_ Radar SG_ 916 VID_Obj_13_E_ChkSum 1000;
BA_REL_ "GenSigTimeoutTime" BU_SG_REL_ Radar SG_ 916 VID_Obj_13_E_MsgCnt 1000;
BA_REL_ "GenSigTimeoutTime" BU_SG_REL_ Radar SG_ 916 VID_Obj_13_E_BlockCnt 1000;
BA_REL_ "GenSigTimeoutTime" BU_SG_REL_ Radar SG_ 916 VID_Obj_13_Velocity_longitudinal 1000;
BA_REL_ "GenSigTimeoutTime" BU_SG_REL_ Radar SG_ 916 VID_Obj_13_StdD_Velocity_longitu 1000;
BA_REL_ "GenSigTimeoutTime" BU_SG_REL_ Radar SG_ 916 VID_Obj_13_StdD_Ang_Edge_R 1000;
BA_REL_ "GenSigTimeoutTime" BU_SG_REL_ Radar SG_ 916 VID_Obj_13_ScaleChange 1000;
BA_REL_ "GenSigTimeoutTime" BU_SG_REL_ Radar SG_ 1012 VID_Obj_14_A_ChkSum 1000;
BA_REL_ "GenSigTimeoutTime" BU_SG_REL_ Radar SG_ 1012 VID_Obj_14_A_MsgCnt 1000;
BA_REL_ "GenSigTimeoutTime" BU_SG_REL_ Radar SG_ 1012 VID_Obj_14_A_BlockCnt 1000;
BA_REL_ "GenSigTimeoutTime" BU_SG_REL_ Radar SG_ 1012 VID_Obj_14_Dist_longitude 1000;
BA_REL_ "GenSigTimeoutTime" BU_SG_REL_ Radar SG_ 1012 VID_Obj_14_StdD_Dist_longitude 1000;
BA_REL_ "GenSigTimeoutTime" BU_SG_REL_ Radar SG_ 1012 VID_Obj_14_Ang_Center 1000;
BA_REL_ "GenSigTimeoutTime" BU_SG_REL_ Radar SG_ 1012 VID_Obj_14_Stat_Measure 1000;
BA_REL_ "GenSigTimeoutTime" BU_SG_REL_ Radar SG_ 1012 VID_Obj_14_StdD_Ang_Center 1000;
BA_REL_ "GenSigTimeoutTime" BU_SG_REL_ Radar SG_ 1012 VID_Obj_14_Class 1000;
BA_REL_ "GenSigTimeoutTime" BU_SG_REL_ Radar SG_ 1012 VID_Obj_14_RefPoint 1000;
BA_REL_ "GenSigTimeoutTime" BU_SG_REL_ Radar SG_ 1013 VID_Obj_14_B_ChkSum 1000;
BA_REL_ "GenSigTimeoutTime" BU_SG_REL_ Radar SG_ 1013 VID_Obj_14_B_MsgCnt 1000;
BA_REL_ "GenSigTimeoutTime" BU_SG_REL_ Radar SG_ 1013 VID_Obj_14_B_BlockCnt 1000;
BA_REL_ "GenSigTimeoutTime" BU_SG_REL_ Radar SG_ 1013 VID_Obj_14_Ang_Width 1000;
BA_REL_ "GenSigTimeoutTime" BU_SG_REL_ Radar SG_ 1013 VID_Obj_14_ProbExist 1000;
BA_REL_ "GenSigTimeoutTime" BU_SG_REL_ Radar SG_ 1013 VID_Obj_14_StdD_dAng_longitude 1000;
BA_REL_ "GenSigTimeoutTime" BU_SG_REL_ Radar SG_ 1013 VID_Obj_14_dAng_longitude 1000;
BA_REL_ "GenSigTimeoutTime" BU_SG_REL_ Radar SG_ 1013 VID_Obj_14_StdD_Ang_Width 1000;
BA_REL_ "GenSigTimeoutTime" BU_SG_REL_ Radar SG_ 1014 VID_Obj_14_C_ChkSum 1000;
BA_REL_ "GenSigTimeoutTime" BU_SG_REL_ Radar SG_ 1014 VID_Obj_14_C_MsgCnt 1000;
BA_REL_ "GenSigTimeoutTime" BU_SG_REL_ Radar SG_ 1014 VID_Obj_14_C_BlockCnt 1000;
BA_REL_ "GenSigTimeoutTime" BU_SG_REL_ Radar SG_ 1014 VID_Obj_14_InvTTC 1000;
BA_REL_ "GenSigTimeoutTime" BU_SG_REL_ Radar SG_ 1014 VID_Obj_14_StdD_InvTTC 1000;
BA_REL_ "GenSigTimeoutTime" BU_SG_REL_ Radar SG_ 1014 VID_Obj_14_Ang_Overlap_EgoLane_R 1000;
BA_REL_ "GenSigTimeoutTime" BU_SG_REL_ Radar SG_ 1014 VID_Obj_14_Ang_Overlap_EgoLane_L 1000;
BA_REL_ "GenSigTimeoutTime" BU_SG_REL_ Radar SG_ 1014 VID_Obj_14_Obj_Age 1000;
BA_REL_ "GenSigTimeoutTime" BU_SG_REL_ Radar SG_ 1014 VID_Obj_14_BrakeLight 1000;
BA_REL_ "GenSigTimeoutTime" BU_SG_REL_ Radar SG_ 1015 VID_Obj_14_D_ChkSum 1000;
BA_REL_ "GenSigTimeoutTime" BU_SG_REL_ Radar SG_ 1015 VID_Obj_14_D_MsgCnt 1000;
BA_REL_ "GenSigTimeoutTime" BU_SG_REL_ Radar SG_ 1015 VID_Obj_14_D_BlockCnt 1000;
BA_REL_ "GenSigTimeoutTime" BU_SG_REL_ Radar SG_ 1015 VID_Obj_14_Ang_Edge_L 1000;
BA_REL_ "GenSigTimeoutTime" BU_SG_REL_ Radar SG_ 1015 VID_Obj_14_Ang_Edge_R 1000;
BA_REL_ "GenSigTimeoutTime" BU_SG_REL_ Radar SG_ 1015 VID_Obj_14_StdD_Ang_Edge_L 1000;
BA_REL_ "GenSigTimeoutTime" BU_SG_REL_ Radar SG_ 1015 VID_Obj_14_Obj_ID 1000;
BA_REL_ "GenSigTimeoutTime" BU_SG_REL_ Radar SG_ 917 VID_Obj_14_E_ChkSum 1000;
BA_REL_ "GenSigTimeoutTime" BU_SG_REL_ Radar SG_ 917 VID_Obj_14_E_MsgCnt 1000;
BA_REL_ "GenSigTimeoutTime" BU_SG_REL_ Radar SG_ 917 VID_Obj_14_E_BlockCnt 1000;
BA_REL_ "GenSigTimeoutTime" BU_SG_REL_ Radar SG_ 917 VID_Obj_14_Velocity_longitudinal 1000;
BA_REL_ "GenSigTimeoutTime" BU_SG_REL_ Radar SG_ 917 VID_Obj_14_StdD_Velocity_longitu 1000;
BA_REL_ "GenSigTimeoutTime" BU_SG_REL_ Radar SG_ 917 VID_Obj_14_StdD_Ang_Edge_R 1000;
BA_REL_ "GenSigTimeoutTime" BU_SG_REL_ Radar SG_ 917 VID_Obj_14_ScaleChange 1000;
BA_REL_ "GenSigTimeoutTime" BU_SG_REL_ Radar SG_ 1016 VID_Obj_15_A_ChkSum 1000;
BA_REL_ "GenSigTimeoutTime" BU_SG_REL_ Radar SG_ 1016 VID_Obj_15_A_MsgCnt 1000;
BA_REL_ "GenSigTimeoutTime" BU_SG_REL_ Radar SG_ 1016 VID_Obj_15_A_BlockCnt 1000;
BA_REL_ "GenSigTimeoutTime" BU_SG_REL_ Radar SG_ 1016 VID_Obj_15_Dist_longitude 1000;
BA_REL_ "GenSigTimeoutTime" BU_SG_REL_ Radar SG_ 1016 VID_Obj_15_StdD_Dist_longitude 1000;
BA_REL_ "GenSigTimeoutTime" BU_SG_REL_ Radar SG_ 1016 VID_Obj_15_Ang_Center 1000;
BA_REL_ "GenSigTimeoutTime" BU_SG_REL_ Radar SG_ 1016 VID_Obj_15_Stat_Measure 1000;
BA_REL_ "GenSigTimeoutTime" BU_SG_REL_ Radar SG_ 1016 VID_Obj_15_StdD_Ang_Center 1000;
BA_REL_ "GenSigTimeoutTime" BU_SG_REL_ Radar SG_ 1016 VID_Obj_15_Class 1000;
BA_REL_ "GenSigTimeoutTime" BU_SG_REL_ Radar SG_ 1016 VID_Obj_15_RefPoint 1000;
BA_REL_ "GenSigTimeoutTime" BU_SG_REL_ Radar SG_ 1017 VID_Obj_15_B_ChkSum 1000;
BA_REL_ "GenSigTimeoutTime" BU_SG_REL_ Radar SG_ 1017 VID_Obj_15_B_MsgCnt 1000;
BA_REL_ "GenSigTimeoutTime" BU_SG_REL_ Radar SG_ 1017 VID_Obj_15_B_BlockCnt 1000;
BA_REL_ "GenSigTimeoutTime" BU_SG_REL_ Radar SG_ 1017 VID_Obj_15_Ang_Width 1000;
BA_REL_ "GenSigTimeoutTime" BU_SG_REL_ Radar SG_ 1017 VID_Obj_15_ProbExist 1000;
BA_REL_ "GenSigTimeoutTime" BU_SG_REL_ Radar SG_ 1017 VID_Obj_15_StdD_dAng_longitude 1000;
BA_REL_ "GenSigTimeoutTime" BU_SG_REL_ Radar SG_ 1017 VID_Obj_15_dAng_longitude 1000;
BA_REL_ "GenSigTimeoutTime" BU_SG_REL_ Radar SG_ 1017 VID_Obj_15_StdD_Ang_Width 1000;
BA_REL_ "GenSigTimeoutTime" BU_SG_REL_ Radar SG_ 1018 VID_Obj_15_C_ChkSum 1000;
BA_REL_ "GenSigTimeoutTime" BU_SG_REL_ Radar SG_ 1018 VID_Obj_15_C_MsgCnt 1000;
BA_REL_ "GenSigTimeoutTime" BU_SG_REL_ Radar SG_ 1018 VID_Obj_15_C_BlockCnt 1000;
BA_REL_ "GenSigTimeoutTime" BU_SG_REL_ Radar SG_ 1018 VID_Obj_15_InvTTC 1000;
BA_REL_ "GenSigTimeoutTime" BU_SG_REL_ Radar SG_ 1018 VID_Obj_15_StdD_InvTTC 1000;
BA_REL_ "GenSigTimeoutTime" BU_SG_REL_ Radar SG_ 1018 VID_Obj_15_Ang_Overlap_EgoLane_R 1000;
BA_REL_ "GenSigTimeoutTime" BU_SG_REL_ Radar SG_ 1018 VID_Obj_15_Ang_Overlap_EgoLane_L 1000;
BA_REL_ "GenSigTimeoutTime" BU_SG_REL_ Radar SG_ 1018 VID_Obj_15_Obj_Age 1000;
BA_REL_ "GenSigTimeoutTime" BU_SG_REL_ Radar SG_ 1018 VID_Obj_15_BrakeLight 1000;
BA_REL_ "GenSigTimeoutTime" BU_SG_REL_ Radar SG_ 1019 VID_Obj_15_D_ChkSum 1000;
BA_REL_ "GenSigTimeoutTime" BU_SG_REL_ Radar SG_ 1019 VID_Obj_15_D_MsgCnt 1000;
BA_REL_ "GenSigTimeoutTime" BU_SG_REL_ Radar SG_ 1019 VID_Obj_15_D_BlockCnt 1000;
BA_REL_ "GenSigTimeoutTime" BU_SG_REL_ Radar SG_ 1019 VID_Obj_15_Ang_Edge_L 1000;
BA_REL_ "GenSigTimeoutTime" BU_SG_REL_ Radar SG_ 1019 VID_Obj_15_Ang_Edge_R 1000;
BA_REL_ "GenSigTimeoutTime" BU_SG_REL_ Radar SG_ 1019 VID_Obj_15_StdD_Ang_Edge_L 1000;
BA_REL_ "GenSigTimeoutTime" BU_SG_REL_ Radar SG_ 1019 VID_Obj_15_Obj_ID 1000;
BA_REL_ "GenSigTimeoutTime" BU_SG_REL_ Radar SG_ 918 VID_Obj_15_E_ChkSum 1000;
BA_REL_ "GenSigTimeoutTime" BU_SG_REL_ Radar SG_ 918 VID_Obj_15_E_MsgCnt 1000;
BA_REL_ "GenSigTimeoutTime" BU_SG_REL_ Radar SG_ 918 VID_Obj_15_E_BlockCnt 1000;
BA_REL_ "GenSigTimeoutTime" BU_SG_REL_ Radar SG_ 918 VID_Obj_15_Velocity_longitudinal 1000;
BA_REL_ "GenSigTimeoutTime" BU_SG_REL_ Radar SG_ 918 VID_Obj_15_StdD_Velocity_longitu 1000;
BA_REL_ "GenSigTimeoutTime" BU_SG_REL_ Radar SG_ 918 VID_Obj_15_StdD_Ang_Edge_R 1000;
BA_REL_ "GenSigTimeoutTime" BU_SG_REL_ Radar SG_ 918 VID_Obj_15_ScaleChange 1000;
BA_REL_ "GenSigTimeoutTime" BU_SG_REL_ Radar SG_ 1020 VID_Obj_16_A_ChkSum 1000;
BA_REL_ "GenSigTimeoutTime" BU_SG_REL_ Radar SG_ 1020 VID_Obj_16_A_MsgCnt 1000;
BA_REL_ "GenSigTimeoutTime" BU_SG_REL_ Radar SG_ 1020 VID_Obj_16_A_BlockCnt 1000;
BA_REL_ "GenSigTimeoutTime" BU_SG_REL_ Radar SG_ 1020 VID_Obj_16_Dist_longitude 1000;
BA_REL_ "GenSigTimeoutTime" BU_SG_REL_ Radar SG_ 1020 VID_Obj_16_StdD_Dist_longitude 1000;
BA_REL_ "GenSigTimeoutTime" BU_SG_REL_ Radar SG_ 1020 VID_Obj_16_Ang_Center 1000;
BA_REL_ "GenSigTimeoutTime" BU_SG_REL_ Radar SG_ 1020 VID_Obj_16_Stat_Measure 1000;
BA_REL_ "GenSigTimeoutTime" BU_SG_REL_ Radar SG_ 1020 VID_Obj_16_StdD_Ang_Center 1000;
BA_REL_ "GenSigTimeoutTime" BU_SG_REL_ Radar SG_ 1020 VID_Obj_16_Class 1000;
BA_REL_ "GenSigTimeoutTime" BU_SG_REL_ Radar SG_ 1020 VID_Obj_16_RefPoint 1000;
BA_REL_ "GenSigTimeoutTime" BU_SG_REL_ Radar SG_ 1021 VID_Obj_16_B_ChkSum 1000;
BA_REL_ "GenSigTimeoutTime" BU_SG_REL_ Radar SG_ 1021 VID_Obj_16_B_MsgCnt 1000;
BA_REL_ "GenSigTimeoutTime" BU_SG_REL_ Radar SG_ 1021 VID_Obj_16_B_BlockCnt 1000;
BA_REL_ "GenSigTimeoutTime" BU_SG_REL_ Radar SG_ 1021 VID_Obj_16_Ang_Width 1000;
BA_REL_ "GenSigTimeoutTime" BU_SG_REL_ Radar SG_ 1021 VID_Obj_16_ProbExist 1000;
BA_REL_ "GenSigTimeoutTime" BU_SG_REL_ Radar SG_ 1021 VID_Obj_16_StdD_dAng_longitude 1000;
BA_REL_ "GenSigTimeoutTime" BU_SG_REL_ Radar SG_ 1021 VID_Obj_16_dAng_longitude 1000;
BA_REL_ "GenSigTimeoutTime" BU_SG_REL_ Radar SG_ 1021 VID_Obj_16_StdD_Ang_Width 1000;
BA_REL_ "GenSigTimeoutTime" BU_SG_REL_ Radar SG_ 1022 VID_Obj_16_C_ChkSum 1000;
BA_REL_ "GenSigTimeoutTime" BU_SG_REL_ Radar SG_ 1022 VID_Obj_16_C_MsgCnt 1000;
BA_REL_ "GenSigTimeoutTime" BU_SG_REL_ Radar SG_ 1022 VID_Obj_16_C_BlockCnt 1000;
BA_REL_ "GenSigTimeoutTime" BU_SG_REL_ Radar SG_ 1022 VID_Obj_16_InvTTC 1000;
BA_REL_ "GenSigTimeoutTime" BU_SG_REL_ Radar SG_ 1022 VID_Obj_16_StdD_InvTTC 1000;
BA_REL_ "GenSigTimeoutTime" BU_SG_REL_ Radar SG_ 1022 VID_Obj_16_Ang_Overlap_EgoLane_R 1000;
BA_REL_ "GenSigTimeoutTime" BU_SG_REL_ Radar SG_ 1022 VID_Obj_16_Ang_Overlap_EgoLane_L 1000;
BA_REL_ "GenSigTimeoutTime" BU_SG_REL_ Radar SG_ 1022 VID_Obj_16_Obj_Age 1000;
BA_REL_ "GenSigTimeoutTime" BU_SG_REL_ Radar SG_ 1022 VID_Obj_16_BrakeLight 1000;
BA_REL_ "GenSigTimeoutTime" BU_SG_REL_ Radar SG_ 1023 VID_Obj_16_D_ChkSum 1000;
BA_REL_ "GenSigTimeoutTime" BU_SG_REL_ Radar SG_ 1023 VID_Obj_16_D_MsgCnt 1000;
BA_REL_ "GenSigTimeoutTime" BU_SG_REL_ Radar SG_ 1023 VID_Obj_16_D_BlockCnt 1000;
BA_REL_ "GenSigTimeoutTime" BU_SG_REL_ Radar SG_ 1023 VID_Obj_16_Ang_Edge_L 1000;
BA_REL_ "GenSigTimeoutTime" BU_SG_REL_ Radar SG_ 1023 VID_Obj_16_Ang_Edge_R 1000;
BA_REL_ "GenSigTimeoutTime" BU_SG_REL_ Radar SG_ 1023 VID_Obj_16_StdD_Ang_Edge_L 1000;
BA_REL_ "GenSigTimeoutTime" BU_SG_REL_ Radar SG_ 1023 VID_Obj_16_Obj_ID 1000;
BA_REL_ "GenSigTimeoutTime" BU_SG_REL_ Radar SG_ 919 VID_Obj_16_E_ChkSum 1000;
BA_REL_ "GenSigTimeoutTime" BU_SG_REL_ Radar SG_ 919 VID_Obj_16_E_MsgCnt 1000;
BA_REL_ "GenSigTimeoutTime" BU_SG_REL_ Radar SG_ 919 VID_Obj_16_E_BlockCnt 1000;
BA_REL_ "GenSigTimeoutTime" BU_SG_REL_ Radar SG_ 919 VID_Obj_16_Velocity_longitudinal 1000;
BA_REL_ "GenSigTimeoutTime" BU_SG_REL_ Radar SG_ 919 VID_Obj_16_StdD_Velocity_longitu 1000;
BA_REL_ "GenSigTimeoutTime" BU_SG_REL_ Radar SG_ 919 VID_Obj_16_StdD_Ang_Edge_R 1000;
BA_REL_ "GenSigTimeoutTime" BU_SG_REL_ Radar SG_ 919 VID_Obj_16_ScaleChange 1000;
BA_REL_ "GenSigTimeoutTime" BU_SG_REL_ MPC2 SG_ 848 RDR_Stat_PED_Brake 500;
BA_REL_ "GenSigTimeoutTime" BU_SG_REL_ MPC2 SG_ 849 RDR_Obj_01_dx_v 500;
BA_REL_ "GenSigTimeoutTime" BU_SG_REL_ MPC2 SG_ 849 RDR_Obj_01_dy_v 500;
BA_REL_ "GenSigTimeoutTime" BU_SG_REL_ MPC2 SG_ 849 RDR_Obj_01_RFF 500;
BA_REL_ "GenSigTimeoutTime" BU_SG_REL_ MPC2 SG_ 850 RDR_Obj_02_RFF 500;
BA_REL_ "GenSigTimeoutTime" BU_SG_REL_ MPC2 SG_ 851 RDR_Obj_03_RFF 500;
BA_REL_ "GenSigTimeoutTime" BU_SG_REL_ MPC2 SG_ 852 RDR_Obj_04_RFF 500;
VAL_ 1000 VID_Obj_11_Dist_longitude 4095 "init" ;
VAL_ 1000 VID_Obj_11_StdD_Dist_longitude 127 "init" ;
VAL_ 1000 VID_Obj_11_Ang_Center 2047 "init" ;
VAL_ 1000 VID_Obj_11_Stat_Measure 0 "obj_predicted" 1 "obj_measured" 2 "obj_featuretracked" 3 "NR_intruder_or_overtakeing" ;
VAL_ 1000 VID_Obj_11_StdD_Ang_Center 255 "init" ;
VAL_ 1000 VID_Obj_11_Class 0 "unknown" 1 "overrideable" 2 "underridable" 3 "pedestrian" 4 "pedestrian_multiple" 5 "bicycle" 6 "motorcycle" 7 "passengercar" 8 "van" 9 "heavy_truck" 10 "stationary" 11 "animal" 12 "retroreflector" 15 "init" ;
VAL_ 1000 VID_Obj_11_RefPoint 0 "unclassified" 1 "front_left" 2 "front_center" 3 "front_right" 4 "right_side_center" 5 "rear_right" 6 "rear_center" 7 "rear_left" 8 "left_side_center" 9 "center" 15 "init" ;
VAL_ 1001 VID_Obj_11_Ang_Width 2047 "init" ;
VAL_ 1001 VID_Obj_11_ProbExist 127 "init" ;
VAL_ 1001 VID_Obj_11_StdD_dAng_longitude 63 "init" ;
VAL_ 1001 VID_Obj_11_dAng_longitude 511 "init" ;
VAL_ 1001 VID_Obj_11_StdD_Ang_Width 255 "init" ;
VAL_ 1002 VID_Obj_11_InvTTC 1023 "init" ;
VAL_ 1002 VID_Obj_11_StdD_InvTTC 127 "init" ;
VAL_ 1002 VID_Obj_11_Ang_Overlap_EgoLane_R 511 "init" ;
VAL_ 1002 VID_Obj_11_Ang_Overlap_EgoLane_L 511 "init" ;
VAL_ 1002 VID_Obj_11_Obj_Age 4095 "init" ;
VAL_ 1002 VID_Obj_11_BrakeLight 0 "no_brakelight_detected" 1 "brakelight_detected" ;
VAL_ 1003 VID_Obj_11_Obj_ID 0 "no_valid_object" 255 "init" ;
VAL_ 914 VID_Obj_11_Velocity_longitudinal 2046 "init" ;
VAL_ 914 VID_Obj_11_StdD_Velocity_longitu 1022 "init" ;
VAL_ 914 VID_Obj_11_ScaleChange 1023 "undefined" ;
VAL_ 1004 VID_Obj_12_Dist_longitude 4095 "init" ;
VAL_ 1004 VID_Obj_12_StdD_Dist_longitude 127 "init" ;
VAL_ 1004 VID_Obj_12_Ang_Center 2047 "init" ;
VAL_ 1004 VID_Obj_12_Stat_Measure 0 "obj_predicted" 1 "obj_measured" 2 "obj_featuretracked" 3 "NR_intruder_or_overtakeing" ;
VAL_ 1004 VID_Obj_12_StdD_Ang_Center 255 "init" ;
VAL_ 1004 VID_Obj_12_Class 0 "unknown" 1 "overrideable" 2 "underridable" 3 "pedestrian" 4 "pedestrian_multiple" 5 "bicycle" 6 "motorcycle" 7 "passengercar" 8 "van" 9 "heavy_truck" 10 "stationary" 11 "animal" 12 "retroreflector" 15 "init" ;
VAL_ 1004 VID_Obj_12_RefPoint 0 "unclassified" 1 "front_left" 2 "front_center" 3 "front_right" 4 "right_side_center" 5 "rear_right" 6 "rear_center" 7 "rear_left" 8 "left_side_center" 9 "center" 15 "init" ;
VAL_ 1005 VID_Obj_12_Ang_Width 2047 "init" ;
VAL_ 1005 VID_Obj_12_ProbExist 127 "init" ;
VAL_ 1005 VID_Obj_12_StdD_dAng_longitude 63 "init" ;
VAL_ 1005 VID_Obj_12_dAng_longitude 511 "init" ;
VAL_ 1005 VID_Obj_12_StdD_Ang_Width 255 "init" ;
VAL_ 1006 VID_Obj_12_InvTTC 1023 "init" ;
VAL_ 1006 VID_Obj_12_StdD_InvTTC 127 "init" ;
VAL_ 1006 VID_Obj_12_Ang_Overlap_EgoLane_R 511 "init" ;
VAL_ 1006 VID_Obj_12_Ang_Overlap_EgoLane_L 511 "init" ;
VAL_ 1006 VID_Obj_12_Obj_Age 4095 "init" ;
VAL_ 1006 VID_Obj_12_BrakeLight 0 "no_brakelight_detected" 1 "brakelight_detected" ;
VAL_ 1007 VID_Obj_12_Obj_ID 0 "no_valid_object" 255 "init" ;
VAL_ 915 VID_Obj_12_Velocity_longitudinal 2046 "init" ;
VAL_ 915 VID_Obj_12_StdD_Velocity_longitu 1022 "init" ;
VAL_ 915 VID_Obj_12_ScaleChange 1023 "undefined" ;
VAL_ 1008 VID_Obj_13_Dist_longitude 4095 "init" ;
VAL_ 1008 VID_Obj_13_StdD_Dist_longitude 127 "init" ;
VAL_ 1008 VID_Obj_13_Ang_Center 2047 "init" ;
VAL_ 1008 VID_Obj_13_Stat_Measure 0 "obj_predicted" 1 "obj_measured" 2 "obj_featuretracked" 3 "NR_intruder_or_overtakeing" ;
VAL_ 1008 VID_Obj_13_StdD_Ang_Center 255 "init" ;
VAL_ 1008 VID_Obj_13_Class 0 "unknown" 1 "overrideable" 2 "underridable" 3 "pedestrian" 4 "pedestrian_multiple" 5 "bicycle" 6 "motorcycle" 7 "passengercar" 8 "van" 9 "heavy_truck" 10 "stationary" 11 "animal" 12 "retroreflector" 15 "init" ;
VAL_ 1008 VID_Obj_13_RefPoint 0 "unclassified" 1 "front_left" 2 "front_center" 3 "front_right" 4 "right_side_center" 5 "rear_right" 6 "rear_center" 7 "rear_left" 8 "left_side_center" 9 "center" 15 "init" ;
VAL_ 1009 VID_Obj_13_Ang_Width 2047 "init" ;
VAL_ 1009 VID_Obj_13_ProbExist 127 "init" ;
VAL_ 1009 VID_Obj_13_StdD_dAng_longitude 63 "init" ;
VAL_ 1009 VID_Obj_13_dAng_longitude 511 "init" ;
VAL_ 1009 VID_Obj_13_StdD_Ang_Width 255 "init" ;
VAL_ 1010 VID_Obj_13_InvTTC 1023 "init" ;
VAL_ 1010 VID_Obj_13_StdD_InvTTC 127 "init" ;
VAL_ 1010 VID_Obj_13_Ang_Overlap_EgoLane_R 511 "init" ;
VAL_ 1010 VID_Obj_13_Ang_Overlap_EgoLane_L 511 "init" ;
VAL_ 1010 VID_Obj_13_Obj_Age 4095 "init" ;
VAL_ 1010 VID_Obj_13_BrakeLight 0 "no_brakelight_detected" 1 "brakelight_detected" ;
VAL_ 1011 VID_Obj_13_Obj_ID 0 "no_valid_object" 255 "init" ;
VAL_ 916 VID_Obj_13_Velocity_longitudinal 2046 "init" ;
VAL_ 916 VID_Obj_13_StdD_Velocity_longitu 1022 "init" ;
VAL_ 916 VID_Obj_13_ScaleChange 1023 "undefined" ;
VAL_ 1012 VID_Obj_14_Dist_longitude 4095 "init" ;
VAL_ 1012 VID_Obj_14_StdD_Dist_longitude 127 "init" ;
VAL_ 1012 VID_Obj_14_Ang_Center 2047 "init" ;
VAL_ 1012 VID_Obj_14_Stat_Measure 0 "obj_predicted" 1 "obj_measured" 2 "obj_featuretracked" 3 "NR_intruder_or_overtakeing" ;
VAL_ 1012 VID_Obj_14_StdD_Ang_Center 255 "init" ;
VAL_ 1012 VID_Obj_14_Class 0 "unknown" 1 "overrideable" 2 "underridable" 3 "pedestrian" 4 "pedestrian_multiple" 5 "bicycle" 6 "motorcycle" 7 "passengercar" 8 "van" 9 "heavy_truck" 10 "stationary" 11 "animal" 12 "retroreflector" 15 "init" ;
VAL_ 1012 VID_Obj_14_RefPoint 0 "unclassified" 1 "front_left" 2 "front_center" 3 "front_right" 4 "right_side_center" 5 "rear_right" 6 "rear_center" 7 "rear_left" 8 "left_side_center" 9 "center" 15 "init" ;
VAL_ 1013 VID_Obj_14_Ang_Width 2047 "init" ;
VAL_ 1013 VID_Obj_14_ProbExist 127 "init" ;
VAL_ 1013 VID_Obj_14_StdD_dAng_longitude 63 "init" ;
VAL_ 1013 VID_Obj_14_dAng_longitude 511 "init" ;
VAL_ 1013 VID_Obj_14_StdD_Ang_Width 255 "init" ;
VAL_ 1014 VID_Obj_14_InvTTC 1023 "init" ;
VAL_ 1014 VID_Obj_14_StdD_InvTTC 127 "init" ;
VAL_ 1014 VID_Obj_14_Ang_Overlap_EgoLane_R 511 "init" ;
VAL_ 1014 VID_Obj_14_Ang_Overlap_EgoLane_L 511 "init" ;
VAL_ 1014 VID_Obj_14_Obj_Age 4095 "init" ;
VAL_ 1014 VID_Obj_14_BrakeLight 0 "no_brakelight_detected" 1 "brakelight_detected" ;
VAL_ 1015 VID_Obj_14_Obj_ID 0 "no_valid_object" 255 "init" ;
VAL_ 917 VID_Obj_14_Velocity_longitudinal 2046 "init" ;
VAL_ 917 VID_Obj_14_StdD_Velocity_longitu 1022 "init" ;
VAL_ 917 VID_Obj_14_ScaleChange 1023 "undefined" ;
VAL_ 1016 VID_Obj_15_Dist_longitude 4095 "init" ;
VAL_ 1016 VID_Obj_15_StdD_Dist_longitude 127 "init" ;
VAL_ 1016 VID_Obj_15_Ang_Center 2047 "init" ;
VAL_ 1016 VID_Obj_15_Stat_Measure 0 "obj_predicted" 1 "obj_measured" 2 "obj_featuretracked" 3 "NR_intruder_or_overtakeing" ;
VAL_ 1016 VID_Obj_15_StdD_Ang_Center 255 "init" ;
VAL_ 1016 VID_Obj_15_Class 0 "unknown" 1 "overrideable" 2 "underridable" 3 "pedestrian" 4 "pedestrian_multiple" 5 "bicycle" 6 "motorcycle" 7 "passengercar" 8 "van" 9 "heavy_truck" 10 "stationary" 11 "animal" 12 "retroreflector" 15 "init" ;
VAL_ 1016 VID_Obj_15_RefPoint 0 "unclassified" 1 "front_left" 2 "front_center" 3 "front_right" 4 "right_side_center" 5 "rear_right" 6 "rear_center" 7 "rear_left" 8 "left_side_center" 9 "center" 15 "init" ;
VAL_ 1017 VID_Obj_15_Ang_Width 2047 "init" ;
VAL_ 1017 VID_Obj_15_ProbExist 127 "init" ;
VAL_ 1017 VID_Obj_15_StdD_dAng_longitude 63 "init" ;
VAL_ 1017 VID_Obj_15_dAng_longitude 511 "init" ;
VAL_ 1017 VID_Obj_15_StdD_Ang_Width 255 "init" ;
VAL_ 1018 VID_Obj_15_InvTTC 1023 "init" ;
VAL_ 1018 VID_Obj_15_StdD_InvTTC 127 "init" ;
VAL_ 1018 VID_Obj_15_Ang_Overlap_EgoLane_R 511 "init" ;
VAL_ 1018 VID_Obj_15_Ang_Overlap_EgoLane_L 511 "init" ;
VAL_ 1018 VID_Obj_15_Obj_Age 4095 "init" ;
VAL_ 1018 VID_Obj_15_BrakeLight 0 "no_brakelight_detected" 1 "brakelight_detected" ;
VAL_ 1019 VID_Obj_15_Obj_ID 0 "no_valid_object" 255 "init" ;
VAL_ 918 VID_Obj_15_Velocity_longitudinal 2046 "init" ;
VAL_ 918 VID_Obj_15_StdD_Velocity_longitu 1022 "init" ;
VAL_ 918 VID_Obj_15_ScaleChange 1023 "undefined" ;
VAL_ 1020 VID_Obj_16_Dist_longitude 4095 "init" ;
VAL_ 1020 VID_Obj_16_StdD_Dist_longitude 127 "init" ;
VAL_ 1020 VID_Obj_16_Ang_Center 2047 "init" ;
VAL_ 1020 VID_Obj_16_Stat_Measure 0 "obj_predicted" 1 "obj_measured" 2 "obj_featuretracked" 3 "NR_intruder_or_overtakeing" ;
VAL_ 1020 VID_Obj_16_StdD_Ang_Center 255 "init" ;
VAL_ 1020 VID_Obj_16_Class 0 "unknown" 1 "overrideable" 2 "underridable" 3 "pedestrian" 4 "pedestrian_multiple" 5 "bicycle" 6 "motorcycle" 7 "passengercar" 8 "van" 9 "heavy_truck" 10 "stationary" 11 "animal" 12 "retroreflector" 15 "init" ;
VAL_ 1020 VID_Obj_16_RefPoint 0 "unclassified" 1 "front_left" 2 "front_center" 3 "front_right" 4 "right_side_center" 5 "rear_right" 6 "rear_center" 7 "rear_left" 8 "left_side_center" 9 "center" 15 "init" ;
VAL_ 1021 VID_Obj_16_Ang_Width 2047 "init" ;
VAL_ 1021 VID_Obj_16_ProbExist 127 "init" ;
VAL_ 1021 VID_Obj_16_StdD_dAng_longitude 63 "init" ;
VAL_ 1021 VID_Obj_16_dAng_longitude 511 "init" ;
VAL_ 1021 VID_Obj_16_StdD_Ang_Width 255 "init" ;
VAL_ 1022 VID_Obj_16_InvTTC 1023 "init" ;
VAL_ 1022 VID_Obj_16_StdD_InvTTC 127 "init" ;
VAL_ 1022 VID_Obj_16_Ang_Overlap_EgoLane_R 511 "init" ;
VAL_ 1022 VID_Obj_16_Ang_Overlap_EgoLane_L 511 "init" ;
VAL_ 1022 VID_Obj_16_Obj_Age 4095 "init" ;
VAL_ 1022 VID_Obj_16_BrakeLight 0 "no_brakelight_detected" 1 "brakelight_detected" ;
VAL_ 1023 VID_Obj_16_Obj_ID 0 "no_valid_object" 255 "init" ;
VAL_ 919 VID_Obj_16_Velocity_longitudinal 2046 "init" ;
VAL_ 919 VID_Obj_16_StdD_Velocity_longitu 1022 "init" ;
VAL_ 919 VID_Obj_16_ScaleChange 1023 "undefined" ;
VAL_ 848 RDR_Stat_HostPedestrianStatus 0 "Not_Detect" 1 "detected" 2 "reserved" 3 "reserved" ;
VAL_ 848 RDR_Stat_ACCSwitchButton 0 "Not_Pressed" 1 "Pressed" 2 "Dummy" 3 "Error" ;
VAL_ 848 RDR_Stat_ObjDataAge 1023 "data_expired" ;
VAL_ 848 RDR_Stat_PED_Brake 0 "on" 1 "off" 2 "not_available" 3 "error" ;
VAL_ 848 RDR_Stat_blindness_det 0 "no_blindness_detected" 1 "blindness_detected" ;
VAL_ 848 RDR_Stat_Avail 0 "available" 1 "not_available" ;
VAL_ 848 RDR_Stat_Error 0 "no_stat_error" 1 "error" ;
VAL_ 849 RDR_Obj_01_RFF 0 "not_fused" ;
VAL_ 850 RDR_Obj_02_RFF 0 "not_fused" ;
VAL_ 851 RDR_Obj_03_RFF 0 "not_fused" ;
VAL_ 852 RDR_Obj_04_RFF 0 "not_fused" ;
